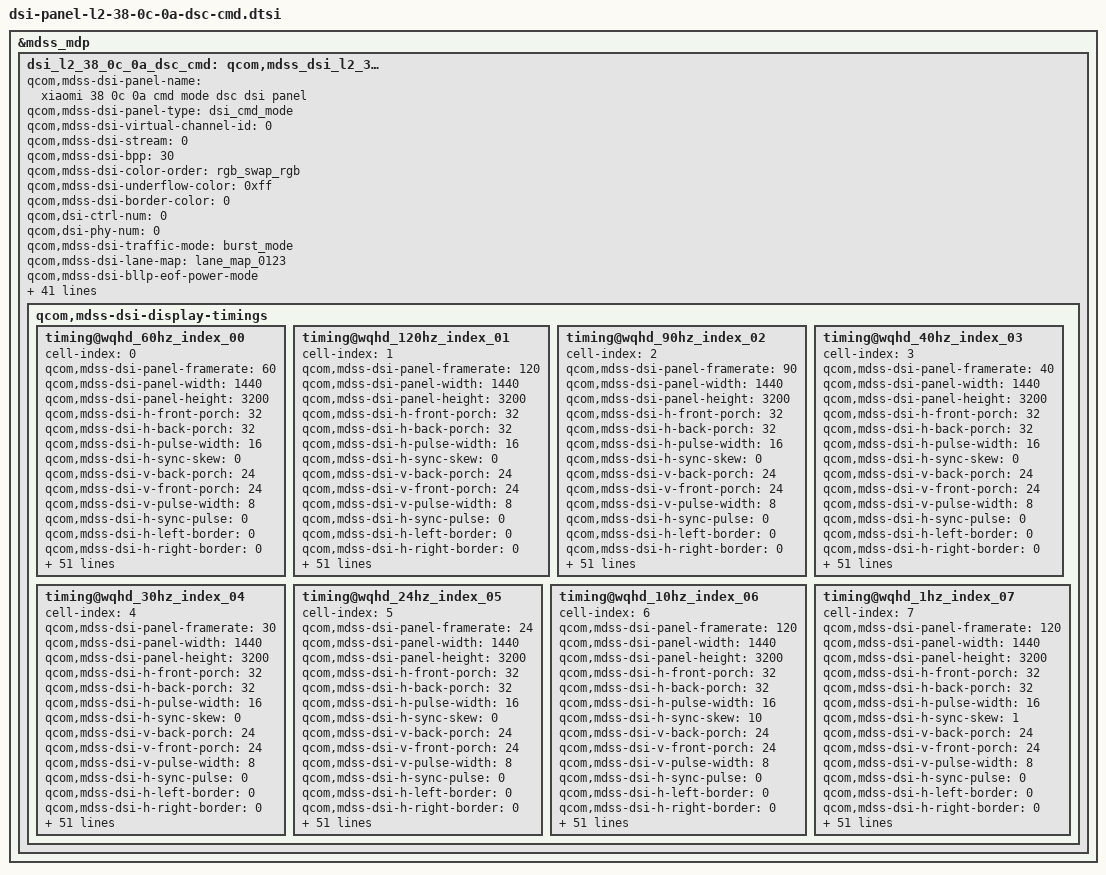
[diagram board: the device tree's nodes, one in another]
&mdss_mdp {
	dsi_l2_38_0c_0a_dsc_cmd: qcom,mdss_dsi_l2_38_0c_0a_dsc_cmd {
		qcom,mdss-dsi-panel-name = "xiaomi 38 0c 0a cmd mode dsc dsi panel";
		qcom,mdss-dsi-panel-type = "dsi_cmd_mode";
		qcom,mdss-dsi-virtual-channel-id = <0>;
		qcom,mdss-dsi-stream = <0>;
		qcom,mdss-dsi-bpp = <30>;
		qcom,mdss-dsi-color-order = "rgb_swap_rgb";
		qcom,mdss-dsi-underflow-color = <0xff>;
		qcom,mdss-dsi-border-color = <0>;
		qcom,dsi-ctrl-num = <0>;
		qcom,dsi-phy-num = <0>;

		qcom,mdss-dsi-traffic-mode = "burst_mode";
		qcom,mdss-dsi-lane-map = "lane_map_0123";
		qcom,mdss-dsi-bllp-eof-power-mode;
		qcom,mdss-dsi-bllp-power-mode;
		qcom,mdss-dsi-lane-0-state;
		qcom,mdss-dsi-lane-1-state;
		qcom,mdss-dsi-lane-2-state;
		qcom,mdss-dsi-lane-3-state;
		qcom,mdss-dsi-dma-trigger = "trigger_sw";
		qcom,mdss-dsi-mdp-trigger = "none";
		qcom,mdss-dsi-reset-sequence = <0 1>, <1 10>;
		qcom,mdss-pan-physical-width-dimension = <701>;
		qcom,mdss-pan-physical-height-dimension = <1558>;
		qcom,mdss-dsi-te-pin-select = <1>;
		qcom,mdss-dsi-wr-mem-start = <0x2c>;
		qcom,mdss-dsi-wr-mem-continue = <0x3c>;
		qcom,mdss-dsi-te-dcs-command = <1>;
		qcom,mdss-dsi-te-check-enable;
		qcom,mdss-dsi-te-using-te-pin;
		qcom,mdss-dsi-tx-eot-append;
		qcom,mdss-dsi-lp11-init;

		qcom,mdss-dsi-bl-inverted-dbv;
		qcom,mdss-dsi-panel-dimming-enabled;
		qcom,bl-update-flag = "delay_until_first_frame";

		qcom,mdss-dsi-panel-hdr-enabled;
		qcom,mdss-dsi-panel-hdr-color-primaries = <14500 15500 32000
			17000 15500 30000 8000 3000>;
		qcom,mdss-dsi-panel-peak-brightness = <4200000>;
		qcom,mdss-dsi-panel-blackness-level = <3230>;

		qcom,mdss-dsi-dma-schedule-line = <1>;
		qcom,mdss-dsi-dma-schedule-window = <50>;

		/* IRQF_ONESHOT | IRQF_TRIGGER_LOW */
		mi,esd-err-irq-gpio = <&tlmm 116 0x2008>;
		mi,panel-id = <0x00004C32 0x00380C00>;

		mi,local-hbm-enabled;
		mi,local-hbm-ui-ready-delay-num-frame = <4>; /* 4 frame */
		mi,fod-low-brightness-clone-threshold = <411>;
		mi,fod-low-brightness-lux-threshold = <1>;
		mi,need-fod-animal-in-normal-enabled;

		mi,panel-on-dimming-delay = <120>;
		mi,max-brightness-clone = <16383>;
		mi,normal-max-brightness-clone = <8191>;
		mi,thermal-dimming-flag;

		mi,doze-hbm-dbv-level = <229>;
		mi,doze-lbm-dbv-level = <16>;

		qcom,mdss-dsi-display-timings {
			timing@wqhd_60hz_index_00 {
				#include "dsi-panel-l2-38-0c-0a-dsc-cmd-common.dtsi"
				cell-index = <0>;
				qcom,mdss-dsi-panel-framerate = <60>;
				qcom,mdss-dsi-panel-width = <1440>;
				qcom,mdss-dsi-panel-height = <3200>;
				qcom,mdss-dsi-h-front-porch = <32>;
				qcom,mdss-dsi-h-back-porch = <32>;
				qcom,mdss-dsi-h-pulse-width = <16>;
				qcom,mdss-dsi-h-sync-skew = <0>;
				qcom,mdss-dsi-v-back-porch = <24>;
				qcom,mdss-dsi-v-front-porch = <24>;
				qcom,mdss-dsi-v-pulse-width = <8>;
				qcom,mdss-dsi-h-sync-pulse = <0>;
				qcom,mdss-dsi-h-left-border = <0>;
				qcom,mdss-dsi-h-right-border = <0>;
				qcom,mdss-dsi-v-top-border = <0>;
				qcom,mdss-dsi-v-bottom-border = <0>;
				qcom,mdss-dsi-panel-clockrate = <1360000000>;
				qcom,mdss-dsi-panel-jitter = <0x5 0x1>;
				qcom,mdss-mdp-transfer-time-us = <7300>;

				/* the cmd sequence sync TE */
				mi,mdss-dsi-exit-90fps-timing-switch-command = [
					/* CASET/PASET Setting 1440*3200 */
					39 00 00 60 00 00 05 2A 00 00 05 9F
					39 00 00 60 00 00 05 2B 00 00 0C 7F
					/* Scaler Setting 1440*3200 */
					39 00 00 60 00 00 03 F0 5A 5A
					39 00 00 60 00 00 02 C3 0C
					39 00 00 60 00 00 03 F0 A5 A5
					/* 90hz -> 120hz */
					39 00 00 60 00 00 03 F0 5A 5A
					39 00 00 60 00 00 02 60 00     /* 120hz */
					39 00 00 60 00 00 02 F7 0F
					39 00 00 20 05 00 03 F0 5A 5A  /* 1 sync */
					39 00 00 60 00 00 04 B0 00 08 CB
					39 00 00 60 00 00 02 CB 27
					39 00 00 60 00 00 02 F7 0F
					39 00 00 20 05 00 03 F0 A5 A5  /* 2 sync */
					39 00 00 60 00 00 03 F0 5A 5A
					39 00 00 60 00 00 02 60 01     /* 0x00:120Hz, 0x01:60Hz, 0x03:30Hz, 0x07:10Hz */
					39 00 00 20 00 00 02 F7 0F     /* 2 sync */
				];
				mi,mdss-dsi-exit-90fps-timing-switch-command-state = "dsi_hs_mode";

				qcom,mdss-dsi-timing-switch-command = [
					/* CASET/PASET Setting 1440*3200 */
					39 00 00 40 00 00 05 2A 00 00 05 9F
					39 00 00 40 00 00 05 2B 00 00 0C 7F
					/* Scaler Setting 1440*3200 */
					39 00 00 40 00 00 03 F0 5A 5A
					39 00 00 40 00 00 02 C3 0C
					39 00 00 40 00 00 03 F0 A5 A5
					/* FIX TE OFF */
					39 00 00 40 00 00 03 F0 5A 5A
					15 00 00 40 00 00 02 B9 00
					39 00 00 40 00 00 04 B0 00 06 B9
					39 00 00 40 00 00 07 B9 00 00 00 00 00 00
					39 00 00 40 00 00 02 F7 0F
					39 00 00 40 00 00 03 F0 A5 A5
					/* 60Hz Setting(force increasing off) */
					39 00 00 40 00 00 03 F0 5A 5A
					39 00 00 40 00 00 04 B0 00 08 CB
					39 00 00 40 00 00 02 CB 27
					39 00 00 40 00 00 03 BD 21 82
					39 00 00 40 00 00 04 B0 00 10 BD
					39 00 00 40 00 00 02 BD 00
					39 00 00 40 00 00 04 B0 00 21 BD
					39 00 00 40 00 00 0F BD 03 00 06 00 09 00 0C 00 0F 00 15 00 21 00
					39 00 00 40 00 00 04 B0 00 61 BD
					39 00 00 40 00 00 0A BD 04 00 08 00 0C 00 10 00 74
					39 00 00 40 00 00 04 B0 00 12 BD
					39 00 00 40 00 00 02 BD 01
					39 00 00 40 00 00 04 B0 00 16 BD
					39 00 00 40 00 00 03 BD 00 00    /* Step delay */
					39 00 00 40 00 00 02 BD 21       /* Manual mode */
					39 00 00 40 00 00 02 60 01       /* 0x00:120Hz, 0x01:60Hz, 0x03:30Hz, 0x07:10Hz */
					39 00 00 40 00 00 02 F7 0F
					39 00 00 00 00 00 03 F0 A5 A5
				];
				qcom,mdss-dsi-timing-switch-command-state = "dsi_hs_mode";

				qcom,mdss-dsi-on-command = [
					/* DSC PPS Setting */
					39 00 00 00 00 00 81 9E
						11 00 00 AB 30 80 0C 80 05 A0 00 19 02 D0 02 D0
						02 00 02 68 00 20 02 BE 00 0A 00 0C 04 00 03 0D
						18 00 10 F0 07 10 20 00 06 0F 0F 33 0E 1C 2A 38
						46 54 62 69 70 77 79 7B 7D 7E 01 02 22 00 2A 40
						2A BE 3A FC 3A FA 3A F8 3B 38 3B 78 3B B6 4B F6
						4C 34 4C 74 5C 74 8C F4 00 00 00 00 00 00 00 00
						00 00 00 00 00 00 00 00 00 00 00 00 00 00 00 00
						00 00 00 00 00 00 00 00 00 00 00 00 00 00 00 00
					/* DSC Compression Enable */
					15 00 00 00 00 00 02 9D 01
					/* Sleep Out */
					05 00 00 00 78 00 02 11 00
					/* Common Setting */
					/* TE(Vsync) On */
					15 00 00 00 00 00 02 35 00
					/* CASET/PASET Setting 1440*3200 */
					39 00 00 00 00 00 05 2A 00 00 05 9F
					39 00 00 00 00 00 05 2B 00 00 0C 7F
					/* Scaler Setting 1440*3200 */
					39 00 00 40 00 00 03 F0 5A 5A
					15 00 00 40 00 00 02 C3 0C    /* 0x0C:WQHD+(1440x3200), 0x0D:FHD+(1080x2400) */
					39 00 00 00 00 00 03 F0 A5 A5
					/* FIX TE OFF */
					39 00 00 40 00 00 03 F0 5A 5A
					15 00 00 40 00 00 02 B9 00
					39 00 00 40 00 00 04 B0 00 06 B9
					39 00 00 40 00 00 07 B9 00 00 00 00 00 00
					39 00 00 40 00 00 02 F7 0F
					39 00 00 00 00 00 03 F0 A5 A5
					/* 60Hz Setting(force increasing off) */
					39 00 00 40 00 00 03 F0 5A 5A
					39 00 00 40 00 00 04 B0 00 08 CB
					39 00 00 40 00 00 02 CB 27
					39 00 00 40 00 00 03 BD 21 82
					39 00 00 40 00 00 04 B0 00 10 BD
					39 00 00 40 00 00 02 BD 00
					39 00 00 40 00 00 04 B0 00 21 BD
					39 00 00 40 00 00 0F BD 03 00 06 00 09 00 0C 00 0F 00 15 00 21 00
					39 00 00 40 00 00 04 B0 00 61 BD
					39 00 00 40 00 00 0A BD 04 00 08 00 0C 00 10 00 74
					39 00 00 40 00 00 04 B0 00 12 BD
					39 00 00 40 00 00 02 BD 01
					39 00 00 40 00 00 04 B0 00 16 BD
					39 00 00 40 00 00 03 BD 00 00    /* Step delay */
					39 00 00 40 00 00 02 BD 21       /* Manual mode */
					39 00 00 40 00 00 02 60 01       /* 0x00:120Hz, 0x01:60Hz, 0x03:30Hz, 0x07:10Hz */
					39 00 00 40 00 00 02 F7 0F
					39 00 00 00 00 00 03 F0 A5 A5
					/* Dimming Setting*/
					39 00 00 00 00 00 03 F0 5A 5A
					39 00 00 00 00 00 04 B0 00 0D 63
					39 00 00 00 00 00 02 63 20
					39 00 00 00 00 00 04 B0 00 0C 63
					39 00 00 00 00 00 02 63 20
					39 00 00 00 00 00 03 F0 A5 A5
					39 00 00 00 00 00 02 53 20
					39 00 00 00 00 00 03 51 00 00
					39 00 00 00 00 00 02 F7 0F
					39 00 00 00 00 00 03 F0 A5 A5
					/* ESD Error Flag, Normal High, Error Low */
					39 00 00 40 00 00 03 F0 5A 5A
					39 00 00 40 00 00 04 B0 00 47 F4
					15 00 00 40 00 00 02 F4 01
					39 00 00 40 00 00 04 ED 47 05 20
					39 00 00 00 00 00 03 F0 A5 A5
					/* touch sync enable */
					39 00 00 40 00 00 03 F0 5A 5A
					39 00 00 40 00 00 03 F1 5A 5A
					39 00 00 40 00 00 04 B0 00 22 B9
					39 00 00 40 00 00 03 B9 B1 A1
					39 00 00 40 00 00 04 B0 00 05 F2
					15 00 00 40 00 00 02 F2 52
					15 00 00 40 00 00 02 F7 0F
					39 00 00 40 00 00 03 F1 A5 A5
					39 00 00 40 00 00 03 F0 A5 A5
					39 00 00 40 00 00 03 F0 5A 5A
					39 00 00 40 00 00 02 C3 0C
					39 00 00 00 00 00 03 F0 A5 A5
					/* DIA setting */
					39 00 00 40 00 00 03 F0 5A 5A
					39 00 00 40 00 00 04 B0 02 67 1D
					39 00 00 40 00 00 02 1D 81
					39 00 00 00 00 00 03 F0 A5 A5
					/* OPEC code */
					39 00 00 40 00 00 03 F0 5A 5A
					39 00 00 40 00 00 04 B0 00 52 1F
					39 00 00 40 00 00 02 1F 02
					39 00 00 40 00 00 04 B0 00 53 1F
					39 00 00 40 00 00 5F 1F
						07 01 00 02 B9 02 BA 07 A2 07 AA 12 C0 12 C1 1A
						BA 1B C0 1F E0 00 53 00 C3 03 43 07 A0 07 A1 07
						A2 07 A6 07 A8 07 AA 07 AC 07 AE 07 B0 07 B2 07
						B4 07 B6 00 03 00 A4 00 C0 00 D1 01 86 03 FF 07
						FF 30 30 35 40 35 30 40 40 35 80 80 80 0A 0F 14
						18 1E 3A 78 80 80 80 80 80 80 80 80 01 B1
					39 00 00 40 00 00 04 B0 00 78 BD
					39 00 00 40 00 00 02 BD 10
					39 00 00 00 00 00 02 F7 0F
					39 00 00 00 00 00 03 F0 A5 A5
					/* Display On */
					05 00 00 00 00 00 02 29 00
				];
				qcom,mdss-dsi-on-command-state = "dsi_lp_mode";

				qcom,mdss-dsi-nolp-command = [
					39 00 00 40 00 00 03 F0 5A 5A
					15 00 00 40 00 00 02 53 20
					39 00 00 40 00 00 03 51 00 00
					39 00 00 00 22 00 03 F0 A5 A5
					/* 60Hz Setting(force increasing off) */
					39 00 00 40 00 00 03 F0 5A 5A
					39 00 00 40 00 00 04 B0 00 08 CB
					39 00 00 40 00 00 02 CB 27
					39 00 00 40 00 00 03 BD 21 82
					39 00 00 40 00 00 04 B0 00 10 BD
					39 00 00 40 00 00 02 BD 00
					39 00 00 40 00 00 04 B0 00 21 BD
					39 00 00 40 00 00 0F BD 03 00 06 00 09 00 0C 00 0F 00 15 00 21 00
					39 00 00 40 00 00 04 B0 00 61 BD
					39 00 00 40 00 00 0A BD 04 00 08 00 0C 00 10 00 74
					39 00 00 40 00 00 04 B0 00 12 BD
					39 00 00 40 00 00 02 BD 01
					39 00 00 40 00 00 04 B0 00 16 BD
					39 00 00 40 00 00 03 BD 00 00    /* Step delay */
					39 00 00 40 00 00 02 BD 21       /* Manual mode */
					39 00 00 40 00 00 02 60 01       /* 0x00:120Hz, 0x01:60Hz, 0x03:30Hz, 0x07:10Hz */
					39 00 00 40 00 00 02 F7 0F
					39 00 00 00 00 00 03 F0 A5 A5
				];
				qcom,mdss-dsi-nolp-command-state = "dsi_lp_mode";

				mi,mdss-dsi-doze-hbm-command = [
					/* 120Hz Setting(force increasing off) */
					39 00 00 40 00 00 03 F0 5A 5A
					39 00 00 40 00 00 04 B0 00 08 CB
					39 00 00 40 00 00 02 CB 27
					39 00 00 40 00 00 03 BD 21 82
					39 00 00 40 00 00 04 B0 00 10 BD
					39 00 00 40 00 00 02 BD 00
					39 00 00 40 00 00 04 B0 00 21 BD
					39 00 00 40 00 00 0F BD 03 00 06 00 09 00 0C 00 0F 00 15 00 21 00
					39 00 00 40 00 00 04 B0 00 61 BD
					39 00 00 40 00 00 0A BD 04 00 08 00 0C 00 10 00 74
					39 00 00 40 00 00 04 B0 00 12 BD
					39 00 00 40 00 00 02 BD 01
					39 00 00 40 00 00 04 B0 00 16 BD
					39 00 00 40 00 00 03 BD 00 00    /* Step delay */
					39 00 00 40 00 00 02 BD 21       /* Manual mode */
					39 00 00 40 00 00 02 60 00       /* 0x00:120Hz, 0x01:60Hz, 0x03:30Hz, 0x07:10Hz */
					39 00 00 40 00 00 02 F7 0F
					39 00 00 00 11 00 03 F0 A5 A5
					/* AOD setting */
					39 00 00 20 00 00 03 51 00 E5
					39 00 00 20 00 00 03 51 00 E5
					39 00 00 60 00 00 03 F0 5A 5A
					39 00 00 60 00 00 02 BB 31
					39 00 00 60 00 00 02 F7 0F
					39 00 00 60 00 00 02 53 24
					39 00 00 20 00 00 03 51 07 FE
				];
				mi,mdss-dsi-doze-lbm-command = [
					/* 120Hz Setting(force increasing off) */
					39 00 00 40 00 00 03 F0 5A 5A
					39 00 00 40 00 00 04 B0 00 08 CB
					39 00 00 40 00 00 02 CB 27
					39 00 00 40 00 00 03 BD 21 82
					39 00 00 40 00 00 04 B0 00 10 BD
					39 00 00 40 00 00 02 BD 00
					39 00 00 40 00 00 04 B0 00 21 BD
					39 00 00 40 00 00 0F BD 03 00 06 00 09 00 0C 00 0F 00 15 00 21 00
					39 00 00 40 00 00 04 B0 00 61 BD
					39 00 00 40 00 00 0A BD 04 00 08 00 0C 00 10 00 74
					39 00 00 40 00 00 04 B0 00 12 BD
					39 00 00 40 00 00 02 BD 01
					39 00 00 40 00 00 04 B0 00 16 BD
					39 00 00 40 00 00 03 BD 00 00    /* Step delay */
					39 00 00 40 00 00 02 BD 21       /* Manual mode */
					39 00 00 40 00 00 02 60 00       /* 0x00:120Hz, 0x01:60Hz, 0x03:30Hz, 0x07:10Hz */
					39 00 00 40 00 00 02 F7 0F
					39 00 00 00 11 00 03 F0 A5 A5
					/* AOD setting */
					39 00 00 20 00 00 03 51 00 10
					39 00 00 20 00 00 03 51 00 10
					39 00 00 60 00 00 03 F0 5A 5A
					39 00 00 60 00 00 02 BB 31
					15 00 00 60 00 00 02 F7 0F
					39 00 00 20 00 00 02 53 24
					39 00 00 00 00 00 03 51 00 F6
				];
				/* <mipi_address  update_index  update_length> */
				mi,mdss-dsi-doze-lbm-command-update = <0x53 23 1>;
				mi,mdss-dsi-doze-hbm-command-state = "dsi_lp_mode";
				mi,mdss-dsi-doze-lbm-command-state = "dsi_lp_mode";

				mi,mdss-dsi-doze-hbm-nolp-command = [
					39 00 00 60 00 00 03 51 04 29
					39 00 00 20 23 00 02 53 20
					39 00 00 00 00 00 03 51 00 E5
					/* 60Hz Setting(force increasing off) */
					39 00 00 40 00 00 03 F0 5A 5A
					39 00 00 40 00 00 04 B0 00 08 CB
					39 00 00 40 00 00 02 CB 27
					39 00 00 40 00 00 03 BD 21 82
					39 00 00 40 00 00 04 B0 00 10 BD
					39 00 00 40 00 00 02 BD 00
					39 00 00 40 00 00 04 B0 00 21 BD
					39 00 00 40 00 00 0F BD 03 00 06 00 09 00 0C 00 0F 00 15 00 21 00
					39 00 00 40 00 00 04 B0 00 61 BD
					39 00 00 40 00 00 0A BD 04 00 08 00 0C 00 10 00 74
					39 00 00 40 00 00 04 B0 00 12 BD
					39 00 00 40 00 00 02 BD 01
					39 00 00 40 00 00 04 B0 00 16 BD
					39 00 00 40 00 00 03 BD 00 00    /* Step delay */
					39 00 00 40 00 00 02 BD 21       /* Manual mode */
					39 00 00 40 00 00 02 60 01       /* 0x00:120Hz, 0x01:60Hz, 0x03:30Hz, 0x07:10Hz */
					39 00 00 40 00 00 02 F7 0F
					39 00 00 00 00 00 03 F0 A5 A5
				];
				mi,mdss-dsi-doze-hbm-nolp-command-state = "dsi_lp_mode";

				mi,mdss-dsi-doze-lbm-nolp-command = [
					39 00 00 40 00 00 03 F0 5A 5A
					15 00 00 40 00 00 02 53 20
					39 00 00 40 00 00 03 51 00 10
					39 00 00 00 22 00 03 F0 A5 A5
					/* 60Hz Setting(force increasing off) */
					39 00 00 40 00 00 03 F0 5A 5A
					39 00 00 40 00 00 04 B0 00 08 CB
					39 00 00 40 00 00 02 CB 27
					39 00 00 40 00 00 03 BD 21 82
					39 00 00 40 00 00 04 B0 00 10 BD
					39 00 00 40 00 00 02 BD 00
					39 00 00 40 00 00 04 B0 00 21 BD
					39 00 00 40 00 00 0F BD 03 00 06 00 09 00 0C 00 0F 00 15 00 21 00
					39 00 00 40 00 00 04 B0 00 61 BD
					39 00 00 40 00 00 0A BD 04 00 08 00 0C 00 10 00 74
					39 00 00 40 00 00 04 B0 00 12 BD
					39 00 00 40 00 00 02 BD 01
					39 00 00 40 00 00 04 B0 00 16 BD
					39 00 00 40 00 00 03 BD 00 00    /* Step delay */
					39 00 00 40 00 00 02 BD 21       /* Manual mode */
					39 00 00 40 00 00 02 60 01       /* 0x00:120Hz, 0x01:60Hz, 0x03:30Hz, 0x07:10Hz */
					39 00 00 40 00 00 02 F7 0F
					39 00 00 00 00 00 03 F0 A5 A5
				];
				mi,mdss-dsi-doze-lbm-nolp-command-state = "dsi_lp_mode";

				mi,mdss-dsi-local-hbm-hlpm-white-1000nit-command = [
					/* nolp */
					39 00 00 40 00 00 03 F0 5A 5A
					39 00 00 40 00 00 02 53 20
					39 00 00 00 22 00 03 F0 A5 A5
					/* 60Hz Setting(force increasing off) */
					39 00 00 40 00 00 03 F0 5A 5A
					39 00 00 40 00 00 04 B0 00 08 CB
					39 00 00 40 00 00 02 CB 27
					39 00 00 40 00 00 03 BD 21 82
					39 00 00 40 00 00 04 B0 00 10 BD
					39 00 00 40 00 00 02 BD 00
					39 00 00 40 00 00 04 B0 00 21 BD
					39 00 00 40 00 00 0F BD 03 00 06 00 09 00 0C 00 0F 00 15 00 21 00
					39 00 00 40 00 00 04 B0 00 61 BD
					39 00 00 40 00 00 0A BD 04 00 08 00 0C 00 10 00 74
					39 00 00 40 00 00 04 B0 00 12 BD
					39 00 00 40 00 00 02 BD 01
					39 00 00 40 00 00 04 B0 00 16 BD
					39 00 00 40 00 00 03 BD 00 00    /* Step delay */
					39 00 00 40 00 00 02 BD 21       /* Manual mode */
					39 00 00 40 00 00 02 60 01       /* 0x00:120Hz, 0x01:60Hz, 0x03:30Hz, 0x07:10Hz */
					39 00 00 40 00 00 02 F7 0F
					39 00 00 00 00 00 03 F0 A5 A5
					/* Local HBM setting */
					39 00 00 40 00 00 03 F0 5A 5A
					39 00 00 40 00 00 04 B0 01 DC 1F
					39 00 00 40 00 00 10 1F
						02 00 00 00 00 24 09 1F 35 FA 3F 2D 09 AF 86
					39 00 00 40 00 00 04 B0 02 AC 66
					39 00 00 40 00 00 03 66 0F FF
					39 00 00 40 00 00 04 B0 01 6D 66
					39 00 00 40 00 00 13 66
						00 40 14 02 90 52 0A 41 48 1C 27 FF FF FF FF FF
						FF FF
					39 00 00 40 00 00 04 B0 01 59 66
					39 00 00 40 00 00 0B 66
						08 7A 9F F5 AF 08 7A 9F F5 AF    /* 1100nit */
					39 00 00 40 00 00 04 B0 01 B5 66
					39 00 00 40 00 00 37 66
						14 01 DE 2A 43 A2 4F 66 CC 80 08 00 80 08 00 80
						08 00 14 01 DE 2A 43 A2 4F 66 CC 80 08 00 80 08
						00 80 08 00 14 01 DE 2A 43 A2 4F 66 CC 80 08 00
						80 08 00 80 08 00
					39 00 00 40 00 00 04 B0 01 EB 66
					39 00 00 40 00 00 37 66
						14 61 EE 2A 43 A2 4F 66 CC 80 08 00 80 08 00 80
						08 00 14 61 EE 2A 43 A2 4F 66 CC 80 08 00 80 08
						00 80 08 00 14 61 EE 2A 43 A2 4F 66 CC 80 08 00
						80 08 00 80 08 00
					39 00 00 40 00 00 02 53 30    /* 0x30 Local HBM transition */
					39 00 00 00 00 00 03 F0 A5 A5
				];
				mi,mdss-dsi-local-hbm-hlpm-white-1000nit-command-state = "dsi_hs_mode";

				mi,mdss-dsi-local-hbm-hlpm-white-110nit-command = [
					/* nolp */
					39 00 00 40 00 00 03 F0 5A 5A
					39 00 00 40 00 00 02 53 20
					39 00 00 00 22 00 03 F0 A5 A5
					/* 60Hz Setting(force increasing off) */
					39 00 00 40 00 00 03 F0 5A 5A
					39 00 00 40 00 00 04 B0 00 08 CB
					39 00 00 40 00 00 02 CB 27
					39 00 00 40 00 00 03 BD 21 82
					39 00 00 40 00 00 04 B0 00 10 BD
					39 00 00 40 00 00 02 BD 00
					39 00 00 40 00 00 04 B0 00 21 BD
					39 00 00 40 00 00 0F BD 03 00 06 00 09 00 0C 00 0F 00 15 00 21 00
					39 00 00 40 00 00 04 B0 00 61 BD
					39 00 00 40 00 00 0A BD 04 00 08 00 0C 00 10 00 74
					39 00 00 40 00 00 04 B0 00 12 BD
					39 00 00 40 00 00 02 BD 01
					39 00 00 40 00 00 04 B0 00 16 BD
					39 00 00 40 00 00 03 BD 00 00    /* Step delay */
					39 00 00 40 00 00 02 BD 21       /* Manual mode */
					39 00 00 40 00 00 02 60 01       /* 0x00:120Hz, 0x01:60Hz, 0x03:30Hz, 0x07:10Hz */
					39 00 00 40 00 00 02 F7 0F
					39 00 00 00 00 00 03 F0 A5 A5
					/* Local HBM setting */
					39 00 00 40 00 00 03 F0 5A 5A
					39 00 00 40 00 00 04 B0 01 DC 1F
					39 00 00 40 00 00 10 1F
						02 00 00 00 00 24 09 1F 35 FA 3F 2D 09 AF 86
					39 00 00 40 00 00 04 B0 02 AC 66
					39 00 00 40 00 00 03 66 0F FF
					39 00 00 40 00 00 04 B0 01 6D 66
					39 00 00 40 00 00 13 66
						00 40 14 02 90 52 0A 41 48 1C 27 FF FF FF FF FF
						FF FF
					39 00 00 40 00 00 04 B0 01 59 66
					39 00 00 40 00 00 0B 66
						05 56 E0 83 E8 05 56 E0 83 E8    /* 110nit */
					39 00 00 40 00 00 04 B0 01 B5 66
					39 00 00 40 00 00 37 66
						14 01 DE 2A 43 A2 4F 66 CC 80 08 00 80 08 00 80
						08 00 14 01 DE 2A 43 A2 4F 66 CC 80 08 00 80 08
						00 80 08 00 14 01 DE 2A 43 A2 4F 66 CC 80 08 00
						80 08 00 80 08 00
					39 00 00 40 00 00 04 B0 01 EB 66
					39 00 00 40 00 00 37 66
						14 61 EE 2A 43 A2 4F 66 CC 80 08 00 80 08 00 80
						08 00 14 61 EE 2A 43 A2 4F 66 CC 80 08 00 80 08
						00 80 08 00 14 61 EE 2A 43 A2 4F 66 CC 80 08 00
						80 08 00 80 08 00
					39 00 00 40 00 00 02 53 30    /* 0x30 Local HBM transition */
					39 00 00 00 00 00 03 F0 A5 A5
				];
				mi,mdss-dsi-local-hbm-hlpm-white-110nit-command-state = "dsi_hs_mode";

				qcom,compression-mode = "dsc";
				qcom,mdss-dsc-slice-height = <50>;
				qcom,mdss-dsc-slice-width = <720>;
				qcom,mdss-dsc-slice-per-pkt = <2>;
				qcom,mdss-dsc-bit-per-component = <10>;
				qcom,mdss-dsc-bit-per-pixel = <8>;
				qcom,mdss-dsc-block-prediction-enable;
			};

			timing@wqhd_120hz_index_01 {
				#include "dsi-panel-l2-38-0c-0a-dsc-cmd-common.dtsi"
				cell-index = <1>;
				qcom,mdss-dsi-panel-framerate = <120>;
				qcom,mdss-dsi-panel-width = <1440>;
				qcom,mdss-dsi-panel-height = <3200>;
				qcom,mdss-dsi-h-front-porch = <32>;
				qcom,mdss-dsi-h-back-porch = <32>;
				qcom,mdss-dsi-h-pulse-width = <16>;
				qcom,mdss-dsi-h-sync-skew = <0>;
				qcom,mdss-dsi-v-back-porch = <24>;
				qcom,mdss-dsi-v-front-porch = <24>;
				qcom,mdss-dsi-v-pulse-width = <8>;
				qcom,mdss-dsi-h-sync-pulse = <0>;
				qcom,mdss-dsi-h-left-border = <0>;
				qcom,mdss-dsi-h-right-border = <0>;
				qcom,mdss-dsi-v-top-border = <0>;
				qcom,mdss-dsi-v-bottom-border = <0>;
				qcom,mdss-dsi-panel-clockrate = <1360000000>;
				qcom,mdss-dsi-panel-jitter = <0x5 0x1>;
				qcom,mdss-mdp-transfer-time-us = <7300>;

				/* the cmd sequence sync TE */
				mi,mdss-dsi-exit-90fps-timing-switch-command = [
					/* CASET/PASET Setting 1440*3200 */
					39 00 00 60 00 00 05 2A 00 00 05 9F
					39 00 00 60 00 00 05 2B 00 00 0C 7F
					/* Scaler Setting 1440*3200 */
					39 00 00 60 00 00 03 F0 5A 5A
					39 00 00 60 00 00 02 C3 0C
					39 00 00 60 00 00 03 F0 A5 A5
					/* 90hz -> 120hz */
					39 00 00 60 00 00 03 F0 5A 5A
					39 00 00 60 00 00 02 60 00        /* 120hz */
					39 00 00 20 05 00 02 F7 0F        /* 1 sync */
					39 00 00 60 00 00 04 B0 00 08 CB
					39 00 00 60 00 00 02 CB 27
					39 00 00 60 00 00 02 F7 0F
					39 00 00 20 00 00 03 F0 A5 A5     /* 2 sync */
				];
				mi,mdss-dsi-exit-90fps-timing-switch-command-state = "dsi_hs_mode";

				qcom,mdss-dsi-timing-switch-command = [
					/* CASET/PASET Setting 1440*3200 */
					39 00 00 40 00 00 05 2A 00 00 05 9F
					39 00 00 40 00 00 05 2B 00 00 0C 7F
					/* Scaler Setting 1440*3200 */
					39 00 00 40 00 00 03 F0 5A 5A
					39 00 00 40 00 00 02 C3 0C
					39 00 00 40 00 00 03 F0 A5 A5
					/* FIX TE OFF */
					39 00 00 40 00 00 03 F0 5A 5A
					15 00 00 40 00 00 02 B9 00
					39 00 00 40 00 00 04 B0 00 06 B9
					39 00 00 40 00 00 07 B9 00 00 00 00 00 00
					39 00 00 40 00 00 02 F7 0F
					39 00 00 40 00 00 03 F0 A5 A5
					/* 120Hz Setting(force increasing off) */
					39 00 00 40 00 00 03 F0 5A 5A
					39 00 00 40 00 00 04 B0 00 08 CB
					39 00 00 40 00 00 02 CB 27
					39 00 00 40 00 00 03 BD 21 82
					39 00 00 40 00 00 04 B0 00 10 BD
					39 00 00 40 00 00 02 BD 00
					39 00 00 40 00 00 04 B0 00 21 BD
					39 00 00 40 00 00 0F BD 03 00 06 00 09 00 0C 00 0F 00 15 00 21 00
					39 00 00 40 00 00 04 B0 00 61 BD
					39 00 00 40 00 00 0A BD 04 00 08 00 0C 00 10 00 74
					39 00 00 40 00 00 04 B0 00 12 BD
					39 00 00 40 00 00 02 BD 01
					39 00 00 40 00 00 04 B0 00 16 BD
					39 00 00 40 00 00 03 BD 00 00    /* Step delay */
					39 00 00 40 00 00 02 BD 21       /* Manual mode */
					39 00 00 40 00 00 02 60 00       /* 0x00:120Hz, 0x01:60Hz, 0x03:30Hz, 0x07:10Hz */
					39 00 00 40 00 00 02 F7 0F
					39 00 00 00 00 00 03 F0 A5 A5
				];
				qcom,mdss-dsi-timing-switch-command-state = "dsi_hs_mode";

				qcom,mdss-dsi-on-command = [
					/* DSC PPS Setting */
					39 00 00 00 00 00 81 9E
						11 00 00 AB 30 80 0C 80 05 A0 00 19 02 D0 02 D0
						02 00 02 68 00 20 02 BE 00 0A 00 0C 04 00 03 0D
						18 00 10 F0 07 10 20 00 06 0F 0F 33 0E 1C 2A 38
						46 54 62 69 70 77 79 7B 7D 7E 01 02 22 00 2A 40
						2A BE 3A FC 3A FA 3A F8 3B 38 3B 78 3B B6 4B F6
						4C 34 4C 74 5C 74 8C F4 00 00 00 00 00 00 00 00
						00 00 00 00 00 00 00 00 00 00 00 00 00 00 00 00
						00 00 00 00 00 00 00 00 00 00 00 00 00 00 00 00
					/* DSC Compression Enable */
					15 00 00 00 00 00 02 9D 01
					/* Sleep Out */
					05 00 00 00 78 00 02 11 00
					/* Common Setting */
					/* TE(Vsync) On */
					15 00 00 00 00 00 02 35 00
					/* CASET/PASET Setting 1440*3200 */
					39 00 00 00 00 00 05 2A 00 00 05 9F
					39 00 00 00 00 00 05 2B 00 00 0C 7F
					/* Scaler Setting 1440*3200 */
					39 00 00 40 00 00 03 F0 5A 5A
					15 00 00 40 00 00 02 C3 0C    /* 0x0C:WQHD+(1440x3200), 0x0D:FHD+(1080x2400) */
					39 00 00 00 00 00 03 F0 A5 A5
					/* FIX TE OFF */
					39 00 00 40 00 00 03 F0 5A 5A
					15 00 00 40 00 00 02 B9 00
					39 00 00 40 00 00 04 B0 00 06 B9
					39 00 00 40 00 00 07 B9 00 00 00 00 00 00
					39 00 00 40 00 00 02 F7 0F
					39 00 00 00 00 00 03 F0 A5 A5
					/* 120Hz Setting(force increasing off) */
					39 00 00 40 00 00 03 F0 5A 5A
					39 00 00 40 00 00 04 B0 00 08 CB
					39 00 00 40 00 00 02 CB 27
					39 00 00 40 00 00 03 BD 21 82
					39 00 00 40 00 00 04 B0 00 10 BD
					39 00 00 40 00 00 02 BD 00
					39 00 00 40 00 00 04 B0 00 21 BD
					39 00 00 40 00 00 0F BD 03 00 06 00 09 00 0C 00 0F 00 15 00 21 00
					39 00 00 40 00 00 04 B0 00 61 BD
					39 00 00 40 00 00 0A BD 04 00 08 00 0C 00 10 00 74
					39 00 00 40 00 00 04 B0 00 12 BD
					39 00 00 40 00 00 02 BD 01
					39 00 00 40 00 00 04 B0 00 16 BD
					39 00 00 40 00 00 03 BD 00 00    /* Step delay */
					39 00 00 40 00 00 02 BD 21       /* Manual mode */
					39 00 00 40 00 00 02 60 00       /* 0x00:120Hz, 0x01:60Hz, 0x03:30Hz, 0x07:10Hz */
					39 00 00 40 00 00 02 F7 0F
					39 00 00 00 00 00 03 F0 A5 A5
					/* Dimming Setting*/
					39 00 00 00 00 00 03 F0 5A 5A
					39 00 00 00 00 00 04 B0 00 0D 63
					39 00 00 00 00 00 02 63 20
					39 00 00 00 00 00 04 B0 00 0C 63
					39 00 00 00 00 00 02 63 20
					39 00 00 00 00 00 03 F0 A5 A5
					39 00 00 00 00 00 02 53 20
					39 00 00 00 00 00 03 51 00 00
					39 00 00 00 00 00 02 F7 0F
					39 00 00 00 00 00 03 F0 A5 A5
					/* ESD Error Flag, Normal High, Error Low */
					39 00 00 40 00 00 03 F0 5A 5A
					39 00 00 40 00 00 04 B0 00 47 F4
					15 00 00 40 00 00 02 F4 01
					39 00 00 40 00 00 04 ED 47 05 20
					39 00 00 00 00 00 03 F0 A5 A5
					/* touch sync enable */
					39 00 00 40 00 00 03 F0 5A 5A
					39 00 00 40 00 00 03 F1 5A 5A
					39 00 00 40 00 00 04 B0 00 22 B9
					39 00 00 40 00 00 03 B9 B1 A1
					39 00 00 40 00 00 04 B0 00 05 F2
					15 00 00 40 00 00 02 F2 52
					15 00 00 40 00 00 02 F7 0F
					39 00 00 40 00 00 03 F1 A5 A5
					39 00 00 40 00 00 03 F0 A5 A5
					39 00 00 40 00 00 03 F0 5A 5A
					39 00 00 40 00 00 02 C3 0C
					39 00 00 00 00 00 03 F0 A5 A5
					/* DIA setting */
					39 00 00 40 00 00 03 F0 5A 5A
					39 00 00 40 00 00 04 B0 02 67 1D
					39 00 00 40 00 00 02 1D 81
					39 00 00 00 00 00 03 F0 A5 A5
					/* OPEC code */
					39 00 00 40 00 00 03 F0 5A 5A
					39 00 00 40 00 00 04 B0 00 52 1F
					39 00 00 40 00 00 02 1F 02
					39 00 00 40 00 00 04 B0 00 53 1F
					39 00 00 40 00 00 5F 1F
						07 01 00 02 B9 02 BA 07 A2 07 AA 12 C0 12 C1 1A
						BA 1B C0 1F E0 00 53 00 C3 03 43 07 A0 07 A1 07
						A2 07 A6 07 A8 07 AA 07 AC 07 AE 07 B0 07 B2 07
						B4 07 B6 00 03 00 A4 00 C0 00 D1 01 86 03 FF 07
						FF 30 30 35 40 35 30 40 40 35 80 80 80 0A 0F 14
						18 1E 3A 78 80 80 80 80 80 80 80 80 01 B1
					39 00 00 40 00 00 04 B0 00 78 BD
					39 00 00 40 00 00 02 BD 10
					39 00 00 00 00 00 02 F7 0F
					39 00 00 00 00 00 03 F0 A5 A5
					/* Display On */
					05 00 00 00 00 00 02 29 00
				];
				qcom,mdss-dsi-on-command-state = "dsi_lp_mode";

				qcom,mdss-dsi-nolp-command = [
					39 00 00 40 00 00 03 F0 5A 5A
					15 00 00 40 00 00 02 53 20
					39 00 00 40 00 00 03 51 00 00
					39 00 00 00 22 00 03 F0 A5 A5
				];
				qcom,mdss-dsi-nolp-command-state = "dsi_lp_mode";

				mi,mdss-dsi-doze-hbm-command = [
					39 00 00 20 00 00 03 51 00 E5
					39 00 00 20 00 00 03 51 00 E5
					39 00 00 60 00 00 03 F0 5A 5A
					39 00 00 60 00 00 02 BB 31
					39 00 00 60 00 00 02 F7 0F
					39 00 00 60 00 00 02 53 24
					39 00 00 20 00 00 03 51 07 FE
				];
				mi,mdss-dsi-doze-lbm-command = [
					39 00 00 20 00 00 03 51 00 10
					39 00 00 20 00 00 03 51 00 10
					39 00 00 60 00 00 03 F0 5A 5A
					39 00 00 60 00 00 02 BB 31
					15 00 00 60 00 00 02 F7 0F
					39 00 00 20 00 00 02 53 24
					39 00 00 00 00 00 03 51 00 F6
				];
				/* <mipi_address  update_index  update_length> */
				mi,mdss-dsi-doze-lbm-command-update = <0x53 5 1>;
				mi,mdss-dsi-doze-hbm-command-state = "dsi_lp_mode";
				mi,mdss-dsi-doze-lbm-command-state = "dsi_lp_mode";

				mi,mdss-dsi-doze-hbm-nolp-command = [
					39 00 00 60 00 00 03 51 04 29
					39 00 00 20 23 00 02 53 20
					39 00 00 00 00 00 03 51 00 E5
				];
				mi,mdss-dsi-doze-hbm-nolp-command-state = "dsi_lp_mode";

				mi,mdss-dsi-doze-lbm-nolp-command = [
					39 00 00 20 23 00 02 53 20
					39 00 00 00 00 00 03 51 00 10
				];
				mi,mdss-dsi-doze-lbm-nolp-command-state = "dsi_lp_mode";

				mi,mdss-dsi-local-hbm-hlpm-white-1000nit-command = [
					/* nolp */
					39 00 00 40 00 00 03 F0 5A 5A
					39 00 00 40 00 00 02 53 20
					39 00 00 00 22 00 03 F0 A5 A5
					/* Local HBM setting */
					39 00 00 40 00 00 03 F0 5A 5A
					39 00 00 40 00 00 04 B0 01 DC 1F
					39 00 00 40 00 00 10 1F
						02 00 00 00 00 24 09 1F 35 FA 3F 2D 09 AF 86
					39 00 00 40 00 00 04 B0 02 AC 66
					39 00 00 40 00 00 03 66 0F FF
					39 00 00 40 00 00 04 B0 01 6D 66
					39 00 00 40 00 00 13 66
						00 40 14 02 90 52 0A 41 48 1C 27 FF FF FF FF FF
						FF FF
					39 00 00 40 00 00 04 B0 01 59 66
					39 00 00 40 00 00 0B 66
						08 7A 9F F5 AF 08 7A 9F F5 AF    /* 1100nit */
					39 00 00 40 00 00 04 B0 01 B5 66
					39 00 00 40 00 00 37 66
						14 01 DE 2A 43 A2 4F 66 CC 80 08 00 80 08 00 80
						08 00 14 01 DE 2A 43 A2 4F 66 CC 80 08 00 80 08
						00 80 08 00 14 01 DE 2A 43 A2 4F 66 CC 80 08 00
						80 08 00 80 08 00
					39 00 00 40 00 00 04 B0 01 EB 66
					39 00 00 40 00 00 37 66
						14 61 EE 2A 43 A2 4F 66 CC 80 08 00 80 08 00 80
						08 00 14 61 EE 2A 43 A2 4F 66 CC 80 08 00 80 08
						00 80 08 00 14 61 EE 2A 43 A2 4F 66 CC 80 08 00
						80 08 00 80 08 00
					39 00 00 40 00 00 02 53 30    /* 0x30 Local HBM transition */
					39 00 00 00 00 00 03 F0 A5 A5
				];
				mi,mdss-dsi-local-hbm-hlpm-white-1000nit-command-state = "dsi_hs_mode";

				mi,mdss-dsi-local-hbm-hlpm-white-110nit-command = [
					/* nolp */
					39 00 00 40 00 00 03 F0 5A 5A
					39 00 00 40 00 00 02 53 20
					39 00 00 00 22 00 03 F0 A5 A5
					/* Local HBM setting */
					39 00 00 40 00 00 03 F0 5A 5A
					39 00 00 40 00 00 04 B0 01 DC 1F
					39 00 00 40 00 00 10 1F
						02 00 00 00 00 24 09 1F 35 FA 3F 2D 09 AF 86
					39 00 00 40 00 00 04 B0 02 AC 66
					39 00 00 40 00 00 03 66 0F FF
					39 00 00 40 00 00 04 B0 01 6D 66
					39 00 00 40 00 00 13 66
						00 40 14 02 90 52 0A 41 48 1C 27 FF FF FF FF FF
						FF FF
					39 00 00 40 00 00 04 B0 01 59 66
					39 00 00 40 00 00 0B 66
						05 56 E0 83 E8 05 56 E0 83 E8    /* 110nit */
					39 00 00 40 00 00 04 B0 01 B5 66
					39 00 00 40 00 00 37 66
						14 01 DE 2A 43 A2 4F 66 CC 80 08 00 80 08 00 80
						08 00 14 01 DE 2A 43 A2 4F 66 CC 80 08 00 80 08
						00 80 08 00 14 01 DE 2A 43 A2 4F 66 CC 80 08 00
						80 08 00 80 08 00
					39 00 00 40 00 00 04 B0 01 EB 66
					39 00 00 40 00 00 37 66
						14 61 EE 2A 43 A2 4F 66 CC 80 08 00 80 08 00 80
						08 00 14 61 EE 2A 43 A2 4F 66 CC 80 08 00 80 08
						00 80 08 00 14 61 EE 2A 43 A2 4F 66 CC 80 08 00
						80 08 00 80 08 00
					39 00 00 40 00 00 02 53 30    /* 0x30 Local HBM transition */
					39 00 00 00 00 00 03 F0 A5 A5
				];
				mi,mdss-dsi-local-hbm-hlpm-white-110nit-command-state = "dsi_hs_mode";

				qcom,compression-mode = "dsc";
				qcom,mdss-dsc-slice-height = <50>;
				qcom,mdss-dsc-slice-width = <720>;
				qcom,mdss-dsc-slice-per-pkt = <2>;
				qcom,mdss-dsc-bit-per-component = <10>;
				qcom,mdss-dsc-bit-per-pixel = <8>;
				qcom,mdss-dsc-block-prediction-enable;
			};

			timing@wqhd_90hz_index_02 {
				#include "dsi-panel-l2-38-0c-0a-dsc-cmd-common.dtsi"
				cell-index = <2>;
				qcom,mdss-dsi-panel-framerate = <90>;
				qcom,mdss-dsi-panel-width = <1440>;
				qcom,mdss-dsi-panel-height = <3200>;
				qcom,mdss-dsi-h-front-porch = <32>;
				qcom,mdss-dsi-h-back-porch = <32>;
				qcom,mdss-dsi-h-pulse-width = <16>;
				qcom,mdss-dsi-h-sync-skew = <0>;
				qcom,mdss-dsi-v-back-porch = <24>;
				qcom,mdss-dsi-v-front-porch = <24>;
				qcom,mdss-dsi-v-pulse-width = <8>;
				qcom,mdss-dsi-h-sync-pulse = <0>;
				qcom,mdss-dsi-h-left-border = <0>;
				qcom,mdss-dsi-h-right-border = <0>;
				qcom,mdss-dsi-v-top-border = <0>;
				qcom,mdss-dsi-v-bottom-border = <0>;
				qcom,mdss-dsi-panel-clockrate = <1360000000>;
				qcom,mdss-dsi-panel-jitter = <0x5 0x1>;
				qcom,mdss-mdp-transfer-time-us = <7300>;

				/* Display resolution switching */
				/* the cmd sequence sync TE */
				mi,mdss-dsi-exit-90fps-timing-switch-command = [
					/* 120Hz Setting(force increasing off) */
					39 00 00 60 00 00 03 F0 5A 5A
					39 00 00 60 00 00 04 B0 00 08 CB
					39 00 00 60 00 00 02 CB 27
					39 00 00 60 00 00 03 BD 21 82
					39 00 00 60 00 00 04 B0 00 10 BD
					39 00 00 60 00 00 02 BD 00
					39 00 00 60 00 00 04 B0 00 21 BD
					39 00 00 60 00 00 0F BD 03 00 06 00 09 00 0C 00 0F 00 15 00 21 00
					39 00 00 60 00 00 04 B0 00 61 BD
					39 00 00 60 00 00 0A BD 04 00 08 00 0C 00 10 00 74
					39 00 00 60 00 00 04 B0 00 12 BD
					39 00 00 60 00 00 02 BD 01
					39 00 00 60 00 00 04 B0 00 16 BD
					39 00 00 60 00 00 03 BD 00 00    /* Step delay */
					39 00 00 60 00 00 02 BD 21       /* Manual mode */
					39 00 00 60 00 00 02 60 00       /* 0x00:120Hz, 0x01:60Hz, 0x03:30Hz, 0x07:10Hz */
					39 00 00 60 00 00 02 F7 0F
					39 00 00 20 05 00 03 F0 A5 A5    /* 1 sync */
					/* CASET/PASET Setting 1440*3200 */
					39 00 00 60 00 00 05 2A 00 00 05 9F
					39 00 00 60 00 00 05 2B 00 00 0C 7F
					/* Scaler Setting 1440*3200 */
					39 00 00 60 00 00 03 F0 5A 5A
					39 00 00 60 00 00 02 C3 0C
					39 00 00 60 00 00 03 F0 A5 A5
					/* 90 hz setting */
					39 00 00 60 00 00 03 F0 5A 5A
					39 00 00 60 00 00 04 B0 00 08 CB
					39 00 00 60 00 00 02 CB A7
					39 00 00 60 00 00 04 B0 00 10 BD
					39 00 00 60 00 00 02 BD 00
					39 00 00 60 00 00 03 BD 21 82
					39 00 00 60 00 00 02 60 08       /* 0x08:90Hz */
					39 00 00 60 00 00 02 F7 0F
					39 00 00 20 00 00 03 F0 A5 A5    /* 2 sync */
				];
				mi,mdss-dsi-exit-90fps-timing-switch-command-state = "dsi_hs_mode";

				/* the cmd sequence sync TE */
				qcom,mdss-dsi-timing-switch-command = [
					/* CASET/PASET Setting 1440*3200 */
					39 00 00 60 00 00 05 2A 00 00 05 9F
					39 00 00 60 00 00 05 2B 00 00 0C 7F
					/* Scaler Setting 1440*3200 */
					39 00 00 60 00 00 03 F0 5A 5A
					39 00 00 60 00 00 02 C3 0C
					39 00 00 60 00 00 03 F0 A5 A5
					/* FIX TE OFF */
					39 00 00 60 00 00 03 F0 5A 5A
					15 00 00 60 00 00 02 B9 00
					39 00 00 60 00 00 04 B0 00 06 B9
					39 00 00 60 00 00 07 B9 00 00 00 00 00 00
					39 00 00 60 00 00 02 F7 0F
					39 00 00 60 00 00 03 F0 A5 A5
					/* 120Hz Setting(force increasing off) */
					39 00 00 60 00 00 03 F0 5A 5A
					39 00 00 60 00 00 04 B0 00 08 CB
					39 00 00 60 00 00 02 CB 27
					39 00 00 60 00 00 03 BD 21 82
					39 00 00 60 00 00 04 B0 00 10 BD
					39 00 00 60 00 00 02 BD 00
					39 00 00 60 00 00 04 B0 00 21 BD
					39 00 00 60 00 00 0F BD 03 00 06 00 09 00 0C 00 0F 00 15 00 21 00
					39 00 00 60 00 00 04 B0 00 61 BD
					39 00 00 60 00 00 0A BD 04 00 08 00 0C 00 10 00 74
					39 00 00 60 00 00 04 B0 00 12 BD
					39 00 00 60 00 00 02 BD 01
					39 00 00 60 00 00 04 B0 00 16 BD
					39 00 00 60 00 00 03 BD 00 00    /* Step delay */
					39 00 00 60 00 00 02 BD 21       /* Manual mode */
					39 00 00 60 00 00 02 60 00       /* 0x00:120Hz, 0x01:60Hz, 0x03:30Hz, 0x07:10Hz */
					39 00 00 20 05 00 02 F7 0F       /* 1 sync */
					/* 90 hz setting */
					39 00 00 60 00 00 03 F0 5A 5A
					39 00 00 60 00 00 04 B0 00 08 CB
					39 00 00 60 00 00 02 CB A7
					39 00 00 60 00 00 04 B0 00 10 BD
					39 00 00 60 00 00 02 BD 00
					39 00 00 60 00 00 03 BD 21 82
					39 00 00 60 00 00 02 60 08       /* 0x08:90Hz */
					39 00 00 60 00 00 02 F7 0F
					39 00 00 20 00 00 03 F0 A5 A5    /* 2 sync */
				];
				qcom,mdss-dsi-timing-switch-command-state = "dsi_hs_mode";

				qcom,mdss-dsi-on-command = [
					/* DSC PPS Setting */
					39 00 00 00 00 00 81 9E
						11 00 00 AB 30 80 0C 80 05 A0 00 19 02 D0 02 D0
						02 00 02 68 00 20 02 BE 00 0A 00 0C 04 00 03 0D
						18 00 10 F0 07 10 20 00 06 0F 0F 33 0E 1C 2A 38
						46 54 62 69 70 77 79 7B 7D 7E 01 02 22 00 2A 40
						2A BE 3A FC 3A FA 3A F8 3B 38 3B 78 3B B6 4B F6
						4C 34 4C 74 5C 74 8C F4 00 00 00 00 00 00 00 00
						00 00 00 00 00 00 00 00 00 00 00 00 00 00 00 00
						00 00 00 00 00 00 00 00 00 00 00 00 00 00 00 00
					/* DSC Compression Enable */
					15 00 00 00 00 00 02 9D 01
					/* Sleep Out */
					05 00 00 00 78 00 02 11 00
					/* Common Setting */
					/* TE(Vsync) On */
					15 00 00 00 00 00 02 35 00
					/* CASET/PASET Setting 1440*3200 */
					39 00 00 00 00 00 05 2A 00 00 05 9F
					39 00 00 00 00 00 05 2B 00 00 0C 7F
					/* Scaler Setting 1440*3200 */
					39 00 00 40 00 00 03 F0 5A 5A
					15 00 00 40 00 00 02 C3 0C    /* 0x0C:WQHD+(1440x3200), 0x0D:FHD+(1080x2400) */
					39 00 00 00 00 00 03 F0 A5 A5
					/* FIX TE OFF */
					39 00 00 40 00 00 03 F0 5A 5A
					15 00 00 40 00 00 02 B9 00
					39 00 00 40 00 00 04 B0 00 06 B9
					39 00 00 40 00 00 07 B9 00 00 00 00 00 00
					39 00 00 40 00 00 02 F7 0F
					39 00 00 00 00 00 03 F0 A5 A5
					/* 120Hz Setting(force increasing off) */
					39 00 00 40 00 00 03 F0 5A 5A
					39 00 00 40 00 00 04 B0 00 08 CB
					39 00 00 40 00 00 02 CB 27
					39 00 00 40 00 00 03 BD 21 82
					39 00 00 40 00 00 04 B0 00 10 BD
					39 00 00 40 00 00 02 BD 00
					39 00 00 40 00 00 04 B0 00 21 BD
					39 00 00 40 00 00 0F BD 03 00 06 00 09 00 0C 00 0F 00 15 00 21 00
					39 00 00 40 00 00 04 B0 00 61 BD
					39 00 00 40 00 00 0A BD 04 00 08 00 0C 00 10 00 74
					39 00 00 40 00 00 04 B0 00 12 BD
					39 00 00 40 00 00 02 BD 01
					39 00 00 40 00 00 04 B0 00 16 BD
					39 00 00 40 00 00 03 BD 00 00    /* Step delay */
					39 00 00 40 00 00 02 BD 21       /* Manual mode */
					39 00 00 40 00 00 02 60 00       /* 0x00:120Hz, 0x01:60Hz, 0x03:30Hz, 0x07:10Hz */
					/* 90 hz setting */
					39 00 00 40 00 00 04 B0 00 08 CB
					39 00 00 40 00 00 02 CB A7
					39 00 00 40 00 00 04 B0 00 10 BD
					39 00 00 40 00 00 02 BD 00
					39 00 00 40 00 00 03 BD 21 82
					39 00 00 40 00 00 02 60 08       /* 0x08:90Hz */
					39 00 00 40 00 00 02 F7 0F
					39 00 00 00 00 00 03 F0 A5 A5
					/* Dimming Setting*/
					39 00 00 00 00 00 03 F0 5A 5A
					39 00 00 00 00 00 04 B0 00 0D 63
					39 00 00 00 00 00 02 63 20
					39 00 00 00 00 00 04 B0 00 0C 63
					39 00 00 00 00 00 02 63 20
					39 00 00 00 00 00 03 F0 A5 A5
					39 00 00 00 00 00 02 53 20
					39 00 00 00 00 00 03 51 00 00
					39 00 00 00 00 00 02 F7 0F
					39 00 00 00 00 00 03 F0 A5 A5
					/* ESD Error Flag, Normal High, Error Low */
					39 00 00 40 00 00 03 F0 5A 5A
					39 00 00 40 00 00 04 B0 00 47 F4
					15 00 00 40 00 00 02 F4 01
					39 00 00 40 00 00 04 ED 47 05 20
					39 00 00 00 00 00 03 F0 A5 A5
					/* touch sync enable */
					39 00 00 40 00 00 03 F0 5A 5A
					39 00 00 40 00 00 03 F1 5A 5A
					39 00 00 40 00 00 04 B0 00 22 B9
					39 00 00 40 00 00 03 B9 B1 A1
					39 00 00 40 00 00 04 B0 00 05 F2
					15 00 00 40 00 00 02 F2 52
					15 00 00 40 00 00 02 F7 0F
					39 00 00 40 00 00 03 F1 A5 A5
					39 00 00 40 00 00 03 F0 A5 A5
					39 00 00 40 00 00 03 F0 5A 5A
					39 00 00 40 00 00 02 C3 0C
					39 00 00 00 00 00 03 F0 A5 A5
					/* DIA setting */
					39 00 00 40 00 00 03 F0 5A 5A
					39 00 00 40 00 00 04 B0 02 67 1D
					39 00 00 40 00 00 02 1D 81
					39 00 00 00 00 00 03 F0 A5 A5
					/* OPEC code */
					39 00 00 40 00 00 03 F0 5A 5A
					39 00 00 40 00 00 04 B0 00 52 1F
					39 00 00 40 00 00 02 1F 02
					39 00 00 40 00 00 04 B0 00 53 1F
					39 00 00 40 00 00 5F 1F
						07 01 00 02 B9 02 BA 07 A2 07 AA 12 C0 12 C1 1A
						BA 1B C0 1F E0 00 53 00 C3 03 43 07 A0 07 A1 07
						A2 07 A6 07 A8 07 AA 07 AC 07 AE 07 B0 07 B2 07
						B4 07 B6 00 03 00 A4 00 C0 00 D1 01 86 03 FF 07
						FF 30 30 35 40 35 30 40 40 35 80 80 80 0A 0F 14
						18 1E 3A 78 80 80 80 80 80 80 80 80 01 B1
					39 00 00 40 00 00 04 B0 00 78 BD
					39 00 00 40 00 00 02 BD 10
					39 00 00 00 00 00 02 F7 0F
					39 00 00 00 00 00 03 F0 A5 A5
					/* Display On */
					05 00 00 00 00 00 02 29 00
				];
				qcom,mdss-dsi-on-command-state = "dsi_lp_mode";

				qcom,mdss-dsi-nolp-command = [
					39 00 00 40 00 00 03 F0 5A 5A
					15 00 00 40 00 00 02 53 20
					39 00 00 40 00 00 03 51 00 00
					39 00 00 00 22 00 03 F0 A5 A5
					/* 90 hz setting */
					39 00 00 60 00 00 03 F0 5A 5A
					39 00 00 60 00 00 04 B0 00 08 CB
					39 00 00 60 00 00 02 CB A7
					39 00 00 60 00 00 04 B0 00 10 BD
					39 00 00 60 00 00 02 BD 00
					39 00 00 60 00 00 03 BD 21 82
					39 00 00 60 00 00 02 60 08		 /* 0x08:90Hz */
					39 00 00 60 00 00 02 F7 0F
					39 00 00 20 00 00 03 F0 A5 A5	 /* 2 sync */
				];
				qcom,mdss-dsi-nolp-command-state = "dsi_lp_mode";

				mi,mdss-dsi-doze-hbm-command = [
					/* 120Hz Setting(force increasing off) */
					39 00 00 40 00 00 03 F0 5A 5A
					39 00 00 40 00 00 04 B0 00 08 CB
					39 00 00 40 00 00 02 CB 27
					39 00 00 40 00 00 03 BD 21 82
					39 00 00 40 00 00 04 B0 00 10 BD
					39 00 00 40 00 00 02 BD 00
					39 00 00 40 00 00 04 B0 00 21 BD
					39 00 00 40 00 00 0F BD 03 00 06 00 09 00 0C 00 0F 00 15 00 21 00
					39 00 00 40 00 00 04 B0 00 61 BD
					39 00 00 40 00 00 0A BD 04 00 08 00 0C 00 10 00 74
					39 00 00 40 00 00 04 B0 00 12 BD
					39 00 00 40 00 00 02 BD 01
					39 00 00 40 00 00 04 B0 00 16 BD
					39 00 00 40 00 00 03 BD 00 00    /* Step delay */
					39 00 00 40 00 00 02 BD 21       /* Manual mode */
					39 00 00 40 00 00 02 60 00       /* 0x00:120Hz, 0x01:60Hz, 0x03:30Hz, 0x07:10Hz */
					39 00 00 40 00 00 02 F7 0F
					39 00 00 00 0B 00 03 F0 A5 A5
					/* AOD setting */
					39 00 00 20 00 00 03 51 00 E5
					39 00 00 20 00 00 03 51 00 E5
					39 00 00 60 00 00 03 F0 5A 5A
					39 00 00 60 00 00 02 BB 31
					39 00 00 60 00 00 02 F7 0F
					39 00 00 60 00 00 02 53 24
					39 00 00 20 00 00 03 51 07 FE
				];
				mi,mdss-dsi-doze-lbm-command = [
					/* 120Hz Setting(force increasing off) */
					39 00 00 40 00 00 03 F0 5A 5A
					39 00 00 40 00 00 04 B0 00 08 CB
					39 00 00 40 00 00 02 CB 27
					39 00 00 40 00 00 03 BD 21 82
					39 00 00 40 00 00 04 B0 00 10 BD
					39 00 00 40 00 00 02 BD 00
					39 00 00 40 00 00 04 B0 00 21 BD
					39 00 00 40 00 00 0F BD 03 00 06 00 09 00 0C 00 0F 00 15 00 21 00
					39 00 00 40 00 00 04 B0 00 61 BD
					39 00 00 40 00 00 0A BD 04 00 08 00 0C 00 10 00 74
					39 00 00 40 00 00 04 B0 00 12 BD
					39 00 00 40 00 00 02 BD 01
					39 00 00 40 00 00 04 B0 00 16 BD
					39 00 00 40 00 00 03 BD 00 00    /* Step delay */
					39 00 00 40 00 00 02 BD 21       /* Manual mode */
					39 00 00 40 00 00 02 60 00       /* 0x00:120Hz, 0x01:60Hz, 0x03:30Hz, 0x07:10Hz */
					39 00 00 40 00 00 02 F7 0F
					39 00 00 00 0B 00 03 F0 A5 A5
					/* AOD setting */
					39 00 00 20 00 00 03 51 00 10
					39 00 00 20 00 00 03 51 00 10
					39 00 00 60 00 00 03 F0 5A 5A
					39 00 00 60 00 00 02 BB 31
					15 00 00 60 00 00 02 F7 0F
					39 00 00 20 00 00 02 53 24
					39 00 00 00 00 00 03 51 00 F6
				];
				/* <mipi_address  update_index  update_length> */
				mi,mdss-dsi-doze-lbm-command-update = <0x53 23 1>;
				mi,mdss-dsi-doze-hbm-command-state = "dsi_lp_mode";
				mi,mdss-dsi-doze-lbm-command-state = "dsi_lp_mode";

				mi,mdss-dsi-doze-hbm-nolp-command = [
					39 00 00 60 00 00 03 51 04 29
					39 00 00 20 23 00 02 53 20
					39 00 00 00 00 00 03 51 00 E5
					/* 90 hz setting */
					39 00 00 60 00 00 03 F0 5A 5A
					39 00 00 60 00 00 04 B0 00 08 CB
					39 00 00 60 00 00 02 CB A7
					39 00 00 60 00 00 04 B0 00 10 BD
					39 00 00 60 00 00 02 BD 00
					39 00 00 60 00 00 03 BD 21 82
					39 00 00 60 00 00 02 60 08		 /* 0x08:90Hz */
					39 00 00 60 00 00 02 F7 0F
					39 00 00 20 00 00 03 F0 A5 A5	 /* 2 sync */
				];
				mi,mdss-dsi-doze-hbm-nolp-command-state = "dsi_lp_mode";

				mi,mdss-dsi-doze-lbm-nolp-command = [
					39 00 00 40 00 00 03 F0 5A 5A
					15 00 00 40 00 00 02 53 20
					39 00 00 40 00 00 03 51 00 10
					39 00 00 00 22 00 03 F0 A5 A5
					/* 90 hz setting */
					39 00 00 60 00 00 03 F0 5A 5A
					39 00 00 60 00 00 04 B0 00 08 CB
					39 00 00 60 00 00 02 CB A7
					39 00 00 60 00 00 04 B0 00 10 BD
					39 00 00 60 00 00 02 BD 00
					39 00 00 60 00 00 03 BD 21 82
					39 00 00 60 00 00 02 60 08		 /* 0x08:90Hz */
					39 00 00 60 00 00 02 F7 0F
					39 00 00 20 00 00 03 F0 A5 A5	 /* 2 sync */
				];
				mi,mdss-dsi-doze-lbm-nolp-command-state = "dsi_lp_mode";

				mi,mdss-dsi-local-hbm-hlpm-white-1000nit-command = [
					/* nolp */
					39 00 00 40 00 00 03 F0 5A 5A
					39 00 00 40 00 00 02 53 20
					39 00 00 00 22 00 03 F0 A5 A5
					/* 90 hz setting */
					39 00 00 60 00 00 03 F0 5A 5A
					39 00 00 60 00 00 04 B0 00 08 CB
					39 00 00 60 00 00 02 CB A7
					39 00 00 60 00 00 04 B0 00 10 BD
					39 00 00 60 00 00 02 BD 00
					39 00 00 60 00 00 03 BD 21 82
					39 00 00 60 00 00 02 60 08		 /* 0x08:90Hz */
					39 00 00 60 00 00 02 F7 0F
					39 00 00 20 00 00 03 F0 A5 A5	 /* 2 sync */
					/* Local HBM setting */
					39 00 00 40 00 00 03 F0 5A 5A
					39 00 00 40 00 00 04 B0 01 DC 1F
					39 00 00 40 00 00 10 1F
						02 00 00 00 00 24 09 1F 35 FA 3F 2D 09 AF 86
					39 00 00 40 00 00 04 B0 02 AC 66
					39 00 00 40 00 00 03 66 0F FF
					39 00 00 40 00 00 04 B0 01 6D 66
					39 00 00 40 00 00 13 66
						00 40 14 02 90 52 0A 41 48 1C 27 FF FF FF FF FF
						FF FF
					39 00 00 40 00 00 04 B0 01 59 66
					39 00 00 40 00 00 0B 66
						08 7A 9F F5 AF 08 7A 9F F5 AF    /* 1100nit */
					39 00 00 40 00 00 04 B0 01 B5 66
					39 00 00 40 00 00 37 66
						14 01 DE 2A 43 A2 4F 66 CC 80 08 00 80 08 00 80
						08 00 14 01 DE 2A 43 A2 4F 66 CC 80 08 00 80 08
						00 80 08 00 14 01 DE 2A 43 A2 4F 66 CC 80 08 00
						80 08 00 80 08 00
					39 00 00 40 00 00 04 B0 01 EB 66
					39 00 00 40 00 00 37 66
						14 61 EE 2A 43 A2 4F 66 CC 80 08 00 80 08 00 80
						08 00 14 61 EE 2A 43 A2 4F 66 CC 80 08 00 80 08
						00 80 08 00 14 61 EE 2A 43 A2 4F 66 CC 80 08 00
						80 08 00 80 08 00
					39 00 00 40 00 00 02 53 30    /* 0x30 Local HBM transition */
					39 00 00 00 00 00 03 F0 A5 A5
				];
				mi,mdss-dsi-local-hbm-hlpm-white-1000nit-command-state = "dsi_hs_mode";

				mi,mdss-dsi-local-hbm-hlpm-white-110nit-command = [
					/* nolp */
					39 00 00 40 00 00 03 F0 5A 5A
					39 00 00 40 00 00 02 53 20
					39 00 00 00 22 00 03 F0 A5 A5
					/* 90 hz setting */
					39 00 00 60 00 00 03 F0 5A 5A
					39 00 00 60 00 00 04 B0 00 08 CB
					39 00 00 60 00 00 02 CB A7
					39 00 00 60 00 00 04 B0 00 10 BD
					39 00 00 60 00 00 02 BD 00
					39 00 00 60 00 00 03 BD 21 82
					39 00 00 60 00 00 02 60 08		 /* 0x08:90Hz */
					39 00 00 60 00 00 02 F7 0F
					39 00 00 20 00 00 03 F0 A5 A5	 /* 2 sync */
					/* Local HBM setting */
					39 00 00 40 00 00 03 F0 5A 5A
					39 00 00 40 00 00 04 B0 01 DC 1F
					39 00 00 40 00 00 10 1F
						02 00 00 00 00 24 09 1F 35 FA 3F 2D 09 AF 86
					39 00 00 40 00 00 04 B0 02 AC 66
					39 00 00 40 00 00 03 66 0F FF
					39 00 00 40 00 00 04 B0 01 6D 66
					39 00 00 40 00 00 13 66
						00 40 14 02 90 52 0A 41 48 1C 27 FF FF FF FF FF
						FF FF
					39 00 00 40 00 00 04 B0 01 59 66
					39 00 00 40 00 00 0B 66
						05 56 E0 83 E8 05 56 E0 83 E8    /* 110nit */
					39 00 00 40 00 00 04 B0 01 B5 66
					39 00 00 40 00 00 37 66
						14 01 DE 2A 43 A2 4F 66 CC 80 08 00 80 08 00 80
						08 00 14 01 DE 2A 43 A2 4F 66 CC 80 08 00 80 08
						00 80 08 00 14 01 DE 2A 43 A2 4F 66 CC 80 08 00
						80 08 00 80 08 00
					39 00 00 40 00 00 04 B0 01 EB 66
					39 00 00 40 00 00 37 66
						14 61 EE 2A 43 A2 4F 66 CC 80 08 00 80 08 00 80
						08 00 14 61 EE 2A 43 A2 4F 66 CC 80 08 00 80 08
						00 80 08 00 14 61 EE 2A 43 A2 4F 66 CC 80 08 00
						80 08 00 80 08 00
					39 00 00 40 00 00 02 53 30    /* 0x30 Local HBM transition */
					39 00 00 00 00 00 03 F0 A5 A5
				];
				mi,mdss-dsi-local-hbm-hlpm-white-110nit-command-state = "dsi_hs_mode";

				qcom,compression-mode = "dsc";
				qcom,mdss-dsc-slice-height = <50>;
				qcom,mdss-dsc-slice-width = <720>;
				qcom,mdss-dsc-slice-per-pkt = <2>;
				qcom,mdss-dsc-bit-per-component = <10>;
				qcom,mdss-dsc-bit-per-pixel = <8>;
				qcom,mdss-dsc-block-prediction-enable;
			};

			timing@wqhd_40hz_index_03 {
				#include "dsi-panel-l2-38-0c-0a-dsc-cmd-common.dtsi"
				cell-index = <3>;
				qcom,mdss-dsi-panel-framerate = <40>;
				qcom,mdss-dsi-panel-width = <1440>;
				qcom,mdss-dsi-panel-height = <3200>;
				qcom,mdss-dsi-h-front-porch = <32>;
				qcom,mdss-dsi-h-back-porch = <32>;
				qcom,mdss-dsi-h-pulse-width = <16>;
				qcom,mdss-dsi-h-sync-skew = <0>;
				qcom,mdss-dsi-v-back-porch = <24>;
				qcom,mdss-dsi-v-front-porch = <24>;
				qcom,mdss-dsi-v-pulse-width = <8>;
				qcom,mdss-dsi-h-sync-pulse = <0>;
				qcom,mdss-dsi-h-left-border = <0>;
				qcom,mdss-dsi-h-right-border = <0>;
				qcom,mdss-dsi-v-top-border = <0>;
				qcom,mdss-dsi-v-bottom-border = <0>;
				qcom,mdss-dsi-panel-clockrate = <1360000000>;
				qcom,mdss-dsi-panel-jitter = <0x5 0x1>;
				qcom,mdss-mdp-transfer-time-us = <7300>;

				/* the cmd sequence sync TE */
				mi,mdss-dsi-exit-90fps-timing-switch-command = [
					/* CASET/PASET Setting 1440*3200 */
					39 00 00 60 00 00 05 2A 00 00 05 9F
					39 00 00 60 00 00 05 2B 00 00 0C 7F
					/* Scaler Setting 1440*3200 */
					39 00 00 60 00 00 03 F0 5A 5A
					39 00 00 60 00 00 02 C3 0C
					39 00 00 60 00 00 03 F0 A5 A5
					/* 90hz -> 40hz */
					39 00 00 60 00 00 03 F0 5A 5A
					39 00 00 60 00 00 02 60 00     /* 120hz */
					39 00 00 60 00 00 02 F7 0F
					39 00 00 20 05 00 03 F0 5A 5A  /* 1 sync */
					39 00 00 60 00 00 04 B0 00 08 CB
					39 00 00 60 00 00 02 CB 27
					39 00 00 60 00 00 02 F7 0F
					39 00 00 20 05 00 03 F0 A5 A5  /* 2 sync */
					39 00 00 60 00 00 03 F0 5A 5A
					39 00 00 60 00 00 02 60 02     /* 0x00:120Hz, 0x01:60Hz, 0x02:40Hz, 0x03:30Hz, 0x07:10Hz */
					39 00 00 20 00 00 02 F7 0F     /* 3 sync */
				];
				mi,mdss-dsi-exit-90fps-timing-switch-command-state = "dsi_hs_mode";

				qcom,mdss-dsi-timing-switch-command = [
					/* CASET/PASET Setting 1440*3200 */
					39 00 00 40 00 00 05 2A 00 00 05 9F
					39 00 00 40 00 00 05 2B 00 00 0C 7F
					/* Scaler Setting 1440*3200 */
					39 00 00 40 00 00 03 F0 5A 5A
					39 00 00 40 00 00 02 C3 0C
					39 00 00 40 00 00 03 F0 A5 A5
					/* FIX TE OFF */
					39 00 00 40 00 00 03 F0 5A 5A
					15 00 00 40 00 00 02 B9 00
					39 00 00 40 00 00 04 B0 00 06 B9
					39 00 00 40 00 00 07 B9 00 00 00 00 00 00
					39 00 00 40 00 00 02 F7 0F
					39 00 00 40 00 00 03 F0 A5 A5
					/* 40Hz Setting(force increasing off) */
					39 00 00 40 00 00 03 F0 5A 5A
					39 00 00 40 00 00 04 B0 00 08 CB
					39 00 00 40 00 00 02 CB 27
					39 00 00 40 00 00 03 BD 21 82
					39 00 00 40 00 00 04 B0 00 10 BD
					39 00 00 40 00 00 02 BD 00
					39 00 00 40 00 00 04 B0 00 21 BD
					39 00 00 40 00 00 0F BD 03 00 06 00 09 00 0C 00 0F 00 15 00 21 00
					39 00 00 40 00 00 04 B0 00 61 BD
					39 00 00 40 00 00 0A BD 04 00 08 00 0C 00 10 00 74
					39 00 00 40 00 00 04 B0 00 12 BD
					39 00 00 40 00 00 02 BD 01
					39 00 00 40 00 00 04 B0 00 16 BD
					39 00 00 40 00 00 03 BD 00 00    /* Step delay */
					39 00 00 40 00 00 02 BD 21       /* Manual mode */
					39 00 00 40 00 00 02 60 02       /* 0x00:120Hz, 0x01:60Hz, 0x02:40Hz, 0x03:30Hz, 0x07:10Hz */
					39 00 00 40 00 00 02 F7 0F
					39 00 00 00 00 00 03 F0 A5 A5
				];
				qcom,mdss-dsi-timing-switch-command-state = "dsi_hs_mode";

				qcom,mdss-dsi-on-command = [
					/* DSC PPS Setting */
					39 00 00 00 00 00 81 9E
						11 00 00 AB 30 80 0C 80 05 A0 00 19 02 D0 02 D0
						02 00 02 68 00 20 02 BE 00 0A 00 0C 04 00 03 0D
						18 00 10 F0 07 10 20 00 06 0F 0F 33 0E 1C 2A 38
						46 54 62 69 70 77 79 7B 7D 7E 01 02 22 00 2A 40
						2A BE 3A FC 3A FA 3A F8 3B 38 3B 78 3B B6 4B F6
						4C 34 4C 74 5C 74 8C F4 00 00 00 00 00 00 00 00
						00 00 00 00 00 00 00 00 00 00 00 00 00 00 00 00
						00 00 00 00 00 00 00 00 00 00 00 00 00 00 00 00
					/* DSC Compression Enable */
					15 00 00 00 00 00 02 9D 01
					/* Sleep Out */
					05 00 00 00 78 00 02 11 00
					/* Common Setting */
					/* TE(Vsync) On */
					15 00 00 00 00 00 02 35 00
					/* CASET/PASET Setting 1440*3200 */
					39 00 00 00 00 00 05 2A 00 00 05 9F
					39 00 00 00 00 00 05 2B 00 00 0C 7F
					/* Scaler Setting 1440*3200 */
					39 00 00 40 00 00 03 F0 5A 5A
					15 00 00 40 00 00 02 C3 0C    /* 0x0C:WQHD+(1440x3200), 0x0D:FHD+(1080x2400) */
					39 00 00 00 00 00 03 F0 A5 A5
					/* FIX TE OFF */
					39 00 00 40 00 00 03 F0 5A 5A
					15 00 00 40 00 00 02 B9 00
					39 00 00 40 00 00 04 B0 00 06 B9
					39 00 00 40 00 00 07 B9 00 00 00 00 00 00
					39 00 00 40 00 00 02 F7 0F
					39 00 00 00 00 00 03 F0 A5 A5
					/* 40Hz Setting(force increasing off) */
					39 00 00 40 00 00 03 F0 5A 5A
					39 00 00 40 00 00 04 B0 00 08 CB
					39 00 00 40 00 00 02 CB 27
					39 00 00 40 00 00 03 BD 21 82
					39 00 00 40 00 00 04 B0 00 10 BD
					39 00 00 40 00 00 02 BD 00
					39 00 00 40 00 00 04 B0 00 21 BD
					39 00 00 40 00 00 0F BD 03 00 06 00 09 00 0C 00 0F 00 15 00 21 00
					39 00 00 40 00 00 04 B0 00 61 BD
					39 00 00 40 00 00 0A BD 04 00 08 00 0C 00 10 00 74
					39 00 00 40 00 00 04 B0 00 12 BD
					39 00 00 40 00 00 02 BD 01
					39 00 00 40 00 00 04 B0 00 16 BD
					39 00 00 40 00 00 03 BD 00 00    /* Step delay */
					39 00 00 40 00 00 02 BD 21       /* Manual mode */
					39 00 00 40 00 00 02 60 02       /* 0x00:120Hz, 0x01:60Hz, 0x02:40Hz 0x03:30Hz, 0x07:10Hz */
					39 00 00 40 00 00 02 F7 0F
					39 00 00 00 00 00 03 F0 A5 A5
					/* Dimming Setting*/
					39 00 00 00 00 00 03 F0 5A 5A
					39 00 00 00 00 00 04 B0 00 0D 63
					39 00 00 00 00 00 02 63 20
					39 00 00 00 00 00 04 B0 00 0C 63
					39 00 00 00 00 00 02 63 20
					39 00 00 00 00 00 03 F0 A5 A5
					39 00 00 00 00 00 02 53 20
					39 00 00 00 00 00 03 51 00 00
					39 00 00 00 00 00 02 F7 0F
					39 00 00 00 00 00 03 F0 A5 A5
					/* ESD Error Flag, Normal High, Error Low */
					39 00 00 40 00 00 03 F0 5A 5A
					39 00 00 40 00 00 04 B0 00 47 F4
					15 00 00 40 00 00 02 F4 01
					39 00 00 40 00 00 04 ED 47 05 20
					39 00 00 00 00 00 03 F0 A5 A5
					/* touch sync enable */
					39 00 00 40 00 00 03 F0 5A 5A
					39 00 00 40 00 00 03 F1 5A 5A
					39 00 00 40 00 00 04 B0 00 22 B9
					39 00 00 40 00 00 03 B9 B1 A1
					39 00 00 40 00 00 04 B0 00 05 F2
					15 00 00 40 00 00 02 F2 52
					15 00 00 40 00 00 02 F7 0F
					39 00 00 40 00 00 03 F1 A5 A5
					39 00 00 40 00 00 03 F0 A5 A5
					39 00 00 40 00 00 03 F0 5A 5A
					39 00 00 40 00 00 02 C3 0C
					39 00 00 00 00 00 03 F0 A5 A5
					/* DIA setting */
					39 00 00 40 00 00 03 F0 5A 5A
					39 00 00 40 00 00 04 B0 02 67 1D
					39 00 00 40 00 00 02 1D 81
					39 00 00 00 00 00 03 F0 A5 A5
					/* OPEC code */
					39 00 00 40 00 00 03 F0 5A 5A
					39 00 00 40 00 00 04 B0 00 52 1F
					39 00 00 40 00 00 02 1F 02
					39 00 00 40 00 00 04 B0 00 53 1F
					39 00 00 40 00 00 5F 1F
						07 01 00 02 B9 02 BA 07 A2 07 AA 12 C0 12 C1 1A
						BA 1B C0 1F E0 00 53 00 C3 03 43 07 A0 07 A1 07
						A2 07 A6 07 A8 07 AA 07 AC 07 AE 07 B0 07 B2 07
						B4 07 B6 00 03 00 A4 00 C0 00 D1 01 86 03 FF 07
						FF 30 30 35 40 35 30 40 40 35 80 80 80 0A 0F 14
						18 1E 3A 78 80 80 80 80 80 80 80 80 01 B1
					39 00 00 40 00 00 04 B0 00 78 BD
					39 00 00 40 00 00 02 BD 10
					39 00 00 00 00 00 02 F7 0F
					39 00 00 00 00 00 03 F0 A5 A5
					/* Display On */
					05 00 00 00 00 00 02 29 00
				];
				qcom,mdss-dsi-on-command-state = "dsi_lp_mode";

				qcom,mdss-dsi-nolp-command = [
					39 00 00 40 00 00 03 F0 5A 5A
					15 00 00 40 00 00 02 53 20
					39 00 00 40 00 00 03 51 00 00
					39 00 00 00 22 00 03 F0 A5 A5
					/* 40Hz Setting(force increasing off) */
					39 00 00 40 00 00 03 F0 5A 5A
					39 00 00 40 00 00 04 B0 00 08 CB
					39 00 00 40 00 00 02 CB 27
					39 00 00 40 00 00 03 BD 21 82
					39 00 00 40 00 00 04 B0 00 10 BD
					39 00 00 40 00 00 02 BD 00
					39 00 00 40 00 00 04 B0 00 21 BD
					39 00 00 40 00 00 0F BD 03 00 06 00 09 00 0C 00 0F 00 15 00 21 00
					39 00 00 40 00 00 04 B0 00 61 BD
					39 00 00 40 00 00 0A BD 04 00 08 00 0C 00 10 00 74
					39 00 00 40 00 00 04 B0 00 12 BD
					39 00 00 40 00 00 02 BD 01
					39 00 00 40 00 00 04 B0 00 16 BD
					39 00 00 40 00 00 03 BD 00 00    /* Step delay */
					39 00 00 40 00 00 02 BD 21       /* Manual mode */
					39 00 00 40 00 00 02 60 02       /* 0x00:120Hz, 0x01:60Hz, 0x02:40Hz, 0x03:30Hz, 0x07:10Hz */
					39 00 00 40 00 00 02 F7 0F
					39 00 00 00 00 00 03 F0 A5 A5
				];
				qcom,mdss-dsi-nolp-command-state = "dsi_lp_mode";

				mi,mdss-dsi-doze-hbm-command = [
					/* 120Hz Setting(force increasing off) */
					39 00 00 40 00 00 03 F0 5A 5A
					39 00 00 40 00 00 04 B0 00 08 CB
					39 00 00 40 00 00 02 CB 27
					39 00 00 40 00 00 03 BD 21 82
					39 00 00 40 00 00 04 B0 00 10 BD
					39 00 00 40 00 00 02 BD 00
					39 00 00 40 00 00 04 B0 00 21 BD
					39 00 00 40 00 00 0F BD 03 00 06 00 09 00 0C 00 0F 00 15 00 21 00
					39 00 00 40 00 00 04 B0 00 61 BD
					39 00 00 40 00 00 0A BD 04 00 08 00 0C 00 10 00 74
					39 00 00 40 00 00 04 B0 00 12 BD
					39 00 00 40 00 00 02 BD 01
					39 00 00 40 00 00 04 B0 00 16 BD
					39 00 00 40 00 00 03 BD 00 00    /* Step delay */
					39 00 00 40 00 00 02 BD 21       /* Manual mode */
					39 00 00 40 00 00 02 60 00       /* 0x00:120Hz, 0x01:60Hz, 0x03:30Hz, 0x07:10Hz */
					39 00 00 40 00 00 02 F7 0F
					39 00 00 00 19 00 03 F0 A5 A5
					/* AOD setting */
					39 00 00 20 00 00 03 51 00 E5
					39 00 00 20 00 00 03 51 00 E5
					39 00 00 60 00 00 03 F0 5A 5A
					39 00 00 60 00 00 02 BB 31
					39 00 00 60 00 00 02 F7 0F
					39 00 00 60 00 00 02 53 24
					39 00 00 20 00 00 03 51 07 FE
				];
				mi,mdss-dsi-doze-lbm-command = [
					/* 120Hz Setting(force increasing off) */
					39 00 00 40 00 00 03 F0 5A 5A
					39 00 00 40 00 00 04 B0 00 08 CB
					39 00 00 40 00 00 02 CB 27
					39 00 00 40 00 00 03 BD 21 82
					39 00 00 40 00 00 04 B0 00 10 BD
					39 00 00 40 00 00 02 BD 00
					39 00 00 40 00 00 04 B0 00 21 BD
					39 00 00 40 00 00 0F BD 03 00 06 00 09 00 0C 00 0F 00 15 00 21 00
					39 00 00 40 00 00 04 B0 00 61 BD
					39 00 00 40 00 00 0A BD 04 00 08 00 0C 00 10 00 74
					39 00 00 40 00 00 04 B0 00 12 BD
					39 00 00 40 00 00 02 BD 01
					39 00 00 40 00 00 04 B0 00 16 BD
					39 00 00 40 00 00 03 BD 00 00    /* Step delay */
					39 00 00 40 00 00 02 BD 21       /* Manual mode */
					39 00 00 40 00 00 02 60 00       /* 0x00:120Hz, 0x01:60Hz, 0x03:30Hz, 0x07:10Hz */
					39 00 00 40 00 00 02 F7 0F
					39 00 00 00 19 00 03 F0 A5 A5
					/* AOD setting */
					39 00 00 20 00 00 03 51 00 10
					39 00 00 20 00 00 03 51 00 10
					39 00 00 60 00 00 03 F0 5A 5A
					39 00 00 60 00 00 02 BB 31
					15 00 00 60 00 00 02 F7 0F
					39 00 00 20 00 00 02 53 24
					39 00 00 00 00 00 03 51 00 F6
				];
				/* <mipi_address  update_index  update_length> */
				mi,mdss-dsi-doze-lbm-command-update = <0x53 23 1>;
				mi,mdss-dsi-doze-hbm-command-state = "dsi_lp_mode";
				mi,mdss-dsi-doze-lbm-command-state = "dsi_lp_mode";

				mi,mdss-dsi-doze-hbm-nolp-command = [
					39 00 00 60 00 00 03 51 04 29
					39 00 00 20 23 00 02 53 20
					39 00 00 00 00 00 03 51 00 E5
					/* 40Hz Setting(force increasing off) */
					39 00 00 40 00 00 03 F0 5A 5A
					39 00 00 40 00 00 04 B0 00 08 CB
					39 00 00 40 00 00 02 CB 27
					39 00 00 40 00 00 03 BD 21 82
					39 00 00 40 00 00 04 B0 00 10 BD
					39 00 00 40 00 00 02 BD 00
					39 00 00 40 00 00 04 B0 00 21 BD
					39 00 00 40 00 00 0F BD 03 00 06 00 09 00 0C 00 0F 00 15 00 21 00
					39 00 00 40 00 00 04 B0 00 61 BD
					39 00 00 40 00 00 0A BD 04 00 08 00 0C 00 10 00 74
					39 00 00 40 00 00 04 B0 00 12 BD
					39 00 00 40 00 00 02 BD 01
					39 00 00 40 00 00 04 B0 00 16 BD
					39 00 00 40 00 00 03 BD 00 00    /* Step delay */
					39 00 00 40 00 00 02 BD 21       /* Manual mode */
					39 00 00 40 00 00 02 60 02       /* 0x00:120Hz, 0x01:60Hz, 0x02:40Hz, 0x03:30Hz, 0x07:10Hz */
					39 00 00 40 00 00 02 F7 0F
					39 00 00 00 00 00 03 F0 A5 A5
				];
				mi,mdss-dsi-doze-hbm-nolp-command-state = "dsi_lp_mode";

				mi,mdss-dsi-doze-lbm-nolp-command = [
					39 00 00 40 00 00 03 F0 5A 5A
					15 00 00 40 00 00 02 53 20
					39 00 00 40 00 00 03 51 00 10
					39 00 00 00 22 00 03 F0 A5 A5
					/* 40Hz Setting(force increasing off) */
					39 00 00 40 00 00 03 F0 5A 5A
					39 00 00 40 00 00 04 B0 00 08 CB
					39 00 00 40 00 00 02 CB 27
					39 00 00 40 00 00 03 BD 21 82
					39 00 00 40 00 00 04 B0 00 10 BD
					39 00 00 40 00 00 02 BD 00
					39 00 00 40 00 00 04 B0 00 21 BD
					39 00 00 40 00 00 0F BD 03 00 06 00 09 00 0C 00 0F 00 15 00 21 00
					39 00 00 40 00 00 04 B0 00 61 BD
					39 00 00 40 00 00 0A BD 04 00 08 00 0C 00 10 00 74
					39 00 00 40 00 00 04 B0 00 12 BD
					39 00 00 40 00 00 02 BD 01
					39 00 00 40 00 00 04 B0 00 16 BD
					39 00 00 40 00 00 03 BD 00 00    /* Step delay */
					39 00 00 40 00 00 02 BD 21       /* Manual mode */
					39 00 00 40 00 00 02 60 02       /* 0x00:120Hz, 0x01:60Hz, 0x02:40Hz, 0x03:30Hz, 0x07:10Hz */
					39 00 00 40 00 00 02 F7 0F
					39 00 00 00 00 00 03 F0 A5 A5
				];
				mi,mdss-dsi-doze-lbm-nolp-command-state = "dsi_lp_mode";

				mi,mdss-dsi-local-hbm-hlpm-white-1000nit-command = [
					/* nolp */
					39 00 00 40 00 00 03 F0 5A 5A
					39 00 00 40 00 00 02 53 20
					39 00 00 00 22 00 03 F0 A5 A5
					/* 40Hz Setting(force increasing off) */
					39 00 00 40 00 00 03 F0 5A 5A
					39 00 00 40 00 00 04 B0 00 08 CB
					39 00 00 40 00 00 02 CB 27
					39 00 00 40 00 00 03 BD 21 82
					39 00 00 40 00 00 04 B0 00 10 BD
					39 00 00 40 00 00 02 BD 00
					39 00 00 40 00 00 04 B0 00 21 BD
					39 00 00 40 00 00 0F BD 03 00 06 00 09 00 0C 00 0F 00 15 00 21 00
					39 00 00 40 00 00 04 B0 00 61 BD
					39 00 00 40 00 00 0A BD 04 00 08 00 0C 00 10 00 74
					39 00 00 40 00 00 04 B0 00 12 BD
					39 00 00 40 00 00 02 BD 01
					39 00 00 40 00 00 04 B0 00 16 BD
					39 00 00 40 00 00 03 BD 00 00    /* Step delay */
					39 00 00 40 00 00 02 BD 21       /* Manual mode */
					39 00 00 40 00 00 02 60 02       /* 0x00:120Hz, 0x01:60Hz, 0x02:40Hz, 0x03:30Hz, 0x07:10Hz */
					39 00 00 40 00 00 02 F7 0F
					39 00 00 00 00 00 03 F0 A5 A5
					/* Local HBM setting */
					39 00 00 40 00 00 03 F0 5A 5A
					39 00 00 40 00 00 04 B0 01 DC 1F
					39 00 00 40 00 00 10 1F
						02 00 00 00 00 24 09 1F 35 FA 3F 2D 09 AF 86
					39 00 00 40 00 00 04 B0 02 AC 66
					39 00 00 40 00 00 03 66 0F FF
					39 00 00 40 00 00 04 B0 01 6D 66
					39 00 00 40 00 00 13 66
						00 40 14 02 90 52 0A 41 48 1C 27 FF FF FF FF FF
						FF FF
					39 00 00 40 00 00 04 B0 01 59 66
					39 00 00 40 00 00 0B 66
						08 7A 9F F5 AF 08 7A 9F F5 AF    /* 1100nit */
					39 00 00 40 00 00 04 B0 01 B5 66
					39 00 00 40 00 00 37 66
						14 01 DE 2A 43 A2 4F 66 CC 80 08 00 80 08 00 80
						08 00 14 01 DE 2A 43 A2 4F 66 CC 80 08 00 80 08
						00 80 08 00 14 01 DE 2A 43 A2 4F 66 CC 80 08 00
						80 08 00 80 08 00
					39 00 00 40 00 00 04 B0 01 EB 66
					39 00 00 40 00 00 37 66
						14 61 EE 2A 43 A2 4F 66 CC 80 08 00 80 08 00 80
						08 00 14 61 EE 2A 43 A2 4F 66 CC 80 08 00 80 08
						00 80 08 00 14 61 EE 2A 43 A2 4F 66 CC 80 08 00
						80 08 00 80 08 00
					39 00 00 40 00 00 02 53 30    /* 0x30 Local HBM transition */
					39 00 00 00 00 00 03 F0 A5 A5
				];
				mi,mdss-dsi-local-hbm-hlpm-white-1000nit-command-state = "dsi_hs_mode";

				mi,mdss-dsi-local-hbm-hlpm-white-110nit-command = [
					/* nolp */
					39 00 00 40 00 00 03 F0 5A 5A
					39 00 00 40 00 00 02 53 20
					39 00 00 00 22 00 03 F0 A5 A5
					/* 40Hz Setting(force increasing off) */
					39 00 00 40 00 00 03 F0 5A 5A
					39 00 00 40 00 00 04 B0 00 08 CB
					39 00 00 40 00 00 02 CB 27
					39 00 00 40 00 00 03 BD 21 82
					39 00 00 40 00 00 04 B0 00 10 BD
					39 00 00 40 00 00 02 BD 00
					39 00 00 40 00 00 04 B0 00 21 BD
					39 00 00 40 00 00 0F BD 03 00 06 00 09 00 0C 00 0F 00 15 00 21 00
					39 00 00 40 00 00 04 B0 00 61 BD
					39 00 00 40 00 00 0A BD 04 00 08 00 0C 00 10 00 74
					39 00 00 40 00 00 04 B0 00 12 BD
					39 00 00 40 00 00 02 BD 01
					39 00 00 40 00 00 04 B0 00 16 BD
					39 00 00 40 00 00 03 BD 00 00    /* Step delay */
					39 00 00 40 00 00 02 BD 21       /* Manual mode */
					39 00 00 40 00 00 02 60 02       /* 0x00:120Hz, 0x01:60Hz, 0x02:40Hz, 0x03:30Hz, 0x07:10Hz */
					39 00 00 40 00 00 02 F7 0F
					39 00 00 00 00 00 03 F0 A5 A5
					/* Local HBM setting */
					39 00 00 40 00 00 03 F0 5A 5A
					39 00 00 40 00 00 04 B0 01 DC 1F
					39 00 00 40 00 00 10 1F
						02 00 00 00 00 24 09 1F 35 FA 3F 2D 09 AF 86
					39 00 00 40 00 00 04 B0 02 AC 66
					39 00 00 40 00 00 03 66 0F FF
					39 00 00 40 00 00 04 B0 01 6D 66
					39 00 00 40 00 00 13 66
						00 40 14 02 90 52 0A 41 48 1C 27 FF FF FF FF FF
						FF FF
					39 00 00 40 00 00 04 B0 01 59 66
					39 00 00 40 00 00 0B 66
						05 56 E0 83 E8 05 56 E0 83 E8    /* 110nit */
					39 00 00 40 00 00 04 B0 01 B5 66
					39 00 00 40 00 00 37 66
						14 01 DE 2A 43 A2 4F 66 CC 80 08 00 80 08 00 80
						08 00 14 01 DE 2A 43 A2 4F 66 CC 80 08 00 80 08
						00 80 08 00 14 01 DE 2A 43 A2 4F 66 CC 80 08 00
						80 08 00 80 08 00
					39 00 00 40 00 00 04 B0 01 EB 66
					39 00 00 40 00 00 37 66
						14 61 EE 2A 43 A2 4F 66 CC 80 08 00 80 08 00 80
						08 00 14 61 EE 2A 43 A2 4F 66 CC 80 08 00 80 08
						00 80 08 00 14 61 EE 2A 43 A2 4F 66 CC 80 08 00
						80 08 00 80 08 00
					39 00 00 40 00 00 02 53 30    /* 0x30 Local HBM transition */
					39 00 00 00 00 00 03 F0 A5 A5
				];
				mi,mdss-dsi-local-hbm-hlpm-white-110nit-command-state = "dsi_hs_mode";

				qcom,compression-mode = "dsc";
				qcom,mdss-dsc-slice-height = <50>;
				qcom,mdss-dsc-slice-width = <720>;
				qcom,mdss-dsc-slice-per-pkt = <2>;
				qcom,mdss-dsc-bit-per-component = <10>;
				qcom,mdss-dsc-bit-per-pixel = <8>;
				qcom,mdss-dsc-block-prediction-enable;
			};


			timing@wqhd_30hz_index_04 {
				#include "dsi-panel-l2-38-0c-0a-dsc-cmd-common.dtsi"
				cell-index = <4>;
				qcom,mdss-dsi-panel-framerate = <30>;
				qcom,mdss-dsi-panel-width = <1440>;
				qcom,mdss-dsi-panel-height = <3200>;
				qcom,mdss-dsi-h-front-porch = <32>;
				qcom,mdss-dsi-h-back-porch = <32>;
				qcom,mdss-dsi-h-pulse-width = <16>;
				qcom,mdss-dsi-h-sync-skew = <0>;
				qcom,mdss-dsi-v-back-porch = <24>;
				qcom,mdss-dsi-v-front-porch = <24>;
				qcom,mdss-dsi-v-pulse-width = <8>;
				qcom,mdss-dsi-h-sync-pulse = <0>;
				qcom,mdss-dsi-h-left-border = <0>;
				qcom,mdss-dsi-h-right-border = <0>;
				qcom,mdss-dsi-v-top-border = <0>;
				qcom,mdss-dsi-v-bottom-border = <0>;
				qcom,mdss-dsi-panel-clockrate = <1360000000>;
				qcom,mdss-dsi-panel-jitter = <0x5 0x1>;
				qcom,mdss-mdp-transfer-time-us = <7300>;

				/* the cmd sequence sync TE */
				mi,mdss-dsi-exit-90fps-timing-switch-command = [
					/* CASET/PASET Setting 1440*3200 */
					39 00 00 60 00 00 05 2A 00 00 05 9F
					39 00 00 60 00 00 05 2B 00 00 0C 7F
					/* Scaler Setting 1440*3200 */
					39 00 00 60 00 00 03 F0 5A 5A
					39 00 00 60 00 00 02 C3 0C
					39 00 00 60 00 00 03 F0 A5 A5
					/* 90hz -> 30hz */
					39 00 00 60 00 00 03 F0 5A 5A
					39 00 00 60 00 00 02 60 00     /* 120hz */
					39 00 00 60 00 00 02 F7 0F
					39 00 00 20 05 00 03 F0 5A 5A  /* 1 sync */
					39 00 00 60 00 00 04 B0 00 08 CB
					39 00 00 60 00 00 02 CB 27
					39 00 00 60 00 00 02 F7 0F
					39 00 00 20 05 00 03 F0 A5 A5  /* 2 sync */
					39 00 00 60 00 00 03 F0 5A 5A
					39 00 00 60 00 00 02 60 03     /* 0x00:120Hz, 0x01:60Hz, 0x03:30Hz, 0x07:10Hz */
					39 00 00 20 00 00 02 F7 0F     /* 3 sync */
				];
				mi,mdss-dsi-exit-90fps-timing-switch-command-state = "dsi_hs_mode";

				qcom,mdss-dsi-timing-switch-command = [
					/* CASET/PASET Setting 1440*3200 */
					39 00 00 40 00 00 05 2A 00 00 05 9F
					39 00 00 40 00 00 05 2B 00 00 0C 7F
					/* Scaler Setting 1440*3200 */
					39 00 00 40 00 00 03 F0 5A 5A
					39 00 00 40 00 00 02 C3 0C
					39 00 00 40 00 00 03 F0 A5 A5
					/* FIX TE OFF */
					39 00 00 40 00 00 03 F0 5A 5A
					15 00 00 40 00 00 02 B9 00
					39 00 00 40 00 00 04 B0 00 06 B9
					39 00 00 40 00 00 07 B9 00 00 00 00 00 00
					39 00 00 40 00 00 02 F7 0F
					39 00 00 40 00 00 03 F0 A5 A5
					/* 30Hz Setting(force increasing off) */
					39 00 00 40 00 00 03 F0 5A 5A
					39 00 00 40 00 00 04 B0 00 08 CB
					39 00 00 40 00 00 02 CB 27
					39 00 00 40 00 00 03 BD 21 82
					39 00 00 40 00 00 04 B0 00 10 BD
					39 00 00 40 00 00 02 BD 00
					39 00 00 40 00 00 04 B0 00 21 BD
					39 00 00 40 00 00 0F BD 03 00 06 00 09 00 0C 00 0F 00 15 00 21 00
					39 00 00 40 00 00 04 B0 00 61 BD
					39 00 00 40 00 00 0A BD 04 00 08 00 0C 00 10 00 74
					39 00 00 40 00 00 04 B0 00 12 BD
					39 00 00 40 00 00 02 BD 01
					39 00 00 40 00 00 04 B0 00 16 BD
					39 00 00 40 00 00 03 BD 00 00    /* Step delay */
					39 00 00 40 00 00 02 BD 21       /* Manual mode */
					39 00 00 40 00 00 02 60 03       /* 0x00:120Hz, 0x01:60Hz, 0x03:30Hz, 0x07:10Hz */
					39 00 00 40 00 00 02 F7 0F
					39 00 00 00 00 00 03 F0 A5 A5
				];
				qcom,mdss-dsi-timing-switch-command-state = "dsi_hs_mode";

				qcom,mdss-dsi-on-command = [
					/* DSC PPS Setting */
					39 00 00 00 00 00 81 9E
						11 00 00 AB 30 80 0C 80 05 A0 00 19 02 D0 02 D0
						02 00 02 68 00 20 02 BE 00 0A 00 0C 04 00 03 0D
						18 00 10 F0 07 10 20 00 06 0F 0F 33 0E 1C 2A 38
						46 54 62 69 70 77 79 7B 7D 7E 01 02 22 00 2A 40
						2A BE 3A FC 3A FA 3A F8 3B 38 3B 78 3B B6 4B F6
						4C 34 4C 74 5C 74 8C F4 00 00 00 00 00 00 00 00
						00 00 00 00 00 00 00 00 00 00 00 00 00 00 00 00
						00 00 00 00 00 00 00 00 00 00 00 00 00 00 00 00
					/* DSC Compression Enable */
					15 00 00 00 00 00 02 9D 01
					/* Sleep Out */
					05 00 00 00 78 00 02 11 00
					/* Common Setting */
					/* TE(Vsync) On */
					15 00 00 00 00 00 02 35 00
					/* CASET/PASET Setting 1440*3200 */
					39 00 00 00 00 00 05 2A 00 00 05 9F
					39 00 00 00 00 00 05 2B 00 00 0C 7F
					/* Scaler Setting 1440*3200 */
					39 00 00 40 00 00 03 F0 5A 5A
					15 00 00 40 00 00 02 C3 0C    /* 0x0C:WQHD+(1440x3200), 0x0D:FHD+(1080x2400) */
					39 00 00 00 00 00 03 F0 A5 A5
					/* FIX TE OFF */
					39 00 00 40 00 00 03 F0 5A 5A
					15 00 00 40 00 00 02 B9 00
					39 00 00 40 00 00 04 B0 00 06 B9
					39 00 00 40 00 00 07 B9 00 00 00 00 00 00
					39 00 00 40 00 00 02 F7 0F
					39 00 00 00 00 00 03 F0 A5 A5
					/* 30Hz Setting(force increasing off) */
					39 00 00 40 00 00 03 F0 5A 5A
					39 00 00 40 00 00 04 B0 00 08 CB
					39 00 00 40 00 00 02 CB 27
					39 00 00 40 00 00 03 BD 21 82
					39 00 00 40 00 00 04 B0 00 10 BD
					39 00 00 40 00 00 02 BD 00
					39 00 00 40 00 00 04 B0 00 21 BD
					39 00 00 40 00 00 0F BD 03 00 06 00 09 00 0C 00 0F 00 15 00 21 00
					39 00 00 40 00 00 04 B0 00 61 BD
					39 00 00 40 00 00 0A BD 04 00 08 00 0C 00 10 00 74
					39 00 00 40 00 00 04 B0 00 12 BD
					39 00 00 40 00 00 02 BD 01
					39 00 00 40 00 00 04 B0 00 16 BD
					39 00 00 40 00 00 03 BD 00 00    /* Step delay */
					39 00 00 40 00 00 02 BD 21       /* Manual mode */
					39 00 00 40 00 00 02 60 03       /* 0x00:120Hz, 0x01:60Hz, 0x03:30Hz, 0x07:10Hz */
					39 00 00 40 00 00 02 F7 0F
					39 00 00 00 00 00 03 F0 A5 A5
					/* Dimming Setting*/
					39 00 00 00 00 00 03 F0 5A 5A
					39 00 00 00 00 00 04 B0 00 0D 63
					39 00 00 00 00 00 02 63 20
					39 00 00 00 00 00 04 B0 00 0C 63
					39 00 00 00 00 00 02 63 20
					39 00 00 00 00 00 03 F0 A5 A5
					39 00 00 00 00 00 02 53 20
					39 00 00 00 00 00 03 51 00 00
					39 00 00 00 00 00 02 F7 0F
					39 00 00 00 00 00 03 F0 A5 A5
					/* ESD Error Flag, Normal High, Error Low */
					39 00 00 40 00 00 03 F0 5A 5A
					39 00 00 40 00 00 04 B0 00 47 F4
					15 00 00 40 00 00 02 F4 01
					39 00 00 40 00 00 04 ED 47 05 20
					39 00 00 00 00 00 03 F0 A5 A5
					/* touch sync enable */
					39 00 00 40 00 00 03 F0 5A 5A
					39 00 00 40 00 00 03 F1 5A 5A
					39 00 00 40 00 00 04 B0 00 22 B9
					39 00 00 40 00 00 03 B9 B1 A1
					39 00 00 40 00 00 04 B0 00 05 F2
					15 00 00 40 00 00 02 F2 52
					15 00 00 40 00 00 02 F7 0F
					39 00 00 40 00 00 03 F1 A5 A5
					39 00 00 40 00 00 03 F0 A5 A5
					39 00 00 40 00 00 03 F0 5A 5A
					39 00 00 40 00 00 02 C3 0C
					39 00 00 00 00 00 03 F0 A5 A5
					/* DIA setting */
					39 00 00 40 00 00 03 F0 5A 5A
					39 00 00 40 00 00 04 B0 02 67 1D
					39 00 00 40 00 00 02 1D 81
					39 00 00 00 00 00 03 F0 A5 A5
					/* OPEC code */
					39 00 00 40 00 00 03 F0 5A 5A
					39 00 00 40 00 00 04 B0 00 52 1F
					39 00 00 40 00 00 02 1F 02
					39 00 00 40 00 00 04 B0 00 53 1F
					39 00 00 40 00 00 5F 1F
						07 01 00 02 B9 02 BA 07 A2 07 AA 12 C0 12 C1 1A
						BA 1B C0 1F E0 00 53 00 C3 03 43 07 A0 07 A1 07
						A2 07 A6 07 A8 07 AA 07 AC 07 AE 07 B0 07 B2 07
						B4 07 B6 00 03 00 A4 00 C0 00 D1 01 86 03 FF 07
						FF 30 30 35 40 35 30 40 40 35 80 80 80 0A 0F 14
						18 1E 3A 78 80 80 80 80 80 80 80 80 01 B1
					39 00 00 40 00 00 04 B0 00 78 BD
					39 00 00 40 00 00 02 BD 10
					39 00 00 00 00 00 02 F7 0F
					39 00 00 00 00 00 03 F0 A5 A5
					/* Display On */
					05 00 00 00 00 00 02 29 00
				];
				qcom,mdss-dsi-on-command-state = "dsi_lp_mode";

				qcom,mdss-dsi-nolp-command = [
					39 00 00 40 00 00 03 F0 5A 5A
					15 00 00 40 00 00 02 53 20
					39 00 00 40 00 00 03 51 00 00
					39 00 00 00 22 00 03 F0 A5 A5
					/* 30Hz Setting(force increasing off) */
					39 00 00 40 00 00 03 F0 5A 5A
					39 00 00 40 00 00 04 B0 00 08 CB
					39 00 00 40 00 00 02 CB 27
					39 00 00 40 00 00 03 BD 21 82
					39 00 00 40 00 00 04 B0 00 10 BD
					39 00 00 40 00 00 02 BD 00
					39 00 00 40 00 00 04 B0 00 21 BD
					39 00 00 40 00 00 0F BD 03 00 06 00 09 00 0C 00 0F 00 15 00 21 00
					39 00 00 40 00 00 04 B0 00 61 BD
					39 00 00 40 00 00 0A BD 04 00 08 00 0C 00 10 00 74
					39 00 00 40 00 00 04 B0 00 12 BD
					39 00 00 40 00 00 02 BD 01
					39 00 00 40 00 00 04 B0 00 16 BD
					39 00 00 40 00 00 03 BD 00 00    /* Step delay */
					39 00 00 40 00 00 02 BD 21       /* Manual mode */
					39 00 00 40 00 00 02 60 03       /* 0x00:120Hz, 0x01:60Hz, 0x03:30Hz, 0x07:10Hz */
					39 00 00 40 00 00 02 F7 0F
					39 00 00 00 00 00 03 F0 A5 A5
				];
				qcom,mdss-dsi-nolp-command-state = "dsi_lp_mode";

				mi,mdss-dsi-doze-hbm-command = [
					/* 120Hz Setting(force increasing off) */
					39 00 00 40 00 00 03 F0 5A 5A
					39 00 00 40 00 00 04 B0 00 08 CB
					39 00 00 40 00 00 02 CB 27
					39 00 00 40 00 00 03 BD 21 82
					39 00 00 40 00 00 04 B0 00 10 BD
					39 00 00 40 00 00 02 BD 00
					39 00 00 40 00 00 04 B0 00 21 BD
					39 00 00 40 00 00 0F BD 03 00 06 00 09 00 0C 00 0F 00 15 00 21 00
					39 00 00 40 00 00 04 B0 00 61 BD
					39 00 00 40 00 00 0A BD 04 00 08 00 0C 00 10 00 74
					39 00 00 40 00 00 04 B0 00 12 BD
					39 00 00 40 00 00 02 BD 01
					39 00 00 40 00 00 04 B0 00 16 BD
					39 00 00 40 00 00 03 BD 00 00    /* Step delay */
					39 00 00 40 00 00 02 BD 21       /* Manual mode */
					39 00 00 40 00 00 02 60 00       /* 0x00:120Hz, 0x01:60Hz, 0x03:30Hz, 0x07:10Hz */
					39 00 00 40 00 00 02 F7 0F
					39 00 00 00 22 00 03 F0 A5 A5
					/* AOD setting */
					39 00 00 20 00 00 03 51 00 E5
					39 00 00 20 00 00 03 51 00 E5
					39 00 00 60 00 00 03 F0 5A 5A
					39 00 00 60 00 00 02 BB 31
					39 00 00 60 00 00 02 F7 0F
					39 00 00 60 00 00 02 53 24
					39 00 00 20 00 00 03 51 07 FE
				];
				mi,mdss-dsi-doze-lbm-command = [
					/* 120Hz Setting(force increasing off) */
					39 00 00 40 00 00 03 F0 5A 5A
					39 00 00 40 00 00 04 B0 00 08 CB
					39 00 00 40 00 00 02 CB 27
					39 00 00 40 00 00 03 BD 21 82
					39 00 00 40 00 00 04 B0 00 10 BD
					39 00 00 40 00 00 02 BD 00
					39 00 00 40 00 00 04 B0 00 21 BD
					39 00 00 40 00 00 0F BD 03 00 06 00 09 00 0C 00 0F 00 15 00 21 00
					39 00 00 40 00 00 04 B0 00 61 BD
					39 00 00 40 00 00 0A BD 04 00 08 00 0C 00 10 00 74
					39 00 00 40 00 00 04 B0 00 12 BD
					39 00 00 40 00 00 02 BD 01
					39 00 00 40 00 00 04 B0 00 16 BD
					39 00 00 40 00 00 03 BD 00 00    /* Step delay */
					39 00 00 40 00 00 02 BD 21       /* Manual mode */
					39 00 00 40 00 00 02 60 00       /* 0x00:120Hz, 0x01:60Hz, 0x03:30Hz, 0x07:10Hz */
					39 00 00 40 00 00 02 F7 0F
					39 00 00 00 22 00 03 F0 A5 A5
					/* AOD setting */
					39 00 00 20 00 00 03 51 00 10
					39 00 00 20 00 00 03 51 00 10
					39 00 00 60 00 00 03 F0 5A 5A
					39 00 00 60 00 00 02 BB 31
					15 00 00 60 00 00 02 F7 0F
					39 00 00 20 00 00 02 53 24
					39 00 00 00 00 00 03 51 00 F6
				];
				/* <mipi_address  update_index  update_length> */
				mi,mdss-dsi-doze-lbm-command-update = <0x53 23 1>;
				mi,mdss-dsi-doze-hbm-command-state = "dsi_lp_mode";
				mi,mdss-dsi-doze-lbm-command-state = "dsi_lp_mode";

				mi,mdss-dsi-doze-hbm-nolp-command = [
					39 00 00 60 00 00 03 51 04 29
					39 00 00 20 23 00 02 53 20
					39 00 00 00 00 00 03 51 00 E5
					/* 30Hz Setting(force increasing off) */
					39 00 00 40 00 00 03 F0 5A 5A
					39 00 00 40 00 00 04 B0 00 08 CB
					39 00 00 40 00 00 02 CB 27
					39 00 00 40 00 00 03 BD 21 82
					39 00 00 40 00 00 04 B0 00 10 BD
					39 00 00 40 00 00 02 BD 00
					39 00 00 40 00 00 04 B0 00 21 BD
					39 00 00 40 00 00 0F BD 03 00 06 00 09 00 0C 00 0F 00 15 00 21 00
					39 00 00 40 00 00 04 B0 00 61 BD
					39 00 00 40 00 00 0A BD 04 00 08 00 0C 00 10 00 74
					39 00 00 40 00 00 04 B0 00 12 BD
					39 00 00 40 00 00 02 BD 01
					39 00 00 40 00 00 04 B0 00 16 BD
					39 00 00 40 00 00 03 BD 00 00    /* Step delay */
					39 00 00 40 00 00 02 BD 21       /* Manual mode */
					39 00 00 40 00 00 02 60 03       /* 0x00:120Hz, 0x01:60Hz, 0x03:30Hz, 0x07:10Hz */
					39 00 00 40 00 00 02 F7 0F
					39 00 00 00 00 00 03 F0 A5 A5
				];
				mi,mdss-dsi-doze-hbm-nolp-command-state = "dsi_lp_mode";

				mi,mdss-dsi-doze-lbm-nolp-command = [
					39 00 00 40 00 00 03 F0 5A 5A
					15 00 00 40 00 00 02 53 20
					39 00 00 40 00 00 03 51 00 10
					39 00 00 00 22 00 03 F0 A5 A5
					/* 30Hz Setting(force increasing off) */
					39 00 00 40 00 00 03 F0 5A 5A
					39 00 00 40 00 00 04 B0 00 08 CB
					39 00 00 40 00 00 02 CB 27
					39 00 00 40 00 00 03 BD 21 82
					39 00 00 40 00 00 04 B0 00 10 BD
					39 00 00 40 00 00 02 BD 00
					39 00 00 40 00 00 04 B0 00 21 BD
					39 00 00 40 00 00 0F BD 03 00 06 00 09 00 0C 00 0F 00 15 00 21 00
					39 00 00 40 00 00 04 B0 00 61 BD
					39 00 00 40 00 00 0A BD 04 00 08 00 0C 00 10 00 74
					39 00 00 40 00 00 04 B0 00 12 BD
					39 00 00 40 00 00 02 BD 01
					39 00 00 40 00 00 04 B0 00 16 BD
					39 00 00 40 00 00 03 BD 00 00    /* Step delay */
					39 00 00 40 00 00 02 BD 21       /* Manual mode */
					39 00 00 40 00 00 02 60 03       /* 0x00:120Hz, 0x01:60Hz, 0x03:30Hz, 0x07:10Hz */
					39 00 00 40 00 00 02 F7 0F
					39 00 00 00 00 00 03 F0 A5 A5
				];
				mi,mdss-dsi-doze-lbm-nolp-command-state = "dsi_lp_mode";

				mi,mdss-dsi-local-hbm-hlpm-white-1000nit-command = [
					/* nolp */
					39 00 00 40 00 00 03 F0 5A 5A
					39 00 00 40 00 00 02 53 20
					39 00 00 00 22 00 03 F0 A5 A5
					/* 30Hz Setting(force increasing off) */
					39 00 00 40 00 00 03 F0 5A 5A
					39 00 00 40 00 00 04 B0 00 08 CB
					39 00 00 40 00 00 02 CB 27
					39 00 00 40 00 00 03 BD 21 82
					39 00 00 40 00 00 04 B0 00 10 BD
					39 00 00 40 00 00 02 BD 00
					39 00 00 40 00 00 04 B0 00 21 BD
					39 00 00 40 00 00 0F BD 03 00 06 00 09 00 0C 00 0F 00 15 00 21 00
					39 00 00 40 00 00 04 B0 00 61 BD
					39 00 00 40 00 00 0A BD 04 00 08 00 0C 00 10 00 74
					39 00 00 40 00 00 04 B0 00 12 BD
					39 00 00 40 00 00 02 BD 01
					39 00 00 40 00 00 04 B0 00 16 BD
					39 00 00 40 00 00 03 BD 00 00    /* Step delay */
					39 00 00 40 00 00 02 BD 21       /* Manual mode */
					39 00 00 40 00 00 02 60 03       /* 0x00:120Hz, 0x01:60Hz, 0x03:30Hz, 0x07:10Hz */
					39 00 00 40 00 00 02 F7 0F
					39 00 00 00 00 00 03 F0 A5 A5
					/* Local HBM setting */
					39 00 00 40 00 00 03 F0 5A 5A
					39 00 00 40 00 00 04 B0 01 DC 1F
					39 00 00 40 00 00 10 1F
						02 00 00 00 00 24 09 1F 35 FA 3F 2D 09 AF 86
					39 00 00 40 00 00 04 B0 02 AC 66
					39 00 00 40 00 00 03 66 0F FF
					39 00 00 40 00 00 04 B0 01 6D 66
					39 00 00 40 00 00 13 66
						00 40 14 02 90 52 0A 41 48 1C 27 FF FF FF FF FF
						FF FF
					39 00 00 40 00 00 04 B0 01 59 66
					39 00 00 40 00 00 0B 66
						08 7A 9F F5 AF 08 7A 9F F5 AF    /* 1100nit */
					39 00 00 40 00 00 04 B0 01 B5 66
					39 00 00 40 00 00 37 66
						14 01 DE 2A 43 A2 4F 66 CC 80 08 00 80 08 00 80
						08 00 14 01 DE 2A 43 A2 4F 66 CC 80 08 00 80 08
						00 80 08 00 14 01 DE 2A 43 A2 4F 66 CC 80 08 00
						80 08 00 80 08 00
					39 00 00 40 00 00 04 B0 01 EB 66
					39 00 00 40 00 00 37 66
						14 61 EE 2A 43 A2 4F 66 CC 80 08 00 80 08 00 80
						08 00 14 61 EE 2A 43 A2 4F 66 CC 80 08 00 80 08
						00 80 08 00 14 61 EE 2A 43 A2 4F 66 CC 80 08 00
						80 08 00 80 08 00
					39 00 00 40 00 00 02 53 30    /* 0x30 Local HBM transition */
					39 00 00 00 00 00 03 F0 A5 A5
				];
				mi,mdss-dsi-local-hbm-hlpm-white-1000nit-command-state = "dsi_hs_mode";

				mi,mdss-dsi-local-hbm-hlpm-white-110nit-command = [
					/* nolp */
					39 00 00 40 00 00 03 F0 5A 5A
					39 00 00 40 00 00 02 53 20
					39 00 00 00 22 00 03 F0 A5 A5
					/* 30Hz Setting(force increasing off) */
					39 00 00 40 00 00 03 F0 5A 5A
					39 00 00 40 00 00 04 B0 00 08 CB
					39 00 00 40 00 00 02 CB 27
					39 00 00 40 00 00 03 BD 21 82
					39 00 00 40 00 00 04 B0 00 10 BD
					39 00 00 40 00 00 02 BD 00
					39 00 00 40 00 00 04 B0 00 21 BD
					39 00 00 40 00 00 0F BD 03 00 06 00 09 00 0C 00 0F 00 15 00 21 00
					39 00 00 40 00 00 04 B0 00 61 BD
					39 00 00 40 00 00 0A BD 04 00 08 00 0C 00 10 00 74
					39 00 00 40 00 00 04 B0 00 12 BD
					39 00 00 40 00 00 02 BD 01
					39 00 00 40 00 00 04 B0 00 16 BD
					39 00 00 40 00 00 03 BD 00 00    /* Step delay */
					39 00 00 40 00 00 02 BD 21       /* Manual mode */
					39 00 00 40 00 00 02 60 03       /* 0x00:120Hz, 0x01:60Hz, 0x03:30Hz, 0x07:10Hz */
					39 00 00 40 00 00 02 F7 0F
					39 00 00 00 00 00 03 F0 A5 A5
					/* Local HBM setting */
					39 00 00 40 00 00 03 F0 5A 5A
					39 00 00 40 00 00 04 B0 01 DC 1F
					39 00 00 40 00 00 10 1F
						02 00 00 00 00 24 09 1F 35 FA 3F 2D 09 AF 86
					39 00 00 40 00 00 04 B0 02 AC 66
					39 00 00 40 00 00 03 66 0F FF
					39 00 00 40 00 00 04 B0 01 6D 66
					39 00 00 40 00 00 13 66
						00 40 14 02 90 52 0A 41 48 1C 27 FF FF FF FF FF
						FF FF
					39 00 00 40 00 00 04 B0 01 59 66
					39 00 00 40 00 00 0B 66
						05 56 E0 83 E8 05 56 E0 83 E8    /* 110nit */
					39 00 00 40 00 00 04 B0 01 B5 66
					39 00 00 40 00 00 37 66
						14 01 DE 2A 43 A2 4F 66 CC 80 08 00 80 08 00 80
						08 00 14 01 DE 2A 43 A2 4F 66 CC 80 08 00 80 08
						00 80 08 00 14 01 DE 2A 43 A2 4F 66 CC 80 08 00
						80 08 00 80 08 00
					39 00 00 40 00 00 04 B0 01 EB 66
					39 00 00 40 00 00 37 66
						14 61 EE 2A 43 A2 4F 66 CC 80 08 00 80 08 00 80
						08 00 14 61 EE 2A 43 A2 4F 66 CC 80 08 00 80 08
						00 80 08 00 14 61 EE 2A 43 A2 4F 66 CC 80 08 00
						80 08 00 80 08 00
					39 00 00 40 00 00 02 53 30    /* 0x30 Local HBM transition */
					39 00 00 00 00 00 03 F0 A5 A5
				];
				mi,mdss-dsi-local-hbm-hlpm-white-110nit-command-state = "dsi_hs_mode";

				qcom,compression-mode = "dsc";
				qcom,mdss-dsc-slice-height = <50>;
				qcom,mdss-dsc-slice-width = <720>;
				qcom,mdss-dsc-slice-per-pkt = <2>;
				qcom,mdss-dsc-bit-per-component = <10>;
				qcom,mdss-dsc-bit-per-pixel = <8>;
				qcom,mdss-dsc-block-prediction-enable;
			};

			timing@wqhd_24hz_index_05 {
				#include "dsi-panel-l2-38-0c-0a-dsc-cmd-common.dtsi"
				cell-index = <5>;
				qcom,mdss-dsi-panel-framerate = <24>;
				qcom,mdss-dsi-panel-width = <1440>;
				qcom,mdss-dsi-panel-height = <3200>;
				qcom,mdss-dsi-h-front-porch = <32>;
				qcom,mdss-dsi-h-back-porch = <32>;
				qcom,mdss-dsi-h-pulse-width = <16>;
				qcom,mdss-dsi-h-sync-skew = <0>;
				qcom,mdss-dsi-v-back-porch = <24>;
				qcom,mdss-dsi-v-front-porch = <24>;
				qcom,mdss-dsi-v-pulse-width = <8>;
				qcom,mdss-dsi-h-sync-pulse = <0>;
				qcom,mdss-dsi-h-left-border = <0>;
				qcom,mdss-dsi-h-right-border = <0>;
				qcom,mdss-dsi-v-top-border = <0>;
				qcom,mdss-dsi-v-bottom-border = <0>;
				qcom,mdss-dsi-panel-clockrate = <1360000000>;
				qcom,mdss-dsi-panel-jitter = <0x5 0x1>;
				qcom,mdss-mdp-transfer-time-us = <7300>;

				/* the cmd sequence sync TE */
				mi,mdss-dsi-exit-90fps-timing-switch-command = [
					/* CASET/PASET Setting 1440*3200 */
					39 00 00 60 00 00 05 2A 00 00 05 9F
					39 00 00 60 00 00 05 2B 00 00 0C 7F
					/* Scaler Setting 1440*3200 */
					39 00 00 60 00 00 03 F0 5A 5A
					39 00 00 60 00 00 02 C3 0C
					39 00 00 60 00 00 03 F0 A5 A5
					/* 90hz -> 24hz */
					39 00 00 60 00 00 03 F0 5A 5A
					39 00 00 60 00 00 02 60 00     /* 120hz */
					39 00 00 60 00 00 02 F7 0F
					39 00 00 20 05 00 03 F0 5A 5A  /* 1 sync */
					39 00 00 60 00 00 04 B0 00 08 CB
					39 00 00 60 00 00 02 CB 27
					39 00 00 60 00 00 02 F7 0F
					39 00 00 20 05 00 03 F0 A5 A5  /* 2 sync */
					39 00 00 60 00 00 03 F0 5A 5A
					39 00 00 60 00 00 02 60 04     /* 0x00:120Hz, 0x01:60Hz, 0x03:30Hz, 0x04:24Hz, 0x07:10Hz */
					39 00 00 20 00 00 02 F7 0F     /* 3 sync */
				];
				mi,mdss-dsi-exit-90fps-timing-switch-command-state = "dsi_hs_mode";

				qcom,mdss-dsi-timing-switch-command = [
					/* CASET/PASET Setting 1440*3200 */
					39 00 00 40 00 00 05 2A 00 00 05 9F
					39 00 00 40 00 00 05 2B 00 00 0C 7F
					/* Scaler Setting 1440*3200 */
					39 00 00 40 00 00 03 F0 5A 5A
					39 00 00 40 00 00 02 C3 0C
					39 00 00 40 00 00 03 F0 A5 A5
					/* FIX TE OFF */
					39 00 00 40 00 00 03 F0 5A 5A
					15 00 00 40 00 00 02 B9 00
					39 00 00 40 00 00 04 B0 00 06 B9
					39 00 00 40 00 00 07 B9 00 00 00 00 00 00
					39 00 00 40 00 00 02 F7 0F
					39 00 00 40 00 00 03 F0 A5 A5
					/* 24Hz Setting(force increasing off) */
					39 00 00 40 00 00 03 F0 5A 5A
					39 00 00 40 00 00 04 B0 00 08 CB
					39 00 00 40 00 00 02 CB 27
					39 00 00 40 00 00 03 BD 21 82
					39 00 00 40 00 00 04 B0 00 10 BD
					39 00 00 40 00 00 02 BD 00
					39 00 00 40 00 00 04 B0 00 21 BD
					39 00 00 40 00 00 0F BD 03 00 06 00 09 00 0C 00 0F 00 15 00 21 00
					39 00 00 40 00 00 04 B0 00 61 BD
					39 00 00 40 00 00 0A BD 04 00 08 00 0C 00 10 00 74
					39 00 00 40 00 00 04 B0 00 12 BD
					39 00 00 40 00 00 02 BD 01
					39 00 00 40 00 00 04 B0 00 16 BD
					39 00 00 40 00 00 03 BD 00 00    /* Step delay */
					39 00 00 40 00 00 02 BD 21       /* Manual mode */
					39 00 00 40 00 00 02 60 04       /* 0x00:120Hz, 0x01:60Hz, 0x03:30Hz, 0x04:24Hz, 0x07:10Hz */
					39 00 00 40 00 00 02 F7 0F
					39 00 00 00 00 00 03 F0 A5 A5
				];
				qcom,mdss-dsi-timing-switch-command-state = "dsi_hs_mode";

				qcom,mdss-dsi-on-command = [
					/* DSC PPS Setting */
					39 00 00 00 00 00 81 9E
						11 00 00 AB 30 80 0C 80 05 A0 00 19 02 D0 02 D0
						02 00 02 68 00 20 02 BE 00 0A 00 0C 04 00 03 0D
						18 00 10 F0 07 10 20 00 06 0F 0F 33 0E 1C 2A 38
						46 54 62 69 70 77 79 7B 7D 7E 01 02 22 00 2A 40
						2A BE 3A FC 3A FA 3A F8 3B 38 3B 78 3B B6 4B F6
						4C 34 4C 74 5C 74 8C F4 00 00 00 00 00 00 00 00
						00 00 00 00 00 00 00 00 00 00 00 00 00 00 00 00
						00 00 00 00 00 00 00 00 00 00 00 00 00 00 00 00
					/* DSC Compression Enable */
					15 00 00 00 00 00 02 9D 01
					/* Sleep Out */
					05 00 00 00 78 00 02 11 00
					/* Common Setting */
					/* TE(Vsync) On */
					15 00 00 00 00 00 02 35 00
					/* CASET/PASET Setting 1440*3200 */
					39 00 00 00 00 00 05 2A 00 00 05 9F
					39 00 00 00 00 00 05 2B 00 00 0C 7F
					/* Scaler Setting 1440*3200 */
					39 00 00 40 00 00 03 F0 5A 5A
					15 00 00 40 00 00 02 C3 0C    /* 0x0C:WQHD+(1440x3200), 0x0D:FHD+(1080x2400) */
					39 00 00 00 00 00 03 F0 A5 A5
					/* FIX TE OFF */
					39 00 00 40 00 00 03 F0 5A 5A
					15 00 00 40 00 00 02 B9 00
					39 00 00 40 00 00 04 B0 00 06 B9
					39 00 00 40 00 00 07 B9 00 00 00 00 00 00
					39 00 00 40 00 00 02 F7 0F
					39 00 00 00 00 00 03 F0 A5 A5
					/* 24Hz Setting(force increasing off) */
					39 00 00 40 00 00 03 F0 5A 5A
					39 00 00 40 00 00 04 B0 00 08 CB
					39 00 00 40 00 00 02 CB 27
					39 00 00 40 00 00 03 BD 21 82
					39 00 00 40 00 00 04 B0 00 10 BD
					39 00 00 40 00 00 02 BD 00
					39 00 00 40 00 00 04 B0 00 21 BD
					39 00 00 40 00 00 0F BD 03 00 06 00 09 00 0C 00 0F 00 15 00 21 00
					39 00 00 40 00 00 04 B0 00 61 BD
					39 00 00 40 00 00 0A BD 04 00 08 00 0C 00 10 00 74
					39 00 00 40 00 00 04 B0 00 12 BD
					39 00 00 40 00 00 02 BD 01
					39 00 00 40 00 00 04 B0 00 16 BD
					39 00 00 40 00 00 03 BD 00 00    /* Step delay */
					39 00 00 40 00 00 02 BD 21       /* Manual mode */
					39 00 00 40 00 00 02 60 04       /* 0x00:120Hz, 0x01:60Hz, 0x03:30Hz, 0x04:24Hz, 0x07:10Hz */
					39 00 00 40 00 00 02 F7 0F
					39 00 00 00 00 00 03 F0 A5 A5
					/* Dimming Setting*/
					39 00 00 00 00 00 03 F0 5A 5A
					39 00 00 00 00 00 04 B0 00 0D 63
					39 00 00 00 00 00 02 63 20
					39 00 00 00 00 00 04 B0 00 0C 63
					39 00 00 00 00 00 02 63 20
					39 00 00 00 00 00 03 F0 A5 A5
					39 00 00 00 00 00 02 53 20
					39 00 00 00 00 00 03 51 00 00
					39 00 00 00 00 00 02 F7 0F
					39 00 00 00 00 00 03 F0 A5 A5
					/* ESD Error Flag, Normal High, Error Low */
					39 00 00 40 00 00 03 F0 5A 5A
					39 00 00 40 00 00 04 B0 00 47 F4
					15 00 00 40 00 00 02 F4 01
					39 00 00 40 00 00 04 ED 47 05 20
					39 00 00 00 00 00 03 F0 A5 A5
					/* touch sync enable */
					39 00 00 40 00 00 03 F0 5A 5A
					39 00 00 40 00 00 03 F1 5A 5A
					39 00 00 40 00 00 04 B0 00 22 B9
					39 00 00 40 00 00 03 B9 B1 A1
					39 00 00 40 00 00 04 B0 00 05 F2
					15 00 00 40 00 00 02 F2 52
					15 00 00 40 00 00 02 F7 0F
					39 00 00 40 00 00 03 F1 A5 A5
					39 00 00 40 00 00 03 F0 A5 A5
					39 00 00 40 00 00 03 F0 5A 5A
					39 00 00 40 00 00 02 C3 0C
					39 00 00 00 00 00 03 F0 A5 A5
					/* DIA setting */
					39 00 00 40 00 00 03 F0 5A 5A
					39 00 00 40 00 00 04 B0 02 67 1D
					39 00 00 40 00 00 02 1D 81
					39 00 00 00 00 00 03 F0 A5 A5
					/* OPEC code */
					39 00 00 40 00 00 03 F0 5A 5A
					39 00 00 40 00 00 04 B0 00 52 1F
					39 00 00 40 00 00 02 1F 02
					39 00 00 40 00 00 04 B0 00 53 1F
					39 00 00 40 00 00 5F 1F
						07 01 00 02 B9 02 BA 07 A2 07 AA 12 C0 12 C1 1A
						BA 1B C0 1F E0 00 53 00 C3 03 43 07 A0 07 A1 07
						A2 07 A6 07 A8 07 AA 07 AC 07 AE 07 B0 07 B2 07
						B4 07 B6 00 03 00 A4 00 C0 00 D1 01 86 03 FF 07
						FF 30 30 35 40 35 30 40 40 35 80 80 80 0A 0F 14
						18 1E 3A 78 80 80 80 80 80 80 80 80 01 B1
					39 00 00 40 00 00 04 B0 00 78 BD
					39 00 00 40 00 00 02 BD 10
					39 00 00 00 00 00 02 F7 0F
					39 00 00 00 00 00 03 F0 A5 A5
					/* Display On */
					05 00 00 00 00 00 02 29 00
				];
				qcom,mdss-dsi-on-command-state = "dsi_lp_mode";

				qcom,mdss-dsi-nolp-command = [
					39 00 00 40 00 00 03 F0 5A 5A
					15 00 00 40 00 00 02 53 20
					39 00 00 40 00 00 03 51 00 00
					39 00 00 00 22 00 03 F0 A5 A5
					/* 24Hz Setting(force increasing off) */
					39 00 00 40 00 00 03 F0 5A 5A
					39 00 00 40 00 00 04 B0 00 08 CB
					39 00 00 40 00 00 02 CB 27
					39 00 00 40 00 00 03 BD 21 82
					39 00 00 40 00 00 04 B0 00 10 BD
					39 00 00 40 00 00 02 BD 00
					39 00 00 40 00 00 04 B0 00 21 BD
					39 00 00 40 00 00 0F BD 03 00 06 00 09 00 0C 00 0F 00 15 00 21 00
					39 00 00 40 00 00 04 B0 00 61 BD
					39 00 00 40 00 00 0A BD 04 00 08 00 0C 00 10 00 74
					39 00 00 40 00 00 04 B0 00 12 BD
					39 00 00 40 00 00 02 BD 01
					39 00 00 40 00 00 04 B0 00 16 BD
					39 00 00 40 00 00 03 BD 00 00    /* Step delay */
					39 00 00 40 00 00 02 BD 21       /* Manual mode */
					39 00 00 40 00 00 02 60 04       /* 0x00:120Hz, 0x01:60Hz, 0x03:30Hz, 0x04:24Hz, 0x07:10Hz */
					39 00 00 40 00 00 02 F7 0F
					39 00 00 00 00 00 03 F0 A5 A5
				];
				qcom,mdss-dsi-nolp-command-state = "dsi_lp_mode";

				mi,mdss-dsi-doze-hbm-command = [
					/* 120Hz Setting(force increasing off) */
					39 00 00 40 00 00 03 F0 5A 5A
					39 00 00 40 00 00 04 B0 00 08 CB
					39 00 00 40 00 00 02 CB 27
					39 00 00 40 00 00 03 BD 21 82
					39 00 00 40 00 00 04 B0 00 10 BD
					39 00 00 40 00 00 02 BD 00
					39 00 00 40 00 00 04 B0 00 21 BD
					39 00 00 40 00 00 0F BD 03 00 06 00 09 00 0C 00 0F 00 15 00 21 00
					39 00 00 40 00 00 04 B0 00 61 BD
					39 00 00 40 00 00 0A BD 04 00 08 00 0C 00 10 00 74
					39 00 00 40 00 00 04 B0 00 12 BD
					39 00 00 40 00 00 02 BD 01
					39 00 00 40 00 00 04 B0 00 16 BD
					39 00 00 40 00 00 03 BD 00 00    /* Step delay */
					39 00 00 40 00 00 02 BD 21       /* Manual mode */
					39 00 00 40 00 00 02 60 00       /* 0x00:120Hz, 0x01:60Hz, 0x03:30Hz, 0x07:10Hz */
					39 00 00 40 00 00 02 F7 0F
					39 00 00 00 2A 00 03 F0 A5 A5
					/* AOD setting */
					39 00 00 20 00 00 03 51 00 E5
					39 00 00 20 00 00 03 51 00 E5
					39 00 00 60 00 00 03 F0 5A 5A
					39 00 00 60 00 00 02 BB 31
					39 00 00 60 00 00 02 F7 0F
					39 00 00 60 00 00 02 53 24
					39 00 00 20 00 00 03 51 07 FE
				];
				mi,mdss-dsi-doze-lbm-command = [
					/* 120Hz Setting(force increasing off) */
					39 00 00 40 00 00 03 F0 5A 5A
					39 00 00 40 00 00 04 B0 00 08 CB
					39 00 00 40 00 00 02 CB 27
					39 00 00 40 00 00 03 BD 21 82
					39 00 00 40 00 00 04 B0 00 10 BD
					39 00 00 40 00 00 02 BD 00
					39 00 00 40 00 00 04 B0 00 21 BD
					39 00 00 40 00 00 0F BD 03 00 06 00 09 00 0C 00 0F 00 15 00 21 00
					39 00 00 40 00 00 04 B0 00 61 BD
					39 00 00 40 00 00 0A BD 04 00 08 00 0C 00 10 00 74
					39 00 00 40 00 00 04 B0 00 12 BD
					39 00 00 40 00 00 02 BD 01
					39 00 00 40 00 00 04 B0 00 16 BD
					39 00 00 40 00 00 03 BD 00 00    /* Step delay */
					39 00 00 40 00 00 02 BD 21       /* Manual mode */
					39 00 00 40 00 00 02 60 00       /* 0x00:120Hz, 0x01:60Hz, 0x03:30Hz, 0x07:10Hz */
					39 00 00 40 00 00 02 F7 0F
					39 00 00 00 2A 00 03 F0 A5 A5
					/* AOD setting */
					39 00 00 20 00 00 03 51 00 10
					39 00 00 20 00 00 03 51 00 10
					39 00 00 60 00 00 03 F0 5A 5A
					39 00 00 60 00 00 02 BB 31
					15 00 00 60 00 00 02 F7 0F
					39 00 00 20 00 00 02 53 24
					39 00 00 00 00 00 03 51 00 F6
				];
				/* <mipi_address  update_index  update_length> */
				mi,mdss-dsi-doze-lbm-command-update = <0x53 23 1>;
				mi,mdss-dsi-doze-hbm-command-state = "dsi_lp_mode";
				mi,mdss-dsi-doze-lbm-command-state = "dsi_lp_mode";

				mi,mdss-dsi-doze-hbm-nolp-command = [
					39 00 00 60 00 00 03 51 04 29
					39 00 00 20 23 00 02 53 20
					39 00 00 00 00 00 03 51 00 E5
					/* 24Hz Setting(force increasing off) */
					39 00 00 40 00 00 03 F0 5A 5A
					39 00 00 40 00 00 04 B0 00 08 CB
					39 00 00 40 00 00 02 CB 27
					39 00 00 40 00 00 03 BD 21 82
					39 00 00 40 00 00 04 B0 00 10 BD
					39 00 00 40 00 00 02 BD 00
					39 00 00 40 00 00 04 B0 00 21 BD
					39 00 00 40 00 00 0F BD 03 00 06 00 09 00 0C 00 0F 00 15 00 21 00
					39 00 00 40 00 00 04 B0 00 61 BD
					39 00 00 40 00 00 0A BD 04 00 08 00 0C 00 10 00 74
					39 00 00 40 00 00 04 B0 00 12 BD
					39 00 00 40 00 00 02 BD 01
					39 00 00 40 00 00 04 B0 00 16 BD
					39 00 00 40 00 00 03 BD 00 00    /* Step delay */
					39 00 00 40 00 00 02 BD 21       /* Manual mode */
					39 00 00 40 00 00 02 60 04       /* 0x00:120Hz, 0x01:60Hz, 0x03:30Hz, 0x04:24Hz, 0x07:10Hz */
					39 00 00 40 00 00 02 F7 0F
					39 00 00 00 00 00 03 F0 A5 A5
				];
				mi,mdss-dsi-doze-hbm-nolp-command-state = "dsi_lp_mode";

				mi,mdss-dsi-doze-lbm-nolp-command = [
					39 00 00 40 00 00 03 F0 5A 5A
					15 00 00 40 00 00 02 53 20
					39 00 00 40 00 00 03 51 00 10
					39 00 00 00 22 00 03 F0 A5 A5
					/* 24Hz Setting(force increasing off) */
					39 00 00 40 00 00 03 F0 5A 5A
					39 00 00 40 00 00 04 B0 00 08 CB
					39 00 00 40 00 00 02 CB 27
					39 00 00 40 00 00 03 BD 21 82
					39 00 00 40 00 00 04 B0 00 10 BD
					39 00 00 40 00 00 02 BD 00
					39 00 00 40 00 00 04 B0 00 21 BD
					39 00 00 40 00 00 0F BD 03 00 06 00 09 00 0C 00 0F 00 15 00 21 00
					39 00 00 40 00 00 04 B0 00 61 BD
					39 00 00 40 00 00 0A BD 04 00 08 00 0C 00 10 00 74
					39 00 00 40 00 00 04 B0 00 12 BD
					39 00 00 40 00 00 02 BD 01
					39 00 00 40 00 00 04 B0 00 16 BD
					39 00 00 40 00 00 03 BD 00 00    /* Step delay */
					39 00 00 40 00 00 02 BD 21       /* Manual mode */
					39 00 00 40 00 00 02 60 04       /* 0x00:120Hz, 0x01:60Hz, 0x03:30Hz, 0x04:24Hz, 0x07:10Hz */
					39 00 00 40 00 00 02 F7 0F
					39 00 00 00 00 00 03 F0 A5 A5
				];
				mi,mdss-dsi-doze-lbm-nolp-command-state = "dsi_lp_mode";

				mi,mdss-dsi-local-hbm-hlpm-white-1000nit-command = [
					/* nolp */
					39 00 00 40 00 00 03 F0 5A 5A
					39 00 00 40 00 00 02 53 20
					39 00 00 00 22 00 03 F0 A5 A5
					/* 24Hz Setting(force increasing off) */
					39 00 00 40 00 00 03 F0 5A 5A
					39 00 00 40 00 00 04 B0 00 08 CB
					39 00 00 40 00 00 02 CB 27
					39 00 00 40 00 00 03 BD 21 82
					39 00 00 40 00 00 04 B0 00 10 BD
					39 00 00 40 00 00 02 BD 00
					39 00 00 40 00 00 04 B0 00 21 BD
					39 00 00 40 00 00 0F BD 03 00 06 00 09 00 0C 00 0F 00 15 00 21 00
					39 00 00 40 00 00 04 B0 00 61 BD
					39 00 00 40 00 00 0A BD 04 00 08 00 0C 00 10 00 74
					39 00 00 40 00 00 04 B0 00 12 BD
					39 00 00 40 00 00 02 BD 01
					39 00 00 40 00 00 04 B0 00 16 BD
					39 00 00 40 00 00 03 BD 00 00    /* Step delay */
					39 00 00 40 00 00 02 BD 21       /* Manual mode */
					39 00 00 40 00 00 02 60 04       /* 0x00:120Hz, 0x01:60Hz, 0x03:30Hz, 0x04:24Hz, 0x07:10Hz */
					39 00 00 40 00 00 02 F7 0F
					39 00 00 00 00 00 03 F0 A5 A5
					/* Local HBM setting */
					39 00 00 40 00 00 03 F0 5A 5A
					39 00 00 40 00 00 04 B0 01 DC 1F
					39 00 00 40 00 00 10 1F
						02 00 00 00 00 24 09 1F 35 FA 3F 2D 09 AF 86
					39 00 00 40 00 00 04 B0 02 AC 66
					39 00 00 40 00 00 03 66 0F FF
					39 00 00 40 00 00 04 B0 01 6D 66
					39 00 00 40 00 00 13 66
						00 40 14 02 90 52 0A 41 48 1C 27 FF FF FF FF FF
						FF FF
					39 00 00 40 00 00 04 B0 01 59 66
					39 00 00 40 00 00 0B 66
						08 7A 9F F5 AF 08 7A 9F F5 AF    /* 1100nit */
					39 00 00 40 00 00 04 B0 01 B5 66
					39 00 00 40 00 00 37 66
						14 01 DE 2A 43 A2 4F 66 CC 80 08 00 80 08 00 80
						08 00 14 01 DE 2A 43 A2 4F 66 CC 80 08 00 80 08
						00 80 08 00 14 01 DE 2A 43 A2 4F 66 CC 80 08 00
						80 08 00 80 08 00
					39 00 00 40 00 00 04 B0 01 EB 66
					39 00 00 40 00 00 37 66
						14 61 EE 2A 43 A2 4F 66 CC 80 08 00 80 08 00 80
						08 00 14 61 EE 2A 43 A2 4F 66 CC 80 08 00 80 08
						00 80 08 00 14 61 EE 2A 43 A2 4F 66 CC 80 08 00
						80 08 00 80 08 00
					39 00 00 40 00 00 02 53 30    /* 0x30 Local HBM transition */
					39 00 00 00 00 00 03 F0 A5 A5
				];
				mi,mdss-dsi-local-hbm-hlpm-white-1000nit-command-state = "dsi_hs_mode";

				mi,mdss-dsi-local-hbm-hlpm-white-110nit-command = [
					/* nolp */
					39 00 00 40 00 00 03 F0 5A 5A
					39 00 00 40 00 00 02 53 20
					39 00 00 00 22 00 03 F0 A5 A5
					/* 24Hz Setting(force increasing off) */
					39 00 00 40 00 00 03 F0 5A 5A
					39 00 00 40 00 00 04 B0 00 08 CB
					39 00 00 40 00 00 02 CB 27
					39 00 00 40 00 00 03 BD 21 82
					39 00 00 40 00 00 04 B0 00 10 BD
					39 00 00 40 00 00 02 BD 00
					39 00 00 40 00 00 04 B0 00 21 BD
					39 00 00 40 00 00 0F BD 03 00 06 00 09 00 0C 00 0F 00 15 00 21 00
					39 00 00 40 00 00 04 B0 00 61 BD
					39 00 00 40 00 00 0A BD 04 00 08 00 0C 00 10 00 74
					39 00 00 40 00 00 04 B0 00 12 BD
					39 00 00 40 00 00 02 BD 01
					39 00 00 40 00 00 04 B0 00 16 BD
					39 00 00 40 00 00 03 BD 00 00    /* Step delay */
					39 00 00 40 00 00 02 BD 21       /* Manual mode */
					39 00 00 40 00 00 02 60 04       /* 0x00:120Hz, 0x01:60Hz, 0x03:30Hz, 0x04:24Hz, 0x07:10Hz */
					39 00 00 40 00 00 02 F7 0F
					39 00 00 00 00 00 03 F0 A5 A5
					/* Local HBM setting */
					39 00 00 40 00 00 03 F0 5A 5A
					39 00 00 40 00 00 04 B0 01 DC 1F
					39 00 00 40 00 00 10 1F
						02 00 00 00 00 24 09 1F 35 FA 3F 2D 09 AF 86
					39 00 00 40 00 00 04 B0 02 AC 66
					39 00 00 40 00 00 03 66 0F FF
					39 00 00 40 00 00 04 B0 01 6D 66
					39 00 00 40 00 00 13 66
						00 40 14 02 90 52 0A 41 48 1C 27 FF FF FF FF FF
						FF FF
					39 00 00 40 00 00 04 B0 01 59 66
					39 00 00 40 00 00 0B 66
						05 56 E0 83 E8 05 56 E0 83 E8    /* 110nit */
					39 00 00 40 00 00 04 B0 01 B5 66
					39 00 00 40 00 00 37 66
						14 01 DE 2A 43 A2 4F 66 CC 80 08 00 80 08 00 80
						08 00 14 01 DE 2A 43 A2 4F 66 CC 80 08 00 80 08
						00 80 08 00 14 01 DE 2A 43 A2 4F 66 CC 80 08 00
						80 08 00 80 08 00
					39 00 00 40 00 00 04 B0 01 EB 66
					39 00 00 40 00 00 37 66
						14 61 EE 2A 43 A2 4F 66 CC 80 08 00 80 08 00 80
						08 00 14 61 EE 2A 43 A2 4F 66 CC 80 08 00 80 08
						00 80 08 00 14 61 EE 2A 43 A2 4F 66 CC 80 08 00
						80 08 00 80 08 00
					39 00 00 40 00 00 02 53 30    /* 0x30 Local HBM transition */
					39 00 00 00 00 00 03 F0 A5 A5
				];
				mi,mdss-dsi-local-hbm-hlpm-white-110nit-command-state = "dsi_hs_mode";

				qcom,compression-mode = "dsc";
				qcom,mdss-dsc-slice-height = <50>;
				qcom,mdss-dsc-slice-width = <720>;
				qcom,mdss-dsc-slice-per-pkt = <2>;
				qcom,mdss-dsc-bit-per-component = <10>;
				qcom,mdss-dsc-bit-per-pixel = <8>;
				qcom,mdss-dsc-block-prediction-enable;
			};

			timing@wqhd_10hz_index_06 {
				#include "dsi-panel-l2-38-0c-0a-dsc-cmd-common.dtsi"
				cell-index = <6>;
				qcom,mdss-dsi-panel-framerate = <120>;
				qcom,mdss-dsi-panel-width = <1440>;
				qcom,mdss-dsi-panel-height = <3200>;
				qcom,mdss-dsi-h-front-porch = <32>;
				qcom,mdss-dsi-h-back-porch = <32>;
				qcom,mdss-dsi-h-pulse-width = <16>;
				qcom,mdss-dsi-h-sync-skew = <10>;
				qcom,mdss-dsi-v-back-porch = <24>;
				qcom,mdss-dsi-v-front-porch = <24>;
				qcom,mdss-dsi-v-pulse-width = <8>;
				qcom,mdss-dsi-h-sync-pulse = <0>;
				qcom,mdss-dsi-h-left-border = <0>;
				qcom,mdss-dsi-h-right-border = <0>;
				qcom,mdss-dsi-v-top-border = <0>;
				qcom,mdss-dsi-v-bottom-border = <0>;
				qcom,mdss-dsi-panel-clockrate = <1360000000>;
				qcom,mdss-dsi-panel-jitter = <0x5 0x1>;
				qcom,mdss-mdp-transfer-time-us = <7300>;

				/* the cmd sequence sync TE */
				mi,mdss-dsi-exit-90fps-timing-switch-command = [
					/* CASET/PASET Setting 1440*3200 */
					39 00 00 60 00 00 05 2A 00 00 05 9F
					39 00 00 60 00 00 05 2B 00 00 0C 7F
					/* Scaler Setting 1440*3200 */
					39 00 00 60 00 00 03 F0 5A 5A
					39 00 00 60 00 00 02 C3 0C
					39 00 00 60 00 00 03 F0 A5 A5
					/* 90hz -> 120hz */
					39 00 00 60 00 00 03 F0 5A 5A
					39 00 00 60 00 00 02 60 00     /* 120hz */
					39 00 00 60 00 00 02 F7 0F
					39 00 00 20 05 00 03 F0 A5 A5  /* 1 sync */
					39 00 00 60 00 00 03 F0 5A 5A
					39 00 00 60 00 00 04 B0 00 08 CB
					39 00 00 60 00 00 02 CB 27
					39 00 00 60 00 00 02 F7 0F
					39 00 00 20 05 00 03 F0 A5 A5  /* 2 sync */
					/* FIX TE ON */
					39 00 00 60 00 00 03 F0 5A 5A
					15 00 00 60 00 00 02 B9 41     /* FIXED TE ON*/
					39 00 00 60 00 00 04 B0 00 06 B9
					39 00 00 60 00 00 07 B9 0C 9E 0C 9E 00 1D /* FIXED TE ON*/
					39 00 00 60 00 00 02 F7 0F       /* LTPS UPDATE */
					39 00 00 60 00 00 03 F0 A5 A5
					/* 10Hz Setting(force increasing on) */
					39 00 00 60 00 00 03 F0 5A 5A
					39 00 00 60 00 00 04 B0 00 08 CB
					39 00 00 60 00 00 02 CB 27
					39 00 00 60 00 00 03 BD 23 02    /* Auto mode On */
					39 00 00 60 00 00 04 B0 00 10 BD
					39 00 00 60 00 00 02 BD 10
					39 00 00 60 00 00 04 B0 00 21 BD
					39 00 00 60 00 00 0F BD 03 00 06 00 09 00 0C 00 0F 00 15 00 21 00
					39 00 00 60 00 00 04 B0 00 61 BD
					39 00 00 60 00 00 0A BD 04 00 08 00 0C 00 10 00 74
					39 00 00 60 00 00 04 B0 00 12 BD
					39 00 00 60 00 00 02 BD 02
					39 00 00 60 00 00 04 B0 00 14 BD
					39 00 00 60 00 00 02 BD 0B       /* 0B:10hz */
					39 00 00 60 00 00 04 B0 00 16 BD
					39 00 00 60 00 00 03 BD 03 00    /* Control in Auto mode */
					39 00 00 60 00 00 02 F7 0F
					39 00 00 20 00 00 03 F0 A5 A5    /* 3 sync */
				];
				mi,mdss-dsi-exit-90fps-timing-switch-command-state = "dsi_hs_mode";

				qcom,mdss-dsi-timing-switch-command = [
					/* CASET/PASET Setting 1440*3200 */
					39 00 00 40 00 00 05 2A 00 00 05 9F
					39 00 00 40 00 00 05 2B 00 00 0C 7F
					/* Scaler Setting 1440*3200 */
					39 00 00 40 00 00 03 F0 5A 5A
					39 00 00 40 00 00 02 C3 0C
					39 00 00 40 00 00 03 F0 A5 A5
					/* FIX TE ON */
					39 00 00 40 00 00 03 F0 5A 5A
					15 00 00 40 00 00 02 B9 41
					39 00 00 40 00 00 04 B0 00 06 B9
					39 00 00 40 00 00 07 B9 0C 9E 0C 9E 00 1D
					39 00 00 40 00 00 02 F7 0F
					39 00 00 40 00 00 03 F0 A5 A5
					/* 10Hz Setting(force increasing on) */
					39 00 00 40 00 00 03 F0 5A 5A
					39 00 00 40 00 00 04 B0 00 08 CB
					39 00 00 40 00 00 02 CB 27
					39 00 00 40 00 00 03 BD 23 02    /* Auto mode On */
					39 00 00 40 00 00 04 B0 00 10 BD
					39 00 00 40 00 00 02 BD 10
					39 00 00 40 00 00 04 B0 00 21 BD
					39 00 00 40 00 00 0F BD 03 00 06 00 09 00 0C 00 0F 00 15 00 21 00
					39 00 00 40 00 00 04 B0 00 61 BD
					39 00 00 40 00 00 0A BD 04 00 08 00 0C 00 10 00 74
					39 00 00 40 00 00 04 B0 00 12 BD
					39 00 00 40 00 00 02 BD 02
					39 00 00 40 00 00 04 B0 00 14 BD
					39 00 00 40 00 00 02 BD 0B       /* 0B:10hz */
					39 00 00 40 00 00 04 B0 00 16 BD
					39 00 00 40 00 00 03 BD 03 00    /* Control in Auto mode */
					39 00 00 40 00 00 02 F7 0F
					39 00 00 00 00 00 03 F0 A5 A5
				];
				qcom,mdss-dsi-timing-switch-command-state = "dsi_hs_mode";

				qcom,mdss-dsi-on-command = [
					/* DSC PPS Setting */
					39 00 00 00 00 00 81 9E
						11 00 00 AB 30 80 0C 80 05 A0 00 19 02 D0 02 D0
						02 00 02 68 00 20 02 BE 00 0A 00 0C 04 00 03 0D
						18 00 10 F0 07 10 20 00 06 0F 0F 33 0E 1C 2A 38
						46 54 62 69 70 77 79 7B 7D 7E 01 02 22 00 2A 40
						2A BE 3A FC 3A FA 3A F8 3B 38 3B 78 3B B6 4B F6
						4C 34 4C 74 5C 74 8C F4 00 00 00 00 00 00 00 00
						00 00 00 00 00 00 00 00 00 00 00 00 00 00 00 00
						00 00 00 00 00 00 00 00 00 00 00 00 00 00 00 00
					/* DSC Compression Enable */
					15 00 00 00 00 00 02 9D 01
					/* Sleep Out */
					05 00 00 00 78 00 02 11 00
					/* Common Setting */
					/* TE(Vsync) On */
					15 00 00 00 00 00 02 35 00
					/* CASET/PASET Setting 1440*3200 */
					39 00 00 00 00 00 05 2A 00 00 05 9F
					39 00 00 00 00 00 05 2B 00 00 0C 7F
					/* Scaler Setting 1440*3200 */
					39 00 00 40 00 00 03 F0 5A 5A
					15 00 00 40 00 00 02 C3 0C    /* 0x0C:WQHD+(1440x3200), 0x0D:FHD+(1080x2400) */
					39 00 00 00 00 00 03 F0 A5 A5
					/* FIX TE ON */
					39 00 00 40 00 00 03 F0 5A 5A
					15 00 00 40 00 00 02 B9 41
					39 00 00 40 00 00 04 B0 00 06 B9
					39 00 00 40 00 00 07 B9 0C 9E 0C 9E 00 1D
					39 00 00 40 00 00 02 F7 0F
					39 00 00 00 00 00 03 F0 A5 A5
					/* 10Hz Setting(force increasing on) */
					39 00 00 40 00 00 03 F0 5A 5A
					39 00 00 40 00 00 04 B0 00 08 CB
					39 00 00 40 00 00 02 CB 27
					39 00 00 40 00 00 03 BD 23 02   /* Auto mode On */
					39 00 00 40 00 00 04 B0 00 10 BD
					39 00 00 40 00 00 02 BD 10
					39 00 00 40 00 00 04 B0 00 21 BD
					39 00 00 40 00 00 0F BD 03 00 06 00 09 00 0C 00 0F 00 15 00 21 00
					39 00 00 40 00 00 04 B0 00 61 BD
					39 00 00 40 00 00 0A BD 04 00 08 00 0C 00 10 00 74
					39 00 00 40 00 00 04 B0 00 12 BD
					39 00 00 40 00 00 02 BD 02
					39 00 00 40 00 00 04 B0 00 14 BD
					39 00 00 40 00 00 02 BD 0B       /* 0B:10hz */
					39 00 00 40 00 00 04 B0 00 16 BD
					39 00 00 40 00 00 03 BD 03 00      /* Control in Auto mode */
					//39 00 00 40 00 00 02 60 03     /* 0x00:120Hz, 0x01:60Hz, 0x03:30Hz, 0x07:10Hz */
					39 00 00 40 00 00 02 F7 0F
					39 00 00 00 00 00 03 F0 A5 A5
					/* Dimming Setting */
					39 00 00 00 00 00 03 F0 5A 5A
					39 00 00 00 00 00 04 B0 00 0D 63
					39 00 00 00 00 00 02 63 20
					39 00 00 00 00 00 04 B0 00 0C 63
					39 00 00 00 00 00 02 63 20
					39 00 00 00 00 00 03 F0 A5 A5
					39 00 00 00 00 00 02 53 20
					39 00 00 00 00 00 03 51 00 00
					39 00 00 00 00 00 02 F7 0F
					39 00 00 00 00 00 03 F0 A5 A5
					/* ESD Error Flag, Normal High, Error Low */
					39 00 00 40 00 00 03 F0 5A 5A
					39 00 00 40 00 00 04 B0 00 47 F4
					15 00 00 40 00 00 02 F4 01
					39 00 00 40 00 00 04 ED 47 05 20
					39 00 00 00 00 00 03 F0 A5 A5
					/* touch sync enable */
					39 00 00 40 00 00 03 F0 5A 5A
					39 00 00 40 00 00 03 F1 5A 5A
					39 00 00 40 00 00 04 B0 00 22 B9
					39 00 00 40 00 00 03 B9 B1 A1
					39 00 00 40 00 00 04 B0 00 05 F2
					15 00 00 40 00 00 02 F2 52
					15 00 00 40 00 00 02 F7 0F
					39 00 00 40 00 00 03 F1 A5 A5
					39 00 00 40 00 00 03 F0 A5 A5
					39 00 00 40 00 00 03 F0 5A 5A
					39 00 00 40 00 00 02 C3 0C
					39 00 00 00 00 00 03 F0 A5 A5
					/* DIA setting */
					39 00 00 40 00 00 03 F0 5A 5A
					39 00 00 40 00 00 04 B0 02 67 1D
					39 00 00 40 00 00 02 1D 81
					39 00 00 00 00 00 03 F0 A5 A5
					/* OPEC code */
					39 00 00 40 00 00 03 F0 5A 5A
					39 00 00 40 00 00 04 B0 00 52 1F
					39 00 00 40 00 00 02 1F 02
					39 00 00 40 00 00 04 B0 00 53 1F
					39 00 00 40 00 00 5F 1F
						07 01 00 02 B9 02 BA 07 A2 07 AA 12 C0 12 C1 1A
						BA 1B C0 1F E0 00 53 00 C3 03 43 07 A0 07 A1 07
						A2 07 A6 07 A8 07 AA 07 AC 07 AE 07 B0 07 B2 07
						B4 07 B6 00 03 00 A4 00 C0 00 D1 01 86 03 FF 07
						FF 30 30 35 40 35 30 40 40 35 80 80 80 0A 0F 14
						18 1E 3A 78 80 80 80 80 80 80 80 80 01 B1
					39 00 00 40 00 00 04 B0 00 78 BD
					39 00 00 40 00 00 02 BD 10
					39 00 00 00 00 00 02 F7 0F
					39 00 00 00 00 00 03 F0 A5 A5
					/* Display On */
					05 00 00 00 00 00 02 29 00
				];
				qcom,mdss-dsi-on-command-state = "dsi_lp_mode";

				qcom,mdss-dsi-nolp-command = [
					39 00 00 40 00 00 03 F0 5A 5A
					15 00 00 40 00 00 02 53 20
					39 00 00 40 00 00 03 51 00 00
					39 00 00 00 22 00 03 F0 A5 A5
					/* FIX TE ON */
					39 00 00 40 00 00 03 F0 5A 5A
					15 00 00 40 00 00 02 B9 41
					39 00 00 40 00 00 04 B0 00 06 B9
					39 00 00 40 00 00 07 B9 0C 9E 0C 9E 00 1D
					39 00 00 40 00 00 02 F7 0F
					39 00 00 40 00 00 03 F0 A5 A5
					/* 10Hz Setting(force increasing on) */
					39 00 00 40 00 00 03 F0 5A 5A
					39 00 00 40 00 00 04 B0 00 08 CB
					39 00 00 40 00 00 02 CB 27
					39 00 00 40 00 00 03 BD 23 02    /* Auto mode On */
					39 00 00 40 00 00 04 B0 00 10 BD
					39 00 00 40 00 00 02 BD 10
					39 00 00 40 00 00 04 B0 00 21 BD
					39 00 00 40 00 00 0F BD 03 00 06 00 09 00 0C 00 0F 00 15 00 21 00
					39 00 00 40 00 00 04 B0 00 61 BD
					39 00 00 40 00 00 0A BD 04 00 08 00 0C 00 10 00 74
					39 00 00 40 00 00 04 B0 00 12 BD
					39 00 00 40 00 00 02 BD 02
					39 00 00 40 00 00 04 B0 00 14 BD
					39 00 00 40 00 00 02 BD 0B       /* 0B:10hz */
					39 00 00 40 00 00 04 B0 00 16 BD
					39 00 00 40 00 00 03 BD 03 00    /* Control in Auto mode */
					39 00 00 40 00 00 02 F7 0F
					39 00 00 00 00 00 03 F0 A5 A5
				];
				qcom,mdss-dsi-nolp-command-state = "dsi_lp_mode";

				mi,mdss-dsi-doze-hbm-command = [
					/* 120Hz Setting(force increasing off) */
					39 00 00 40 00 00 03 F0 5A 5A
					39 00 00 40 00 00 04 B0 00 08 CB
					39 00 00 40 00 00 02 CB 27
					39 00 00 40 00 00 03 BD 21 82
					39 00 00 40 00 00 04 B0 00 10 BD
					39 00 00 40 00 00 02 BD 00
					39 00 00 40 00 00 04 B0 00 21 BD
					39 00 00 40 00 00 0F BD 03 00 06 00 09 00 0C 00 0F 00 15 00 21 00
					39 00 00 40 00 00 04 B0 00 61 BD
					39 00 00 40 00 00 0A BD 04 00 08 00 0C 00 10 00 74
					39 00 00 40 00 00 04 B0 00 12 BD
					39 00 00 40 00 00 02 BD 01
					39 00 00 40 00 00 04 B0 00 16 BD
					39 00 00 40 00 00 03 BD 00 00    /* Step delay */
					39 00 00 40 00 00 02 BD 21       /* Manual mode */
					39 00 00 40 00 00 02 60 00       /* 0x00:120Hz, 0x01:60Hz, 0x03:30Hz, 0x07:10Hz */
					39 00 00 40 00 00 02 F7 0F
					39 00 00 00 09 00 03 F0 A5 A5
					/* AOD setting */
					39 00 00 20 00 00 03 51 00 E5
					39 00 00 20 00 00 03 51 00 E5
					39 00 00 60 00 00 03 F0 5A 5A
					39 00 00 60 00 00 02 BB 31
					39 00 00 60 00 00 02 F7 0F
					39 00 00 60 00 00 02 53 24
					39 00 00 20 00 00 03 51 07 FE
				];
				mi,mdss-dsi-doze-lbm-command = [
					/* 120Hz Setting(force increasing off) */
					39 00 00 40 00 00 03 F0 5A 5A
					39 00 00 40 00 00 04 B0 00 08 CB
					39 00 00 40 00 00 02 CB 27
					39 00 00 40 00 00 03 BD 21 82
					39 00 00 40 00 00 04 B0 00 10 BD
					39 00 00 40 00 00 02 BD 00
					39 00 00 40 00 00 04 B0 00 21 BD
					39 00 00 40 00 00 0F BD 03 00 06 00 09 00 0C 00 0F 00 15 00 21 00
					39 00 00 40 00 00 04 B0 00 61 BD
					39 00 00 40 00 00 0A BD 04 00 08 00 0C 00 10 00 74
					39 00 00 40 00 00 04 B0 00 12 BD
					39 00 00 40 00 00 02 BD 01
					39 00 00 40 00 00 04 B0 00 16 BD
					39 00 00 40 00 00 03 BD 00 00    /* Step delay */
					39 00 00 40 00 00 02 BD 21       /* Manual mode */
					39 00 00 40 00 00 02 60 00       /* 0x00:120Hz, 0x01:60Hz, 0x03:30Hz, 0x07:10Hz */
					39 00 00 40 00 00 02 F7 0F
					39 00 00 00 09 00 03 F0 A5 A5
					/* AOD setting */
					39 00 00 20 00 00 03 51 00 10
					39 00 00 20 00 00 03 51 00 10
					39 00 00 60 00 00 03 F0 5A 5A
					39 00 00 60 00 00 02 BB 31
					15 00 00 60 00 00 02 F7 0F
					39 00 00 20 00 00 02 53 24
					39 00 00 00 00 00 03 51 00 F6
				];
				/* <mipi_address  update_index  update_length> */
				mi,mdss-dsi-doze-lbm-command-update = <0x53 23 1>;
				mi,mdss-dsi-doze-hbm-command-state = "dsi_lp_mode";
				mi,mdss-dsi-doze-lbm-command-state = "dsi_lp_mode";

				mi,mdss-dsi-doze-hbm-nolp-command = [
					39 00 00 60 00 00 03 51 04 29
					39 00 00 20 23 00 02 53 20
					39 00 00 00 00 00 03 51 00 E5
					/* FIX TE ON */
					39 00 00 40 00 00 03 F0 5A 5A
					15 00 00 40 00 00 02 B9 41
					39 00 00 40 00 00 04 B0 00 06 B9
					39 00 00 40 00 00 07 B9 0C 9E 0C 9E 00 1D
					39 00 00 40 00 00 02 F7 0F
					39 00 00 40 00 00 03 F0 A5 A5
					/* 10Hz Setting(force increasing on) */
					39 00 00 40 00 00 03 F0 5A 5A
					39 00 00 40 00 00 04 B0 00 08 CB
					39 00 00 40 00 00 02 CB 27
					39 00 00 40 00 00 03 BD 23 02    /* Auto mode On */
					39 00 00 40 00 00 04 B0 00 10 BD
					39 00 00 40 00 00 02 BD 10
					39 00 00 40 00 00 04 B0 00 21 BD
					39 00 00 40 00 00 0F BD 03 00 06 00 09 00 0C 00 0F 00 15 00 21 00
					39 00 00 40 00 00 04 B0 00 61 BD
					39 00 00 40 00 00 0A BD 04 00 08 00 0C 00 10 00 74
					39 00 00 40 00 00 04 B0 00 12 BD
					39 00 00 40 00 00 02 BD 02
					39 00 00 40 00 00 04 B0 00 14 BD
					39 00 00 40 00 00 02 BD 0B       /* 0B:10hz */
					39 00 00 40 00 00 04 B0 00 16 BD
					39 00 00 40 00 00 03 BD 03 00    /* Control in Auto mode */
					39 00 00 40 00 00 02 F7 0F
					39 00 00 00 00 00 03 F0 A5 A5
				];
				mi,mdss-dsi-doze-hbm-nolp-command-state = "dsi_lp_mode";

				mi,mdss-dsi-doze-lbm-nolp-command = [
				        39 00 00 40 00 00 03 F0 5A 5A
				        15 00 00 40 00 00 02 53 20
				        39 00 00 40 00 00 03 51 00 10
				        39 00 00 00 22 00 03 F0 A5 A5
					/* FIX TE ON */
					39 00 00 40 00 00 03 F0 5A 5A
					15 00 00 40 00 00 02 B9 41
					39 00 00 40 00 00 04 B0 00 06 B9
					39 00 00 40 00 00 07 B9 0C 9E 0C 9E 00 1D
					39 00 00 40 00 00 02 F7 0F
					39 00 00 40 00 00 03 F0 A5 A5
					/* 10Hz Setting(force increasing on) */
					39 00 00 40 00 00 03 F0 5A 5A
					39 00 00 40 00 00 04 B0 00 08 CB
					39 00 00 40 00 00 02 CB 27
					39 00 00 40 00 00 03 BD 23 02    /* Auto mode On */
					39 00 00 40 00 00 04 B0 00 10 BD
					39 00 00 40 00 00 02 BD 10
					39 00 00 40 00 00 04 B0 00 21 BD
					39 00 00 40 00 00 0F BD 03 00 06 00 09 00 0C 00 0F 00 15 00 21 00
					39 00 00 40 00 00 04 B0 00 61 BD
					39 00 00 40 00 00 0A BD 04 00 08 00 0C 00 10 00 74
					39 00 00 40 00 00 04 B0 00 12 BD
					39 00 00 40 00 00 02 BD 02
					39 00 00 40 00 00 04 B0 00 14 BD
					39 00 00 40 00 00 02 BD 0B       /* 0B:10hz */
					39 00 00 40 00 00 04 B0 00 16 BD
					39 00 00 40 00 00 03 BD 03 00    /* Control in Auto mode */
					39 00 00 40 00 00 02 F7 0F
					39 00 00 00 00 00 03 F0 A5 A5
				];
				mi,mdss-dsi-doze-lbm-nolp-command-state = "dsi_lp_mode";

				mi,mdss-dsi-local-hbm-hlpm-white-1000nit-command = [
					/* nolp */
					39 00 00 40 00 00 03 F0 5A 5A
					39 00 00 40 00 00 02 53 20
					39 00 00 00 22 00 03 F0 A5 A5
					/* Local HBM setting */
					39 00 00 40 00 00 03 F0 5A 5A
					39 00 00 40 00 00 04 B0 01 DC 1F
					39 00 00 40 00 00 10 1F
						02 00 00 00 00 24 09 1F 35 FA 3F 2D 09 AF 86
					39 00 00 40 00 00 04 B0 02 AC 66
					39 00 00 40 00 00 03 66 0F FF
					39 00 00 40 00 00 04 B0 01 6D 66
					39 00 00 40 00 00 13 66
						00 40 14 02 90 52 0A 41 48 1C 27 FF FF FF FF FF
						FF FF
					39 00 00 40 00 00 04 B0 01 59 66
					39 00 00 40 00 00 0B 66
						08 7A 9F F5 AF 08 7A 9F F5 AF    /* 1100nit */
					39 00 00 40 00 00 04 B0 01 B5 66
					39 00 00 40 00 00 37 66
						14 01 DE 2A 43 A2 4F 66 CC 80 08 00 80 08 00 80
						08 00 14 01 DE 2A 43 A2 4F 66 CC 80 08 00 80 08
						00 80 08 00 14 01 DE 2A 43 A2 4F 66 CC 80 08 00
						80 08 00 80 08 00
					39 00 00 40 00 00 04 B0 01 EB 66
					39 00 00 40 00 00 37 66
						14 61 EE 2A 43 A2 4F 66 CC 80 08 00 80 08 00 80
						08 00 14 61 EE 2A 43 A2 4F 66 CC 80 08 00 80 08
						00 80 08 00 14 61 EE 2A 43 A2 4F 66 CC 80 08 00
						80 08 00 80 08 00
					39 00 00 40 00 00 02 53 30    /* 0x30 Local HBM transition */
					39 00 00 00 00 00 03 F0 A5 A5
				];
				mi,mdss-dsi-local-hbm-hlpm-white-1000nit-command-state = "dsi_hs_mode";

				mi,mdss-dsi-local-hbm-hlpm-white-110nit-command = [
					/* nolp */
					39 00 00 40 00 00 03 F0 5A 5A
					39 00 00 40 00 00 02 53 20
					39 00 00 00 22 00 03 F0 A5 A5
					/* Local HBM setting */
					39 00 00 40 00 00 03 F0 5A 5A
					39 00 00 40 00 00 04 B0 01 DC 1F
					39 00 00 40 00 00 10 1F
						02 00 00 00 00 24 09 1F 35 FA 3F 2D 09 AF 86
					39 00 00 40 00 00 04 B0 02 AC 66
					39 00 00 40 00 00 03 66 0F FF
					39 00 00 40 00 00 04 B0 01 6D 66
					39 00 00 40 00 00 13 66
						00 40 14 02 90 52 0A 41 48 1C 27 FF FF FF FF FF
						FF FF
					39 00 00 40 00 00 04 B0 01 59 66
					39 00 00 40 00 00 0B 66
						05 56 E0 83 E8 05 56 E0 83 E8    /* 110nit */
					39 00 00 40 00 00 04 B0 01 B5 66
					39 00 00 40 00 00 37 66
						14 01 DE 2A 43 A2 4F 66 CC 80 08 00 80 08 00 80
						08 00 14 01 DE 2A 43 A2 4F 66 CC 80 08 00 80 08
						00 80 08 00 14 01 DE 2A 43 A2 4F 66 CC 80 08 00
						80 08 00 80 08 00
					39 00 00 40 00 00 04 B0 01 EB 66
					39 00 00 40 00 00 37 66
						14 61 EE 2A 43 A2 4F 66 CC 80 08 00 80 08 00 80
						08 00 14 61 EE 2A 43 A2 4F 66 CC 80 08 00 80 08
						00 80 08 00 14 61 EE 2A 43 A2 4F 66 CC 80 08 00
						80 08 00 80 08 00
					39 00 00 40 00 00 02 53 30    /* 0x30 Local HBM transition */
					39 00 00 00 00 00 03 F0 A5 A5
				];
				mi,mdss-dsi-local-hbm-hlpm-white-110nit-command-state = "dsi_hs_mode";

				qcom,compression-mode = "dsc";
				qcom,mdss-dsc-slice-height = <50>;
				qcom,mdss-dsc-slice-width = <720>;
				qcom,mdss-dsc-slice-per-pkt = <2>;
				qcom,mdss-dsc-bit-per-component = <10>;
				qcom,mdss-dsc-bit-per-pixel = <8>;
				qcom,mdss-dsc-block-prediction-enable;
			};

			timing@wqhd_1hz_index_07 {
				#include "dsi-panel-l2-38-0c-0a-dsc-cmd-common.dtsi"
				cell-index = <7>;
				qcom,mdss-dsi-panel-framerate = <120>;
				qcom,mdss-dsi-panel-width = <1440>;
				qcom,mdss-dsi-panel-height = <3200>;
				qcom,mdss-dsi-h-front-porch = <32>;
				qcom,mdss-dsi-h-back-porch = <32>;
				qcom,mdss-dsi-h-pulse-width = <16>;
				qcom,mdss-dsi-h-sync-skew = <1>;
				qcom,mdss-dsi-v-back-porch = <24>;
				qcom,mdss-dsi-v-front-porch = <24>;
				qcom,mdss-dsi-v-pulse-width = <8>;
				qcom,mdss-dsi-h-sync-pulse = <0>;
				qcom,mdss-dsi-h-left-border = <0>;
				qcom,mdss-dsi-h-right-border = <0>;
				qcom,mdss-dsi-v-top-border = <0>;
				qcom,mdss-dsi-v-bottom-border = <0>;
				qcom,mdss-dsi-panel-clockrate = <1360000000>;
				qcom,mdss-dsi-panel-jitter = <0x5 0x1>;
				qcom,mdss-mdp-transfer-time-us = <7300>;

				/* the cmd sequence sync TE */
				mi,mdss-dsi-exit-90fps-timing-switch-command = [
					/* CASET/PASET Setting 1440*3200 */
					39 00 00 60 00 00 05 2A 00 00 05 9F
					39 00 00 60 00 00 05 2B 00 00 0C 7F
					/* Scaler Setting 1440*3200 */
					39 00 00 60 00 00 03 F0 5A 5A
					39 00 00 60 00 00 02 C3 0C
					39 00 00 60 00 00 03 F0 A5 A5
					/* 90hz -> 120hz */
					39 00 00 60 00 00 03 F0 5A 5A
					39 00 00 60 00 00 02 60 00     /* 120hz */
					39 00 00 60 00 00 02 F7 0F
					39 00 00 20 05 00 03 F0 A5 A5  /* 1 sync */
					39 00 00 60 00 00 03 F0 5A 5A
					39 00 00 60 00 00 04 B0 00 08 CB
					39 00 00 60 00 00 02 CB 27
					39 00 00 60 00 00 02 F7 0F
					39 00 00 20 05 00 03 F0 A5 A5  /* 2 sync */
					/* FIX TE ON */
					39 00 00 60 00 00 03 F0 5A 5A
					15 00 00 60 00 00 02 B9 41     /* FIXED TE ON*/
					39 00 00 60 00 00 04 B0 00 06 B9
					39 00 00 60 00 00 07 B9 0C 9E 0C 9E 00 1D /* FIXED TE ON*/
					39 00 00 60 00 00 02 F7 0F       /* LTPS UPDATE */
					39 00 00 60 00 00 03 F0 A5 A5
					/* 1Hz Setting(force increasing on) */
					39 00 00 60 00 00 03 F0 5A 5A
					39 00 00 60 00 00 04 B0 00 08 CB
					39 00 00 60 00 00 02 CB 27
					39 00 00 60 00 00 03 BD 23 02    /* Auto mode On */
					39 00 00 60 00 00 04 B0 00 10 BD
					39 00 00 60 00 00 02 BD 10
					39 00 00 60 00 00 04 B0 00 21 BD
					39 00 00 60 00 00 0F BD 03 00 06 00 09 00 0C 00 0F 00 15 00 21 00
					39 00 00 60 00 00 04 B0 00 61 BD
					39 00 00 60 00 00 0A BD 04 00 08 00 0C 00 10 00 74
					39 00 00 60 00 00 04 B0 00 12 BD
					39 00 00 60 00 00 02 BD 02
					39 00 00 60 00 00 04 B0 00 14 BD
					39 00 00 60 00 00 02 BD 77       /* 0B:10hz, 77:1hz */
					39 00 00 60 00 00 04 B0 00 16 BD
					39 00 00 60 00 00 03 BD 0F 00    /* Control in Auto mode */
					39 00 00 60 00 00 02 F7 0F
					39 00 00 20 00 00 03 F0 A5 A5    /* 3 sync */
				];
				mi,mdss-dsi-exit-90fps-timing-switch-command-state = "dsi_hs_mode";

				qcom,mdss-dsi-timing-switch-command = [
					/* CASET/PASET Setting 1440*3200 */
					39 00 00 40 00 00 05 2A 00 00 05 9F
					39 00 00 40 00 00 05 2B 00 00 0C 7F
					/* Scaler Setting 1440*3200 */
					39 00 00 40 00 00 03 F0 5A 5A
					39 00 00 40 00 00 02 C3 0C
					39 00 00 40 00 00 03 F0 A5 A5
					/* FIX TE ON */
					39 00 00 40 00 00 03 F0 5A 5A
					15 00 00 40 00 00 02 B9 41
					39 00 00 40 00 00 04 B0 00 06 B9
					39 00 00 40 00 00 07 B9 0C 9E 0C 9E 00 1D
					39 00 00 40 00 00 02 F7 0F
					39 00 00 40 00 00 03 F0 A5 A5
					/* 1Hz Setting(force increasing on) */
					39 00 00 40 00 00 03 F0 5A 5A
					39 00 00 40 00 00 04 B0 00 08 CB
					39 00 00 40 00 00 02 CB 27
					39 00 00 40 00 00 03 BD 23 02    /* Auto mode On */
					39 00 00 40 00 00 04 B0 00 10 BD
					39 00 00 40 00 00 02 BD 10
					39 00 00 40 00 00 04 B0 00 21 BD
					39 00 00 40 00 00 0F BD 03 00 06 00 09 00 0C 00 0F 00 15 00 21 00
					39 00 00 40 00 00 04 B0 00 61 BD
					39 00 00 40 00 00 0A BD 04 00 08 00 0C 00 10 00 74
					39 00 00 40 00 00 04 B0 00 12 BD
					39 00 00 40 00 00 02 BD 02
					39 00 00 40 00 00 04 B0 00 14 BD
					39 00 00 40 00 00 02 BD 77       /* 0B:10hz, 77:1hz */
					39 00 00 40 00 00 04 B0 00 16 BD
					39 00 00 40 00 00 03 BD 0F 00    /* Control in Auto mode */
					39 00 00 40 00 00 02 F7 0F
					39 00 00 00 00 00 03 F0 A5 A5
				];
				qcom,mdss-dsi-timing-switch-command-state = "dsi_hs_mode";

				qcom,mdss-dsi-on-command = [
					/* DSC PPS Setting */
					39 00 00 00 00 00 81 9E
						11 00 00 AB 30 80 0C 80 05 A0 00 19 02 D0 02 D0
						02 00 02 68 00 20 02 BE 00 0A 00 0C 04 00 03 0D
						18 00 10 F0 07 10 20 00 06 0F 0F 33 0E 1C 2A 38
						46 54 62 69 70 77 79 7B 7D 7E 01 02 22 00 2A 40
						2A BE 3A FC 3A FA 3A F8 3B 38 3B 78 3B B6 4B F6
						4C 34 4C 74 5C 74 8C F4 00 00 00 00 00 00 00 00
						00 00 00 00 00 00 00 00 00 00 00 00 00 00 00 00
						00 00 00 00 00 00 00 00 00 00 00 00 00 00 00 00
					/* DSC Compression Enable */
					15 00 00 00 00 00 02 9D 01
					/* Sleep Out */
					05 00 00 00 78 00 02 11 00
					/* Common Setting */
					/* TE(Vsync) On */
					15 00 00 00 00 00 02 35 00
					/* CASET/PASET Setting 1440*3200 */
					39 00 00 00 00 00 05 2A 00 00 05 9F
					39 00 00 00 00 00 05 2B 00 00 0C 7F
					/* Scaler Setting 1440*3200 */
					39 00 00 40 00 00 03 F0 5A 5A
					15 00 00 40 00 00 02 C3 0C    /* 0x0C:WQHD+(1440x3200), 0x0D:FHD+(1080x2400) */
					39 00 00 00 00 00 03 F0 A5 A5
					/* FIX TE ON */
					39 00 00 40 00 00 03 F0 5A 5A
					15 00 00 40 00 00 02 B9 41
					39 00 00 40 00 00 04 B0 00 06 B9
					39 00 00 40 00 00 07 B9 0C 9E 0C 9E 00 1D
					39 00 00 40 00 00 02 F7 0F
					39 00 00 00 00 00 03 F0 A5 A5
					/* 1Hz Setting(force increasing on) */
					39 00 00 40 00 00 03 F0 5A 5A
					39 00 00 40 00 00 04 B0 00 08 CB
					39 00 00 40 00 00 02 CB 27
					39 00 00 40 00 00 03 BD 23 02   /* Auto mode On */
					39 00 00 40 00 00 04 B0 00 10 BD
					39 00 00 40 00 00 02 BD 10
					39 00 00 40 00 00 04 B0 00 21 BD
					39 00 00 40 00 00 0F BD 03 00 06 00 09 00 0C 00 0F 00 15 00 21 00
					39 00 00 40 00 00 04 B0 00 61 BD
					39 00 00 40 00 00 0A BD 04 00 08 00 0C 00 10 00 74
					39 00 00 40 00 00 04 B0 00 12 BD
					39 00 00 40 00 00 02 BD 02
					39 00 00 40 00 00 04 B0 00 14 BD
					39 00 00 40 00 00 02 BD 77       /* 0B:10hz, 77:1hz */
					39 00 00 40 00 00 04 B0 00 16 BD
					39 00 00 40 00 00 03 BD 0F 00    /* Control in Auto mode */
					//39 00 00 40 00 00 02 60 03     /* 0x00:120Hz, 0x01:60Hz, 0x03:30Hz, 0x07:10Hz */
					39 00 00 40 00 00 02 F7 0F
					39 00 00 00 00 00 03 F0 A5 A5
					/* Dimming Setting */
					39 00 00 00 00 00 03 F0 5A 5A
					39 00 00 00 00 00 04 B0 00 0D 63
					39 00 00 00 00 00 02 63 20
					39 00 00 00 00 00 04 B0 00 0C 63
					39 00 00 00 00 00 02 63 20
					39 00 00 00 00 00 03 F0 A5 A5
					39 00 00 00 00 00 02 53 20
					39 00 00 00 00 00 03 51 00 00
					39 00 00 00 00 00 02 F7 0F
					39 00 00 00 00 00 03 F0 A5 A5
					/* ESD Error Flag, Normal High, Error Low */
					39 00 00 40 00 00 03 F0 5A 5A
					39 00 00 40 00 00 04 B0 00 47 F4
					15 00 00 40 00 00 02 F4 01
					39 00 00 40 00 00 04 ED 47 05 20
					39 00 00 00 00 00 03 F0 A5 A5
					/* touch sync enable */
					39 00 00 40 00 00 03 F0 5A 5A
					39 00 00 40 00 00 03 F1 5A 5A
					39 00 00 40 00 00 04 B0 00 22 B9
					39 00 00 40 00 00 03 B9 B1 A1
					39 00 00 40 00 00 04 B0 00 05 F2
					15 00 00 40 00 00 02 F2 52
					15 00 00 40 00 00 02 F7 0F
					39 00 00 40 00 00 03 F1 A5 A5
					39 00 00 40 00 00 03 F0 A5 A5
					39 00 00 40 00 00 03 F0 5A 5A
					39 00 00 40 00 00 02 C3 0C
					39 00 00 00 00 00 03 F0 A5 A5
					/* DIA setting */
					39 00 00 40 00 00 03 F0 5A 5A
					39 00 00 40 00 00 04 B0 02 67 1D
					39 00 00 40 00 00 02 1D 81
					39 00 00 00 00 00 03 F0 A5 A5
					/* OPEC code */
					39 00 00 40 00 00 03 F0 5A 5A
					39 00 00 40 00 00 04 B0 00 52 1F
					39 00 00 40 00 00 02 1F 02
					39 00 00 40 00 00 04 B0 00 53 1F
					39 00 00 40 00 00 5F 1F
						07 01 00 02 B9 02 BA 07 A2 07 AA 12 C0 12 C1 1A
						BA 1B C0 1F E0 00 53 00 C3 03 43 07 A0 07 A1 07
						A2 07 A6 07 A8 07 AA 07 AC 07 AE 07 B0 07 B2 07
						B4 07 B6 00 03 00 A4 00 C0 00 D1 01 86 03 FF 07
						FF 30 30 35 40 35 30 40 40 35 80 80 80 0A 0F 14
						18 1E 3A 78 80 80 80 80 80 80 80 80 01 B1
					39 00 00 40 00 00 04 B0 00 78 BD
					39 00 00 40 00 00 02 BD 10
					39 00 00 00 00 00 02 F7 0F
					39 00 00 00 00 00 03 F0 A5 A5
					/* Display On */
					05 00 00 00 00 00 02 29 00
				];
				qcom,mdss-dsi-on-command-state = "dsi_lp_mode";

				qcom,mdss-dsi-nolp-command = [
					39 00 00 40 00 00 03 F0 5A 5A
					15 00 00 40 00 00 02 53 20
					39 00 00 40 00 00 03 51 00 00
					39 00 00 00 22 00 03 F0 A5 A5
					/* FIX TE ON */
					39 00 00 40 00 00 03 F0 5A 5A
					15 00 00 40 00 00 02 B9 41
					39 00 00 40 00 00 04 B0 00 06 B9
					39 00 00 40 00 00 07 B9 0C 9E 0C 9E 00 1D
					39 00 00 40 00 00 02 F7 0F
					39 00 00 40 00 00 03 F0 A5 A5
					/* 1Hz Setting(force increasing on) */
					39 00 00 40 00 00 03 F0 5A 5A
					39 00 00 40 00 00 04 B0 00 08 CB
					39 00 00 40 00 00 02 CB 27
					39 00 00 40 00 00 03 BD 23 02    /* Auto mode On */
					39 00 00 40 00 00 04 B0 00 10 BD
					39 00 00 40 00 00 02 BD 10
					39 00 00 40 00 00 04 B0 00 21 BD
					39 00 00 40 00 00 0F BD 03 00 06 00 09 00 0C 00 0F 00 15 00 21 00
					39 00 00 40 00 00 04 B0 00 61 BD
					39 00 00 40 00 00 0A BD 04 00 08 00 0C 00 10 00 74
					39 00 00 40 00 00 04 B0 00 12 BD
					39 00 00 40 00 00 02 BD 02
					39 00 00 40 00 00 04 B0 00 14 BD
					39 00 00 40 00 00 02 BD 77       /* 0B:10hz, 77:1hz */
					39 00 00 40 00 00 04 B0 00 16 BD
					39 00 00 40 00 00 03 BD 0F 00    /* Control in Auto mode */
					39 00 00 40 00 00 02 F7 0F
					39 00 00 00 00 00 03 F0 A5 A5
				];
				qcom,mdss-dsi-nolp-command-state = "dsi_lp_mode";

				mi,mdss-dsi-doze-hbm-command = [
					/* 120Hz Setting(force increasing off) */
					39 00 00 40 00 00 03 F0 5A 5A
					39 00 00 40 00 00 04 B0 00 08 CB
					39 00 00 40 00 00 02 CB 27
					39 00 00 40 00 00 03 BD 21 82
					39 00 00 40 00 00 04 B0 00 10 BD
					39 00 00 40 00 00 02 BD 00
					39 00 00 40 00 00 04 B0 00 21 BD
					39 00 00 40 00 00 0F BD 03 00 06 00 09 00 0C 00 0F 00 15 00 21 00
					39 00 00 40 00 00 04 B0 00 61 BD
					39 00 00 40 00 00 0A BD 04 00 08 00 0C 00 10 00 74
					39 00 00 40 00 00 04 B0 00 12 BD
					39 00 00 40 00 00 02 BD 01
					39 00 00 40 00 00 04 B0 00 16 BD
					39 00 00 40 00 00 03 BD 00 00    /* Step delay */
					39 00 00 40 00 00 02 BD 21       /* Manual mode */
					39 00 00 40 00 00 02 60 00       /* 0x00:120Hz, 0x01:60Hz, 0x03:30Hz, 0x07:10Hz */
					39 00 00 40 00 00 02 F7 0F
					39 00 00 00 09 00 03 F0 A5 A5
					/* AOD setting */
					39 00 00 20 00 00 03 51 00 E5
					39 00 00 20 00 00 03 51 00 E5
					39 00 00 60 00 00 03 F0 5A 5A
					39 00 00 60 00 00 02 BB 31
					39 00 00 60 00 00 02 F7 0F
					39 00 00 60 00 00 02 53 24
					39 00 00 20 00 00 03 51 07 FE
				];
				mi,mdss-dsi-doze-lbm-command = [
					/* 120Hz Setting(force increasing off) */
					39 00 00 40 00 00 03 F0 5A 5A
					39 00 00 40 00 00 04 B0 00 08 CB
					39 00 00 40 00 00 02 CB 27
					39 00 00 40 00 00 03 BD 21 82
					39 00 00 40 00 00 04 B0 00 10 BD
					39 00 00 40 00 00 02 BD 00
					39 00 00 40 00 00 04 B0 00 21 BD
					39 00 00 40 00 00 0F BD 03 00 06 00 09 00 0C 00 0F 00 15 00 21 00
					39 00 00 40 00 00 04 B0 00 61 BD
					39 00 00 40 00 00 0A BD 04 00 08 00 0C 00 10 00 74
					39 00 00 40 00 00 04 B0 00 12 BD
					39 00 00 40 00 00 02 BD 01
					39 00 00 40 00 00 04 B0 00 16 BD
					39 00 00 40 00 00 03 BD 00 00    /* Step delay */
					39 00 00 40 00 00 02 BD 21       /* Manual mode */
					39 00 00 40 00 00 02 60 00       /* 0x00:120Hz, 0x01:60Hz, 0x03:30Hz, 0x07:10Hz */
					39 00 00 40 00 00 02 F7 0F
					39 00 00 00 09 00 03 F0 A5 A5
					/* AOD setting */
					39 00 00 20 00 00 03 51 00 10
					39 00 00 20 00 00 03 51 00 10
					39 00 00 60 00 00 03 F0 5A 5A
					39 00 00 60 00 00 02 BB 31
					15 00 00 60 00 00 02 F7 0F
					39 00 00 20 00 00 02 53 24
					39 00 00 00 00 00 03 51 00 F6
				];
				/* <mipi_address  update_index  update_length> */
				mi,mdss-dsi-doze-lbm-command-update = <0x53 23 1>;
				mi,mdss-dsi-doze-hbm-command-state = "dsi_lp_mode";
				mi,mdss-dsi-doze-lbm-command-state = "dsi_lp_mode";

				mi,mdss-dsi-doze-hbm-nolp-command = [
					39 00 00 60 00 00 03 51 04 29
					39 00 00 20 23 00 02 53 20
					39 00 00 00 00 00 03 51 00 E5
					/* FIX TE ON */
					39 00 00 40 00 00 03 F0 5A 5A
					15 00 00 40 00 00 02 B9 41
					39 00 00 40 00 00 04 B0 00 06 B9
					39 00 00 40 00 00 07 B9 0C 9E 0C 9E 00 1D
					39 00 00 40 00 00 02 F7 0F
					39 00 00 40 00 00 03 F0 A5 A5
					/* 1Hz Setting(force increasing on) */
					39 00 00 40 00 00 03 F0 5A 5A
					39 00 00 40 00 00 04 B0 00 08 CB
					39 00 00 40 00 00 02 CB 27
					39 00 00 40 00 00 03 BD 23 02    /* Auto mode On */
					39 00 00 40 00 00 04 B0 00 10 BD
					39 00 00 40 00 00 02 BD 10
					39 00 00 40 00 00 04 B0 00 21 BD
					39 00 00 40 00 00 0F BD 03 00 06 00 09 00 0C 00 0F 00 15 00 21 00
					39 00 00 40 00 00 04 B0 00 61 BD
					39 00 00 40 00 00 0A BD 04 00 08 00 0C 00 10 00 74
					39 00 00 40 00 00 04 B0 00 12 BD
					39 00 00 40 00 00 02 BD 02
					39 00 00 40 00 00 04 B0 00 14 BD
					39 00 00 40 00 00 02 BD 77       /* 0B:10hz, 77:1hz */
					39 00 00 40 00 00 04 B0 00 16 BD
					39 00 00 40 00 00 03 BD 0F 00    /* Control in Auto mode */
					39 00 00 40 00 00 02 F7 0F
					39 00 00 00 00 00 03 F0 A5 A5
				];
				mi,mdss-dsi-doze-hbm-nolp-command-state = "dsi_lp_mode";

				mi,mdss-dsi-doze-lbm-nolp-command = [
				        39 00 00 40 00 00 03 F0 5A 5A
				        15 00 00 40 00 00 02 53 20
				        39 00 00 40 00 00 03 51 00 10
				        39 00 00 00 22 00 03 F0 A5 A5
					/* FIX TE ON */
					39 00 00 40 00 00 03 F0 5A 5A
					15 00 00 40 00 00 02 B9 41
					39 00 00 40 00 00 04 B0 00 06 B9
					39 00 00 40 00 00 07 B9 0C 9E 0C 9E 00 1D
					39 00 00 40 00 00 02 F7 0F
					39 00 00 40 00 00 03 F0 A5 A5
					/* 1Hz Setting(force increasing on) */
					39 00 00 40 00 00 03 F0 5A 5A
					39 00 00 40 00 00 04 B0 00 08 CB
					39 00 00 40 00 00 02 CB 27
					39 00 00 40 00 00 03 BD 23 02    /* Auto mode On */
					39 00 00 40 00 00 04 B0 00 10 BD
					39 00 00 40 00 00 02 BD 10
					39 00 00 40 00 00 04 B0 00 21 BD
					39 00 00 40 00 00 0F BD 03 00 06 00 09 00 0C 00 0F 00 15 00 21 00
					39 00 00 40 00 00 04 B0 00 61 BD
					39 00 00 40 00 00 0A BD 04 00 08 00 0C 00 10 00 74
					39 00 00 40 00 00 04 B0 00 12 BD
					39 00 00 40 00 00 02 BD 02
					39 00 00 40 00 00 04 B0 00 14 BD
					39 00 00 40 00 00 02 BD 77       /* 0B:10hz, 77:1hz */
					39 00 00 40 00 00 04 B0 00 16 BD
					39 00 00 40 00 00 03 BD 0F 00    /* Control in Auto mode */
					39 00 00 40 00 00 02 F7 0F
					39 00 00 00 00 00 03 F0 A5 A5
				];
				mi,mdss-dsi-doze-lbm-nolp-command-state = "dsi_lp_mode";

				mi,mdss-dsi-local-hbm-hlpm-white-1000nit-command = [
					/* nolp */
					39 00 00 40 00 00 03 F0 5A 5A
					39 00 00 40 00 00 02 53 20
					39 00 00 00 22 00 03 F0 A5 A5
					/* Local HBM setting */
					39 00 00 40 00 00 03 F0 5A 5A
					39 00 00 40 00 00 04 B0 01 DC 1F
					39 00 00 40 00 00 10 1F
						02 00 00 00 00 24 09 1F 35 FA 3F 2D 09 AF 86
					39 00 00 40 00 00 04 B0 02 AC 66
					39 00 00 40 00 00 03 66 0F FF
					39 00 00 40 00 00 04 B0 01 6D 66
					39 00 00 40 00 00 13 66
						00 40 14 02 90 52 0A 41 48 1C 27 FF FF FF FF FF
						FF FF
					39 00 00 40 00 00 04 B0 01 59 66
					39 00 00 40 00 00 0B 66
						08 7A 9F F5 AF 08 7A 9F F5 AF    /* 1100nit */
					39 00 00 40 00 00 04 B0 01 B5 66
					39 00 00 40 00 00 37 66
						14 01 DE 2A 43 A2 4F 66 CC 80 08 00 80 08 00 80
						08 00 14 01 DE 2A 43 A2 4F 66 CC 80 08 00 80 08
						00 80 08 00 14 01 DE 2A 43 A2 4F 66 CC 80 08 00
						80 08 00 80 08 00
					39 00 00 40 00 00 04 B0 01 EB 66
					39 00 00 40 00 00 37 66
						14 61 EE 2A 43 A2 4F 66 CC 80 08 00 80 08 00 80
						08 00 14 61 EE 2A 43 A2 4F 66 CC 80 08 00 80 08
						00 80 08 00 14 61 EE 2A 43 A2 4F 66 CC 80 08 00
						80 08 00 80 08 00
					39 00 00 40 00 00 02 53 30    /* 0x30 Local HBM transition */
					39 00 00 00 00 00 03 F0 A5 A5
				];
				mi,mdss-dsi-local-hbm-hlpm-white-1000nit-command-state = "dsi_hs_mode";

				mi,mdss-dsi-local-hbm-hlpm-white-110nit-command = [
					/* nolp */
					39 00 00 40 00 00 03 F0 5A 5A
					39 00 00 40 00 00 02 53 20
					39 00 00 00 22 00 03 F0 A5 A5
					/* Local HBM setting */
					39 00 00 40 00 00 03 F0 5A 5A
					39 00 00 40 00 00 04 B0 01 DC 1F
					39 00 00 40 00 00 10 1F
						02 00 00 00 00 24 09 1F 35 FA 3F 2D 09 AF 86
					39 00 00 40 00 00 04 B0 02 AC 66
					39 00 00 40 00 00 03 66 0F FF
					39 00 00 40 00 00 04 B0 01 6D 66
					39 00 00 40 00 00 13 66
						00 40 14 02 90 52 0A 41 48 1C 27 FF FF FF FF FF
						FF FF
					39 00 00 40 00 00 04 B0 01 59 66
					39 00 00 40 00 00 0B 66
						05 56 E0 83 E8 05 56 E0 83 E8    /* 110nit */
					39 00 00 40 00 00 04 B0 01 B5 66
					39 00 00 40 00 00 37 66
						14 01 DE 2A 43 A2 4F 66 CC 80 08 00 80 08 00 80
						08 00 14 01 DE 2A 43 A2 4F 66 CC 80 08 00 80 08
						00 80 08 00 14 01 DE 2A 43 A2 4F 66 CC 80 08 00
						80 08 00 80 08 00
					39 00 00 40 00 00 04 B0 01 EB 66
					39 00 00 40 00 00 37 66
						14 61 EE 2A 43 A2 4F 66 CC 80 08 00 80 08 00 80
						08 00 14 61 EE 2A 43 A2 4F 66 CC 80 08 00 80 08
						00 80 08 00 14 61 EE 2A 43 A2 4F 66 CC 80 08 00
						80 08 00 80 08 00
					39 00 00 40 00 00 02 53 30    /* 0x30 Local HBM transition */
					39 00 00 00 00 00 03 F0 A5 A5
				];
				mi,mdss-dsi-local-hbm-hlpm-white-110nit-command-state = "dsi_hs_mode";

				qcom,compression-mode = "dsc";
				qcom,mdss-dsc-slice-height = <50>;
				qcom,mdss-dsc-slice-width = <720>;
				qcom,mdss-dsc-slice-per-pkt = <2>;
				qcom,mdss-dsc-bit-per-component = <10>;
				qcom,mdss-dsc-bit-per-pixel = <8>;
				qcom,mdss-dsc-block-prediction-enable;
			};
		};
	};
};


